VERSION "STEPFOC V109"

NS_ :

BS_:

BU_: Host Driver0 Driver1 Driver2 Driver3 Driver4 Driver5 Driver6 Driver7 Driver8 Driver9 Driver10 Driver11 Driver12 Driver13

BO_ 4 Send_data_pack_1_N0: 8 Host
 SG_ Position_setpoint : 7|24@0- (1,0) [-8388608|8388607] "" Driver0
 SG_ Speed_feedforward : 31|24@0- (1,0) [-8388608|8388607] "" Driver0
 SG_ Current_feedforward : 55|16@0- (1,0) [-32768|32767] "" Driver0

BO_ 8 Send_data_pack_PD_N0: 8 Host
 SG_ Position_setpoint : 7|24@0- (1,0) [-8388608|8388607] "" Driver0
 SG_ Speed_setpoint : 31|24@0- (1,0) [-8388608|8388607] "" Driver0
 SG_ Current_feedforward : 55|16@0- (1,0) [-32768|32767] "" Driver0

BO_ 62 Send_data_pack_HALL_N0: 4 Host
 SG_ Speed : 7|24@0- (1,0) [-8388608|8388607] "" Driver0
 SG_ Trigger : 31|8@0+ (1,0) [0|255] "" Driver0

BO_ 6 Respond_data_pack_1_N0: 8 Driver0
 SG_ position : 7|24@0- (1,0) [-8388608|8388607] "" Host
 SG_ speed : 31|24@0- (1,0) [-8388608|8388607] "" Host
 SG_ current : 55|16@0- (1,0) [-32768|32767] "" Host

BO_ 7 Respond_data_pack_1_N0_Fault: 8 Driver0
 SG_ position : 7|24@0- (1,0) [-8388608|8388607] "" Host
 SG_ speed : 31|24@0- (1,0) [-8388608|8388607] "" Host
 SG_ current : 55|16@0- (1,0) [-32768|32767] "" Host

BO_ 64 Respond_data_hall_N0: 4 Driver0
 SG_ position : 7|24@0- (1,0) [-8388608|8388607] "" Host
 SG_ HALL_trigger : 31|1@0+ (1,0) [0|1] "" Host
 SG_ additional_pin2 : 30|1@0+ (1,0) [0|1] "" Host
 SG_ hall_index : 29|1@0+ (1,0) [0|1] "" Host

BO_ 65 Respond_data_hall_N0_Fault: 4 Driver0
 SG_ position : 7|24@0- (1,0) [-8388608|8388607] "" Host
 SG_ HALL_trigger : 31|1@0+ (1,0) [0|1] "" Host
 SG_ additional_pin2 : 30|1@0+ (1,0) [0|1] "" Host
 SG_ hall_index : 29|1@0+ (1,0) [0|1] "" Host

BO_ 32 Send_PD_Gains_N0: 8 Host
 SG_ KP : 7|32@0+ (1,0) [-3.402823466e+38|3.402823466e+38] "" Driver0
 SG_ KD : 39|32@0+ (1,0) [-3.402823466e+38|3.402823466e+38] "" Driver0

BO_ 34 Send_Current_Gains_N0: 8 Host
 SG_ Kp_iq : 7|32@0+ (1,0) [-3.402823466e+38|3.402823466e+38] "" Driver0
 SG_ Ki_iq : 39|32@0+ (1,0) [-3.402823466e+38|3.402823466e+38] "" Driver0

BO_ 36 Send_Velocity_Gains_N0: 8 Host
 SG_ Kpv : 7|32@0+ (1,0) [-3.402823466e+38|3.402823466e+38] "" Driver0
 SG_ Kiv : 39|32@0+ (1,0) [-3.402823466e+38|3.402823466e+38] "" Driver0

BO_ 38 Send_Position_Gains_N0: 4 Host
 SG_ Kpp : 7|32@0+ (1,0) [-3.402823466e+38|3.402823466e+38] "" Driver0

BO_ 40 Send_Limits_N0: 8 Host
 SG_ Speed_limit : 7|32@0+ (1,0) [-3.402823466e+38|3.402823466e+38] "" Driver0
 SG_ Current_limit : 39|32@0+ (1,0) [-3.402823466e+38|3.402823466e+38] "" Driver0

BO_ 44 Send_Kt_N0: 4 Host
 SG_ Kt : 7|32@0+ (1,0) [-3.402823466e+38|3.402823466e+38] "" Driver0

BO_ 68 Send_Voltage_Limit_N0: 4 Host
 SG_ Voltage_limit : 7|32@0- (1,0) [-2147483648|2147483647] "" Driver0

BO_ 20 Send_Respond_Ping_N0: 0 Driver0

BO_ 21 Send_Respond_Ping_N0_Fault: 0 Driver0

BO_ 46 Send_Respond_Temperature_N0: 2 Driver0
 SG_ temperature : 7|16@0- (1,0) [-32768|32767] "" Host

BO_ 47 Send_Respond_Temperatur_N0_Fault: 2 Driver0
 SG_ temperature : 7|16@0- (1,0) [-32768|32767] "" Host

BO_ 48 Send_Respond_Voltage_N0: 2 Driver0
 SG_ voltage : 7|16@0+ (1,0) [0|65535] "" Host

BO_ 49 Send_Respond_Voltage_N0_Fault: 2 Driver0
 SG_ voltage : 7|16@0+ (1,0) [0|65535] "" Host

BO_ 50 Send_Respond_Device_Info_N0: 7 Driver0
 SG_ HARDWARE_VERSION : 7|8@0+ (1,0) [0|255] "" Host
 SG_ BATCH_DATE : 15|8@0+ (1,0) [0|255] "" Host
 SG_ SOFTWARE_VERSION : 23|8@0+ (1,0) [0|255] "" Host
 SG_ SERIAL_NUMBER : 31|32@0+ (1,0) [0|4294967295] "" Host

BO_ 51 Send_Respond_Device_Inf_N0_Fault: 7 Driver0
 SG_ HARDWARE_VERSION : 7|8@0+ (1,0) [0|255] "" Host
 SG_ BATCH_DATE : 15|8@0+ (1,0) [0|255] "" Host
 SG_ SOFTWARE_VERSION : 23|8@0+ (1,0) [0|255] "" Host
 SG_ SERIAL_NUMBER : 31|32@0+ (1,0) [0|4294967295] "" Host

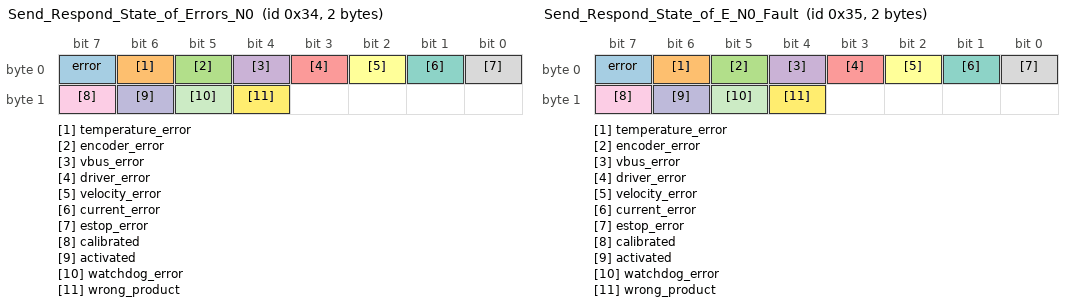
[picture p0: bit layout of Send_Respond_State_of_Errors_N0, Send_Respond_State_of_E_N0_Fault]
BO_ 52 Send_Respond_State_of_Errors_N0: 2 Driver0
 SG_ error : 7|1@0+ (1,0) [0|1] "" Host
 SG_ temperature_error : 6|1@0+ (1,0) [0|1] "" Host
 SG_ encoder_error : 5|1@0+ (1,0) [0|1] "" Host
 SG_ vbus_error : 4|1@0+ (1,0) [0|1] "" Host
 SG_ driver_error : 3|1@0+ (1,0) [0|1] "" Host
 SG_ velocity_error : 2|1@0+ (1,0) [0|1] "" Host
 SG_ current_error : 1|1@0+ (1,0) [0|1] "" Host
 SG_ estop_error : 0|1@0+ (1,0) [0|1] "" Host
 SG_ calibrated : 15|1@0+ (1,0) [0|1] "" Host
 SG_ activated : 14|1@0+ (1,0) [0|1] "" Host
 SG_ watchdog_error : 13|1@0+ (1,0) [0|1] "" Host
 SG_ wrong_product : 12|1@0+ (1,0) [0|1] "" Host

BO_ 53 Send_Respond_State_of_E_N0_Fault: 2 Driver0
 SG_ error : 7|1@0+ (1,0) [0|1] "" Host
 SG_ temperature_error : 6|1@0+ (1,0) [0|1] "" Host
 SG_ encoder_error : 5|1@0+ (1,0) [0|1] "" Host
 SG_ vbus_error : 4|1@0+ (1,0) [0|1] "" Host
 SG_ driver_error : 3|1@0+ (1,0) [0|1] "" Host
 SG_ velocity_error : 2|1@0+ (1,0) [0|1] "" Host
 SG_ current_error : 1|1@0+ (1,0) [0|1] "" Host
 SG_ estop_error : 0|1@0+ (1,0) [0|1] "" Host
 SG_ calibrated : 15|1@0+ (1,0) [0|1] "" Host
 SG_ activated : 14|1@0+ (1,0) [0|1] "" Host
 SG_ watchdog_error : 13|1@0+ (1,0) [0|1] "" Host
 SG_ wrong_product : 12|1@0+ (1,0) [0|1] "" Host

BO_ 54 Send_Respond_Iq_data_N0: 2 Driver0
 SG_ current : 7|16@0- (1,0) [-32768|32767] "" Host

BO_ 55 Send_Respond_Iq_data_N0_Fault: 2 Driver0
 SG_ current : 7|16@0- (1,0) [-32768|32767] "" Host

BO_ 56 Send_Respond_Encoder_data_N0: 8 Driver0
 SG_ position : 7|32@0- (1,0) [-2147483648|2147483647] "" Host
 SG_ speed : 39|32@0- (1,0) [-2147483648|2147483647] "" Host

BO_ 57 Send_Respond_Encoder_da_N0_Fault: 8 Driver0
 SG_ position : 7|32@0- (1,0) [-2147483648|2147483647] "" Host
 SG_ speed : 39|32@0- (1,0) [-2147483648|2147483647] "" Host

BO_ 66 Send_Respond_Kt_N0: 4 Driver0
 SG_ Kt : 7|32@0+ (1,0) [-3.402823466e+38|3.402823466e+38] "" Host

BO_ 67 Send_Respond_Kt_N0_Fault: 4 Driver0
 SG_ Kt : 7|32@0+ (1,0) [-3.402823466e+38|3.402823466e+38] "" Host

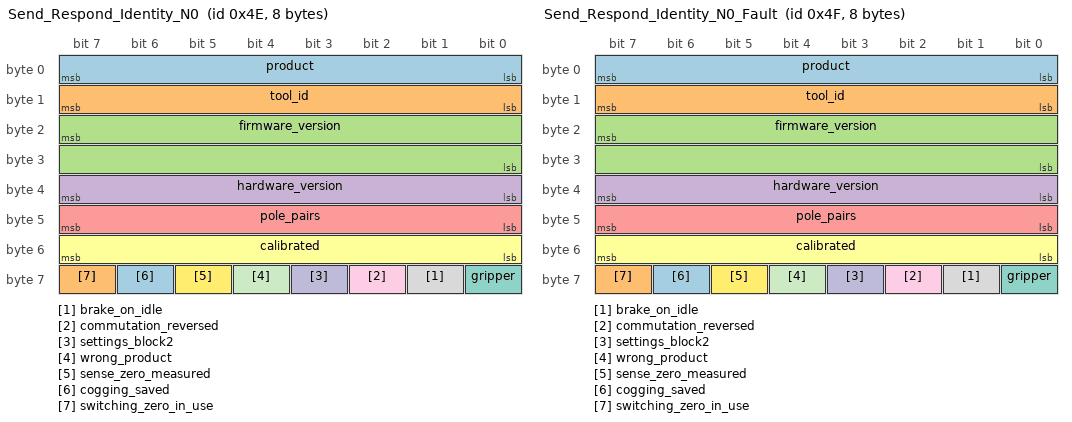
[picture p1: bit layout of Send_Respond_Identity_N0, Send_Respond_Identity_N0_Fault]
BO_ 78 Send_Respond_Identity_N0: 8 Driver0
 SG_ product : 7|8@0+ (1,0) [0|255] "" Host
 SG_ tool_id : 15|8@0+ (1,0) [0|255] "" Host
 SG_ firmware_version : 23|16@0+ (1,0) [0|65535] "" Host
 SG_ hardware_version : 39|8@0+ (1,0) [0|255] "" Host
 SG_ pole_pairs : 47|8@0+ (1,0) [0|255] "" Host
 SG_ calibrated : 55|8@0+ (1,0) [0|255] "" Host
 SG_ gripper : 56|1@0+ (1,0) [0|1] "" Host
 SG_ brake_on_idle : 57|1@0+ (1,0) [0|1] "" Host
 SG_ commutation_reversed : 58|1@0+ (1,0) [0|1] "" Host
 SG_ settings_block2 : 59|1@0+ (1,0) [0|1] "" Host
 SG_ wrong_product : 60|1@0+ (1,0) [0|1] "" Host
 SG_ sense_zero_measured : 61|1@0+ (1,0) [0|1] "" Host
 SG_ cogging_saved : 62|1@0+ (1,0) [0|1] "" Host
 SG_ switching_zero_in_use : 63|1@0+ (1,0) [0|1] "" Host

BO_ 79 Send_Respond_Identity_N0_Fault: 8 Driver0
 SG_ product : 7|8@0+ (1,0) [0|255] "" Host
 SG_ tool_id : 15|8@0+ (1,0) [0|255] "" Host
 SG_ firmware_version : 23|16@0+ (1,0) [0|65535] "" Host
 SG_ hardware_version : 39|8@0+ (1,0) [0|255] "" Host
 SG_ pole_pairs : 47|8@0+ (1,0) [0|255] "" Host
 SG_ calibrated : 55|8@0+ (1,0) [0|255] "" Host
 SG_ gripper : 56|1@0+ (1,0) [0|1] "" Host
 SG_ brake_on_idle : 57|1@0+ (1,0) [0|1] "" Host
 SG_ commutation_reversed : 58|1@0+ (1,0) [0|1] "" Host
 SG_ settings_block2 : 59|1@0+ (1,0) [0|1] "" Host
 SG_ wrong_product : 60|1@0+ (1,0) [0|1] "" Host
 SG_ sense_zero_measured : 61|1@0+ (1,0) [0|1] "" Host
 SG_ cogging_saved : 62|1@0+ (1,0) [0|1] "" Host
 SG_ switching_zero_in_use : 63|1@0+ (1,0) [0|1] "" Host

BO_ 80 Send_Respond_Telemetry_N0: 8 Driver0
 SG_ temperature : 7|16@0- (1,0) [-32768|32767] "" Host
 SG_ voltage : 23|16@0- (1,0) [-32768|32767] "" Host
 SG_ errors_1 : 39|8@0+ (1,0) [0|255] "" Host
 SG_ errors_2 : 47|8@0+ (1,0) [0|255] "" Host
 SG_ current : 55|16@0- (1,0) [-32768|32767] "" Host

BO_ 81 Send_Respond_Telemetry_N0_Fault: 8 Driver0
 SG_ temperature : 7|16@0- (1,0) [-32768|32767] "" Host
 SG_ voltage : 23|16@0- (1,0) [-32768|32767] "" Host
 SG_ errors_1 : 39|8@0+ (1,0) [0|255] "" Host
 SG_ errors_2 : 47|8@0+ (1,0) [0|255] "" Host
 SG_ current : 55|16@0- (1,0) [-32768|32767] "" Host

BO_ 18 Respond_Heartbeat_N0: 0 Driver0

BO_ 19 Respond_Heartbeat_N0_Fault: 0 Driver0

BO_ 22 Send_CAN_ID_N0: 1 Host
 SG_ ID : 7|8@0+ (1,0) [0|255] "" Driver0

BO_ 0 Send_ESTOP_N0: 0 Host

BO_ 24 Send_Idle_N0: 0 Host

BO_ 26 Send_Save_config_N0: 0 Host

BO_ 28 Send_Reset_N0: 0 Host

BO_ 2 Send_Clear_Error_N0: 0 Host

BO_ 30 Send_Watchdog_N0: 5 Host
 SG_ Time : 7|32@0+ (1,0) [0|4294967295] "" Driver0
 SG_ Action : 39|8@0+ (1,0) [0|255] "" Driver0

BO_ 60 Send_Heartbeat_Setup_N0: 4 Host
 SG_ Interval : 7|32@0+ (1,0) [0|4294967295] "" Driver0

BO_ 70 Send_Settings_N0: 2 Host
 SG_ Mask : 7|8@0+ (1,0) [0|255] "" Driver0
 SG_ Value : 15|8@0+ (1,0) [0|255] "" Driver0

BO_ 72 Send_Parameter_N0: 5 Host
 SG_ Parameter : 7|8@0+ (1,0) [0|255] "" Driver0
 SG_ Value : 15|32@0- (1,0) [-2147483648|2147483647] "" Driver0

BO_ 74 Send_Get_Parameter_N0: 1 Host
 SG_ Parameter : 7|8@0+ (1,0) [0|255] "" Driver0

BO_ 76 Respond_Parameter_N0: 5 Driver0
 SG_ parameter : 7|8@0+ (1,0) [0|255] "" Host
 SG_ value : 15|32@0- (1,0) [-2147483648|2147483647] "" Host

BO_ 77 Respond_Parameter_N0_Fault: 5 Driver0
 SG_ parameter : 7|8@0+ (1,0) [0|255] "" Host
 SG_ value : 15|32@0- (1,0) [-2147483648|2147483647] "" Host

BO_ 82 Send_Buffer_Read_N0: 5 Host
 SG_ Kind : 7|8@0+ (1,0) [0|255] "" Driver0
 SG_ First : 15|16@0+ (1,0) [0|65535] "" Driver0
 SG_ Count : 31|16@0+ (1,0) [0|65535] "" Driver0

BO_ 84 Respond_Buffer_Data_N0: 8 Driver0
 SG_ header : 7|16@0+ (1,0) [0|65535] "" Host
 SG_ word_a : 23|16@0- (1,0) [-32768|32767] "" Host
 SG_ word_b : 39|16@0- (1,0) [-32768|32767] "" Host
 SG_ word_c : 55|16@0- (1,0) [-32768|32767] "" Host

BO_ 85 Respond_Buffer_Data_N0_Fault: 8 Driver0
 SG_ header : 7|16@0+ (1,0) [0|65535] "" Host
 SG_ word_a : 23|16@0- (1,0) [-32768|32767] "" Host
 SG_ word_b : 39|16@0- (1,0) [-32768|32767] "" Host
 SG_ word_c : 55|16@0- (1,0) [-32768|32767] "" Host

BO_ 86 Send_Buffer_Write_N0: 8 Host
 SG_ Header : 7|16@0+ (1,0) [0|65535] "" Driver0
 SG_ Word_A : 23|16@0- (1,0) [-32768|32767] "" Driver0
 SG_ Word_B : 39|16@0- (1,0) [-32768|32767] "" Driver0
 SG_ Word_C : 55|16@0- (1,0) [-32768|32767] "" Driver0

BO_ 88 Send_Sound_N0: 8 Host
 SG_ Operation : 7|8@0+ (1,0) [0|255] "" Driver0
 SG_ Channel : 15|8@0+ (1,0) [0|255] "" Driver0
 SG_ A : 23|16@0+ (1,0) [0|65535] "" Driver0
 SG_ B : 39|16@0+ (1,0) [0|65535] "" Driver0
 SG_ C : 55|16@0+ (1,0) [0|65535] "" Driver0

BO_ 90 Send_Sound_Samples_N0: 8 Host
 SG_ Sample_1 : 7|8@0- (1,0) [-128|127] "" Driver0
 SG_ Sample_2 : 15|8@0- (1,0) [-128|127] "" Driver0
 SG_ Sample_3 : 23|8@0- (1,0) [-128|127] "" Driver0
 SG_ Sample_4 : 31|8@0- (1,0) [-128|127] "" Driver0
 SG_ Sample_5 : 39|8@0- (1,0) [-128|127] "" Driver0
 SG_ Sample_6 : 47|8@0- (1,0) [-128|127] "" Driver0
 SG_ Sample_7 : 55|8@0- (1,0) [-128|127] "" Driver0
 SG_ Sample_8 : 63|8@0- (1,0) [-128|127] "" Driver0

BO_ 122 Send_gripper_data_pack_N0: 5 Host
 SG_ Position : 7|8@0+ (1,0) [0|255] "" Driver0
 SG_ Speed : 15|8@0+ (1,0) [0|255] "" Driver0
 SG_ Current : 23|16@0- (1,0) [-32768|32767] "" Driver0
 SG_ Activate : 39|1@0+ (1,0) [0|1] "" Driver0
 SG_ Action : 38|1@0+ (1,0) [0|1] "" Driver0
 SG_ E_stop : 37|1@0+ (1,0) [0|1] "" Driver0
 SG_ Release_direction : 36|1@0+ (1,0) [0|1] "" Driver0

BO_ 124 Send_gripper_calibrate_N0: 0 Host

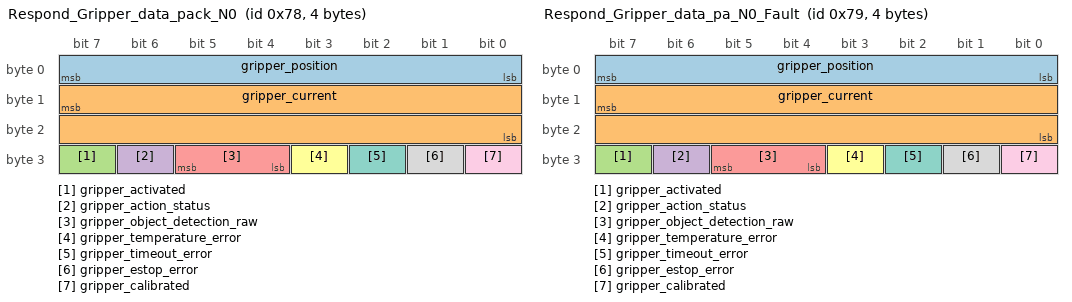
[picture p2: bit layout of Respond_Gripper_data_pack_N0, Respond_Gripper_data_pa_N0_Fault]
BO_ 120 Respond_Gripper_data_pack_N0: 4 Driver0
 SG_ gripper_position : 7|8@0+ (1,0) [0|255] "" Host
 SG_ gripper_current : 15|16@0- (1,0) [-32768|32767] "" Host
 SG_ gripper_activated : 31|1@0+ (1,0) [0|1] "" Host
 SG_ gripper_action_status : 30|1@0+ (1,0) [0|1] "" Host
 SG_ gripper_object_detection_raw : 29|2@0+ (1,0) [0|3] "" Host
 SG_ gripper_temperature_error : 27|1@0+ (1,0) [0|1] "" Host
 SG_ gripper_timeout_error : 26|1@0+ (1,0) [0|1] "" Host
 SG_ gripper_estop_error : 25|1@0+ (1,0) [0|1] "" Host
 SG_ gripper_calibrated : 24|1@0+ (1,0) [0|1] "" Host

BO_ 121 Respond_Gripper_data_pa_N0_Fault: 4 Driver0
 SG_ gripper_position : 7|8@0+ (1,0) [0|255] "" Host
 SG_ gripper_current : 15|16@0- (1,0) [-32768|32767] "" Host
 SG_ gripper_activated : 31|1@0+ (1,0) [0|1] "" Host
 SG_ gripper_action_status : 30|1@0+ (1,0) [0|1] "" Host
 SG_ gripper_object_detection_raw : 29|2@0+ (1,0) [0|3] "" Host
 SG_ gripper_temperature_error : 27|1@0+ (1,0) [0|1] "" Host
 SG_ gripper_timeout_error : 26|1@0+ (1,0) [0|1] "" Host
 SG_ gripper_estop_error : 25|1@0+ (1,0) [0|1] "" Host
 SG_ gripper_calibrated : 24|1@0+ (1,0) [0|1] "" Host

BO_ 132 Send_data_pack_1_N1: 8 Host
 SG_ Position_setpoint : 7|24@0- (1,0) [-8388608|8388607] "" Driver1
 SG_ Speed_feedforward : 31|24@0- (1,0) [-8388608|8388607] "" Driver1
 SG_ Current_feedforward : 55|16@0- (1,0) [-32768|32767] "" Driver1

BO_ 136 Send_data_pack_PD_N1: 8 Host
 SG_ Position_setpoint : 7|24@0- (1,0) [-8388608|8388607] "" Driver1
 SG_ Speed_setpoint : 31|24@0- (1,0) [-8388608|8388607] "" Driver1
 SG_ Current_feedforward : 55|16@0- (1,0) [-32768|32767] "" Driver1

BO_ 190 Send_data_pack_HALL_N1: 4 Host
 SG_ Speed : 7|24@0- (1,0) [-8388608|8388607] "" Driver1
 SG_ Trigger : 31|8@0+ (1,0) [0|255] "" Driver1

BO_ 134 Respond_data_pack_1_N1: 8 Driver1
 SG_ position : 7|24@0- (1,0) [-8388608|8388607] "" Host
 SG_ speed : 31|24@0- (1,0) [-8388608|8388607] "" Host
 SG_ current : 55|16@0- (1,0) [-32768|32767] "" Host

BO_ 135 Respond_data_pack_1_N1_Fault: 8 Driver1
 SG_ position : 7|24@0- (1,0) [-8388608|8388607] "" Host
 SG_ speed : 31|24@0- (1,0) [-8388608|8388607] "" Host
 SG_ current : 55|16@0- (1,0) [-32768|32767] "" Host

BO_ 192 Respond_data_hall_N1: 4 Driver1
 SG_ position : 7|24@0- (1,0) [-8388608|8388607] "" Host
 SG_ HALL_trigger : 31|1@0+ (1,0) [0|1] "" Host
 SG_ additional_pin2 : 30|1@0+ (1,0) [0|1] "" Host
 SG_ hall_index : 29|1@0+ (1,0) [0|1] "" Host

BO_ 193 Respond_data_hall_N1_Fault: 4 Driver1
 SG_ position : 7|24@0- (1,0) [-8388608|8388607] "" Host
 SG_ HALL_trigger : 31|1@0+ (1,0) [0|1] "" Host
 SG_ additional_pin2 : 30|1@0+ (1,0) [0|1] "" Host
 SG_ hall_index : 29|1@0+ (1,0) [0|1] "" Host

BO_ 160 Send_PD_Gains_N1: 8 Host
 SG_ KP : 7|32@0+ (1,0) [-3.402823466e+38|3.402823466e+38] "" Driver1
 SG_ KD : 39|32@0+ (1,0) [-3.402823466e+38|3.402823466e+38] "" Driver1

BO_ 162 Send_Current_Gains_N1: 8 Host
 SG_ Kp_iq : 7|32@0+ (1,0) [-3.402823466e+38|3.402823466e+38] "" Driver1
 SG_ Ki_iq : 39|32@0+ (1,0) [-3.402823466e+38|3.402823466e+38] "" Driver1

BO_ 164 Send_Velocity_Gains_N1: 8 Host
 SG_ Kpv : 7|32@0+ (1,0) [-3.402823466e+38|3.402823466e+38] "" Driver1
 SG_ Kiv : 39|32@0+ (1,0) [-3.402823466e+38|3.402823466e+38] "" Driver1

BO_ 166 Send_Position_Gains_N1: 4 Host
 SG_ Kpp : 7|32@0+ (1,0) [-3.402823466e+38|3.402823466e+38] "" Driver1

BO_ 168 Send_Limits_N1: 8 Host
 SG_ Speed_limit : 7|32@0+ (1,0) [-3.402823466e+38|3.402823466e+38] "" Driver1
 SG_ Current_limit : 39|32@0+ (1,0) [-3.402823466e+38|3.402823466e+38] "" Driver1

BO_ 172 Send_Kt_N1: 4 Host
 SG_ Kt : 7|32@0+ (1,0) [-3.402823466e+38|3.402823466e+38] "" Driver1

BO_ 196 Send_Voltage_Limit_N1: 4 Host
 SG_ Voltage_limit : 7|32@0- (1,0) [-2147483648|2147483647] "" Driver1

BO_ 148 Send_Respond_Ping_N1: 0 Driver1

BO_ 149 Send_Respond_Ping_N1_Fault: 0 Driver1

BO_ 174 Send_Respond_Temperature_N1: 2 Driver1
 SG_ temperature : 7|16@0- (1,0) [-32768|32767] "" Host

BO_ 175 Send_Respond_Temperatur_N1_Fault: 2 Driver1
 SG_ temperature : 7|16@0- (1,0) [-32768|32767] "" Host

BO_ 176 Send_Respond_Voltage_N1: 2 Driver1
 SG_ voltage : 7|16@0+ (1,0) [0|65535] "" Host

BO_ 177 Send_Respond_Voltage_N1_Fault: 2 Driver1
 SG_ voltage : 7|16@0+ (1,0) [0|65535] "" Host

BO_ 178 Send_Respond_Device_Info_N1: 7 Driver1
 SG_ HARDWARE_VERSION : 7|8@0+ (1,0) [0|255] "" Host
 SG_ BATCH_DATE : 15|8@0+ (1,0) [0|255] "" Host
 SG_ SOFTWARE_VERSION : 23|8@0+ (1,0) [0|255] "" Host
 SG_ SERIAL_NUMBER : 31|32@0+ (1,0) [0|4294967295] "" Host

BO_ 179 Send_Respond_Device_Inf_N1_Fault: 7 Driver1
 SG_ HARDWARE_VERSION : 7|8@0+ (1,0) [0|255] "" Host
 SG_ BATCH_DATE : 15|8@0+ (1,0) [0|255] "" Host
 SG_ SOFTWARE_VERSION : 23|8@0+ (1,0) [0|255] "" Host
 SG_ SERIAL_NUMBER : 31|32@0+ (1,0) [0|4294967295] "" Host

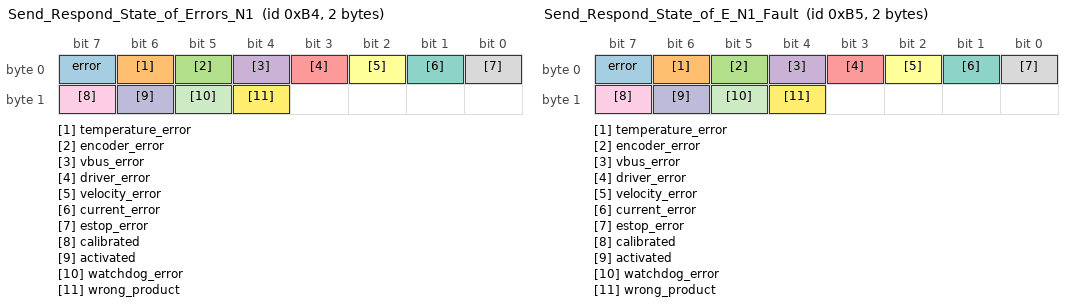
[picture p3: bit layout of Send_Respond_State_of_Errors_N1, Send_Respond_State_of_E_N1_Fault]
BO_ 180 Send_Respond_State_of_Errors_N1: 2 Driver1
 SG_ error : 7|1@0+ (1,0) [0|1] "" Host
 SG_ temperature_error : 6|1@0+ (1,0) [0|1] "" Host
 SG_ encoder_error : 5|1@0+ (1,0) [0|1] "" Host
 SG_ vbus_error : 4|1@0+ (1,0) [0|1] "" Host
 SG_ driver_error : 3|1@0+ (1,0) [0|1] "" Host
 SG_ velocity_error : 2|1@0+ (1,0) [0|1] "" Host
 SG_ current_error : 1|1@0+ (1,0) [0|1] "" Host
 SG_ estop_error : 0|1@0+ (1,0) [0|1] "" Host
 SG_ calibrated : 15|1@0+ (1,0) [0|1] "" Host
 SG_ activated : 14|1@0+ (1,0) [0|1] "" Host
 SG_ watchdog_error : 13|1@0+ (1,0) [0|1] "" Host
 SG_ wrong_product : 12|1@0+ (1,0) [0|1] "" Host

BO_ 181 Send_Respond_State_of_E_N1_Fault: 2 Driver1
 SG_ error : 7|1@0+ (1,0) [0|1] "" Host
 SG_ temperature_error : 6|1@0+ (1,0) [0|1] "" Host
 SG_ encoder_error : 5|1@0+ (1,0) [0|1] "" Host
 SG_ vbus_error : 4|1@0+ (1,0) [0|1] "" Host
 SG_ driver_error : 3|1@0+ (1,0) [0|1] "" Host
 SG_ velocity_error : 2|1@0+ (1,0) [0|1] "" Host
 SG_ current_error : 1|1@0+ (1,0) [0|1] "" Host
 SG_ estop_error : 0|1@0+ (1,0) [0|1] "" Host
 SG_ calibrated : 15|1@0+ (1,0) [0|1] "" Host
 SG_ activated : 14|1@0+ (1,0) [0|1] "" Host
 SG_ watchdog_error : 13|1@0+ (1,0) [0|1] "" Host
 SG_ wrong_product : 12|1@0+ (1,0) [0|1] "" Host

BO_ 182 Send_Respond_Iq_data_N1: 2 Driver1
 SG_ current : 7|16@0- (1,0) [-32768|32767] "" Host

BO_ 183 Send_Respond_Iq_data_N1_Fault: 2 Driver1
 SG_ current : 7|16@0- (1,0) [-32768|32767] "" Host

BO_ 184 Send_Respond_Encoder_data_N1: 8 Driver1
 SG_ position : 7|32@0- (1,0) [-2147483648|2147483647] "" Host
 SG_ speed : 39|32@0- (1,0) [-2147483648|2147483647] "" Host

BO_ 185 Send_Respond_Encoder_da_N1_Fault: 8 Driver1
 SG_ position : 7|32@0- (1,0) [-2147483648|2147483647] "" Host
 SG_ speed : 39|32@0- (1,0) [-2147483648|2147483647] "" Host

BO_ 194 Send_Respond_Kt_N1: 4 Driver1
 SG_ Kt : 7|32@0+ (1,0) [-3.402823466e+38|3.402823466e+38] "" Host

BO_ 195 Send_Respond_Kt_N1_Fault: 4 Driver1
 SG_ Kt : 7|32@0+ (1,0) [-3.402823466e+38|3.402823466e+38] "" Host

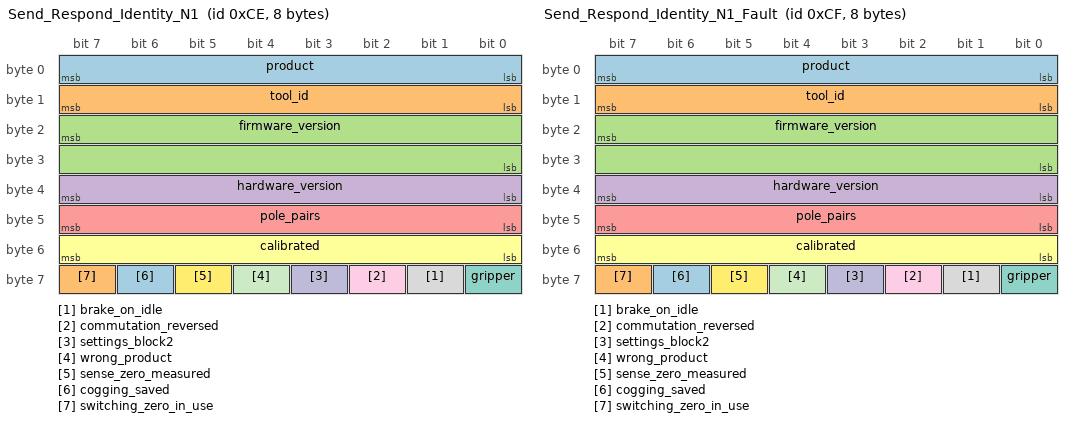
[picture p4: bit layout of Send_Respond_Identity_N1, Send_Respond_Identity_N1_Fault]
BO_ 206 Send_Respond_Identity_N1: 8 Driver1
 SG_ product : 7|8@0+ (1,0) [0|255] "" Host
 SG_ tool_id : 15|8@0+ (1,0) [0|255] "" Host
 SG_ firmware_version : 23|16@0+ (1,0) [0|65535] "" Host
 SG_ hardware_version : 39|8@0+ (1,0) [0|255] "" Host
 SG_ pole_pairs : 47|8@0+ (1,0) [0|255] "" Host
 SG_ calibrated : 55|8@0+ (1,0) [0|255] "" Host
 SG_ gripper : 56|1@0+ (1,0) [0|1] "" Host
 SG_ brake_on_idle : 57|1@0+ (1,0) [0|1] "" Host
 SG_ commutation_reversed : 58|1@0+ (1,0) [0|1] "" Host
 SG_ settings_block2 : 59|1@0+ (1,0) [0|1] "" Host
 SG_ wrong_product : 60|1@0+ (1,0) [0|1] "" Host
 SG_ sense_zero_measured : 61|1@0+ (1,0) [0|1] "" Host
 SG_ cogging_saved : 62|1@0+ (1,0) [0|1] "" Host
 SG_ switching_zero_in_use : 63|1@0+ (1,0) [0|1] "" Host

BO_ 207 Send_Respond_Identity_N1_Fault: 8 Driver1
 SG_ product : 7|8@0+ (1,0) [0|255] "" Host
 SG_ tool_id : 15|8@0+ (1,0) [0|255] "" Host
 SG_ firmware_version : 23|16@0+ (1,0) [0|65535] "" Host
 SG_ hardware_version : 39|8@0+ (1,0) [0|255] "" Host
 SG_ pole_pairs : 47|8@0+ (1,0) [0|255] "" Host
 SG_ calibrated : 55|8@0+ (1,0) [0|255] "" Host
 SG_ gripper : 56|1@0+ (1,0) [0|1] "" Host
 SG_ brake_on_idle : 57|1@0+ (1,0) [0|1] "" Host
 SG_ commutation_reversed : 58|1@0+ (1,0) [0|1] "" Host
 SG_ settings_block2 : 59|1@0+ (1,0) [0|1] "" Host
 SG_ wrong_product : 60|1@0+ (1,0) [0|1] "" Host
 SG_ sense_zero_measured : 61|1@0+ (1,0) [0|1] "" Host
 SG_ cogging_saved : 62|1@0+ (1,0) [0|1] "" Host
 SG_ switching_zero_in_use : 63|1@0+ (1,0) [0|1] "" Host

BO_ 208 Send_Respond_Telemetry_N1: 8 Driver1
 SG_ temperature : 7|16@0- (1,0) [-32768|32767] "" Host
 SG_ voltage : 23|16@0- (1,0) [-32768|32767] "" Host
 SG_ errors_1 : 39|8@0+ (1,0) [0|255] "" Host
 SG_ errors_2 : 47|8@0+ (1,0) [0|255] "" Host
 SG_ current : 55|16@0- (1,0) [-32768|32767] "" Host

BO_ 209 Send_Respond_Telemetry_N1_Fault: 8 Driver1
 SG_ temperature : 7|16@0- (1,0) [-32768|32767] "" Host
 SG_ voltage : 23|16@0- (1,0) [-32768|32767] "" Host
 SG_ errors_1 : 39|8@0+ (1,0) [0|255] "" Host
 SG_ errors_2 : 47|8@0+ (1,0) [0|255] "" Host
 SG_ current : 55|16@0- (1,0) [-32768|32767] "" Host

BO_ 146 Respond_Heartbeat_N1: 0 Driver1

BO_ 147 Respond_Heartbeat_N1_Fault: 0 Driver1

BO_ 150 Send_CAN_ID_N1: 1 Host
 SG_ ID : 7|8@0+ (1,0) [0|255] "" Driver1

BO_ 128 Send_ESTOP_N1: 0 Host

BO_ 152 Send_Idle_N1: 0 Host

BO_ 154 Send_Save_config_N1: 0 Host

BO_ 156 Send_Reset_N1: 0 Host

BO_ 130 Send_Clear_Error_N1: 0 Host

BO_ 158 Send_Watchdog_N1: 5 Host
 SG_ Time : 7|32@0+ (1,0) [0|4294967295] "" Driver1
 SG_ Action : 39|8@0+ (1,0) [0|255] "" Driver1

BO_ 188 Send_Heartbeat_Setup_N1: 4 Host
 SG_ Interval : 7|32@0+ (1,0) [0|4294967295] "" Driver1

BO_ 198 Send_Settings_N1: 2 Host
 SG_ Mask : 7|8@0+ (1,0) [0|255] "" Driver1
 SG_ Value : 15|8@0+ (1,0) [0|255] "" Driver1

BO_ 200 Send_Parameter_N1: 5 Host
 SG_ Parameter : 7|8@0+ (1,0) [0|255] "" Driver1
 SG_ Value : 15|32@0- (1,0) [-2147483648|2147483647] "" Driver1

BO_ 202 Send_Get_Parameter_N1: 1 Host
 SG_ Parameter : 7|8@0+ (1,0) [0|255] "" Driver1

BO_ 204 Respond_Parameter_N1: 5 Driver1
 SG_ parameter : 7|8@0+ (1,0) [0|255] "" Host
 SG_ value : 15|32@0- (1,0) [-2147483648|2147483647] "" Host

BO_ 205 Respond_Parameter_N1_Fault: 5 Driver1
 SG_ parameter : 7|8@0+ (1,0) [0|255] "" Host
 SG_ value : 15|32@0- (1,0) [-2147483648|2147483647] "" Host

BO_ 210 Send_Buffer_Read_N1: 5 Host
 SG_ Kind : 7|8@0+ (1,0) [0|255] "" Driver1
 SG_ First : 15|16@0+ (1,0) [0|65535] "" Driver1
 SG_ Count : 31|16@0+ (1,0) [0|65535] "" Driver1

BO_ 212 Respond_Buffer_Data_N1: 8 Driver1
 SG_ header : 7|16@0+ (1,0) [0|65535] "" Host
 SG_ word_a : 23|16@0- (1,0) [-32768|32767] "" Host
 SG_ word_b : 39|16@0- (1,0) [-32768|32767] "" Host
 SG_ word_c : 55|16@0- (1,0) [-32768|32767] "" Host

BO_ 213 Respond_Buffer_Data_N1_Fault: 8 Driver1
 SG_ header : 7|16@0+ (1,0) [0|65535] "" Host
 SG_ word_a : 23|16@0- (1,0) [-32768|32767] "" Host
 SG_ word_b : 39|16@0- (1,0) [-32768|32767] "" Host
 SG_ word_c : 55|16@0- (1,0) [-32768|32767] "" Host

BO_ 214 Send_Buffer_Write_N1: 8 Host
 SG_ Header : 7|16@0+ (1,0) [0|65535] "" Driver1
 SG_ Word_A : 23|16@0- (1,0) [-32768|32767] "" Driver1
 SG_ Word_B : 39|16@0- (1,0) [-32768|32767] "" Driver1
 SG_ Word_C : 55|16@0- (1,0) [-32768|32767] "" Driver1

BO_ 216 Send_Sound_N1: 8 Host
 SG_ Operation : 7|8@0+ (1,0) [0|255] "" Driver1
 SG_ Channel : 15|8@0+ (1,0) [0|255] "" Driver1
 SG_ A : 23|16@0+ (1,0) [0|65535] "" Driver1
 SG_ B : 39|16@0+ (1,0) [0|65535] "" Driver1
 SG_ C : 55|16@0+ (1,0) [0|65535] "" Driver1

BO_ 218 Send_Sound_Samples_N1: 8 Host
 SG_ Sample_1 : 7|8@0- (1,0) [-128|127] "" Driver1
 SG_ Sample_2 : 15|8@0- (1,0) [-128|127] "" Driver1
 SG_ Sample_3 : 23|8@0- (1,0) [-128|127] "" Driver1
 SG_ Sample_4 : 31|8@0- (1,0) [-128|127] "" Driver1
 SG_ Sample_5 : 39|8@0- (1,0) [-128|127] "" Driver1
 SG_ Sample_6 : 47|8@0- (1,0) [-128|127] "" Driver1
 SG_ Sample_7 : 55|8@0- (1,0) [-128|127] "" Driver1
 SG_ Sample_8 : 63|8@0- (1,0) [-128|127] "" Driver1

BO_ 250 Send_gripper_data_pack_N1: 5 Host
 SG_ Position : 7|8@0+ (1,0) [0|255] "" Driver1
 SG_ Speed : 15|8@0+ (1,0) [0|255] "" Driver1
 SG_ Current : 23|16@0- (1,0) [-32768|32767] "" Driver1
 SG_ Activate : 39|1@0+ (1,0) [0|1] "" Driver1
 SG_ Action : 38|1@0+ (1,0) [0|1] "" Driver1
 SG_ E_stop : 37|1@0+ (1,0) [0|1] "" Driver1
 SG_ Release_direction : 36|1@0+ (1,0) [0|1] "" Driver1

BO_ 252 Send_gripper_calibrate_N1: 0 Host

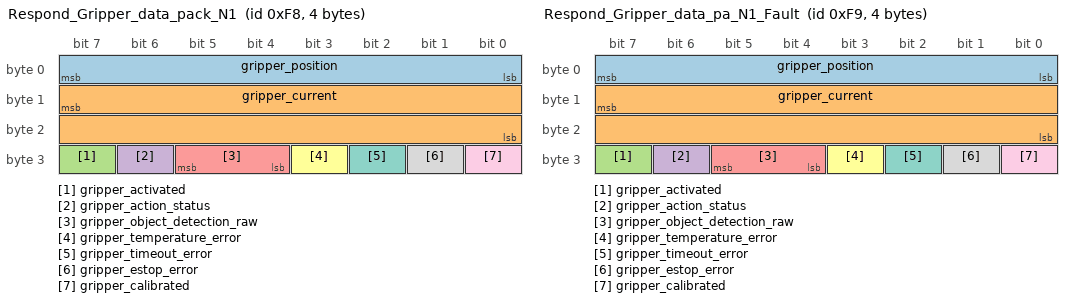
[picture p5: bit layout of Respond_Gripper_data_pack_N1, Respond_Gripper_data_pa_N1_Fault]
BO_ 248 Respond_Gripper_data_pack_N1: 4 Driver1
 SG_ gripper_position : 7|8@0+ (1,0) [0|255] "" Host
 SG_ gripper_current : 15|16@0- (1,0) [-32768|32767] "" Host
 SG_ gripper_activated : 31|1@0+ (1,0) [0|1] "" Host
 SG_ gripper_action_status : 30|1@0+ (1,0) [0|1] "" Host
 SG_ gripper_object_detection_raw : 29|2@0+ (1,0) [0|3] "" Host
 SG_ gripper_temperature_error : 27|1@0+ (1,0) [0|1] "" Host
 SG_ gripper_timeout_error : 26|1@0+ (1,0) [0|1] "" Host
 SG_ gripper_estop_error : 25|1@0+ (1,0) [0|1] "" Host
 SG_ gripper_calibrated : 24|1@0+ (1,0) [0|1] "" Host

BO_ 249 Respond_Gripper_data_pa_N1_Fault: 4 Driver1
 SG_ gripper_position : 7|8@0+ (1,0) [0|255] "" Host
 SG_ gripper_current : 15|16@0- (1,0) [-32768|32767] "" Host
 SG_ gripper_activated : 31|1@0+ (1,0) [0|1] "" Host
 SG_ gripper_action_status : 30|1@0+ (1,0) [0|1] "" Host
 SG_ gripper_object_detection_raw : 29|2@0+ (1,0) [0|3] "" Host
 SG_ gripper_temperature_error : 27|1@0+ (1,0) [0|1] "" Host
 SG_ gripper_timeout_error : 26|1@0+ (1,0) [0|1] "" Host
 SG_ gripper_estop_error : 25|1@0+ (1,0) [0|1] "" Host
 SG_ gripper_calibrated : 24|1@0+ (1,0) [0|1] "" Host

BO_ 260 Send_data_pack_1_N2: 8 Host
 SG_ Position_setpoint : 7|24@0- (1,0) [-8388608|8388607] "" Driver2
 SG_ Speed_feedforward : 31|24@0- (1,0) [-8388608|8388607] "" Driver2
 SG_ Current_feedforward : 55|16@0- (1,0) [-32768|32767] "" Driver2

BO_ 264 Send_data_pack_PD_N2: 8 Host
 SG_ Position_setpoint : 7|24@0- (1,0) [-8388608|8388607] "" Driver2
 SG_ Speed_setpoint : 31|24@0- (1,0) [-8388608|8388607] "" Driver2
 SG_ Current_feedforward : 55|16@0- (1,0) [-32768|32767] "" Driver2

BO_ 318 Send_data_pack_HALL_N2: 4 Host
 SG_ Speed : 7|24@0- (1,0) [-8388608|8388607] "" Driver2
 SG_ Trigger : 31|8@0+ (1,0) [0|255] "" Driver2

BO_ 262 Respond_data_pack_1_N2: 8 Driver2
 SG_ position : 7|24@0- (1,0) [-8388608|8388607] "" Host
 SG_ speed : 31|24@0- (1,0) [-8388608|8388607] "" Host
 SG_ current : 55|16@0- (1,0) [-32768|32767] "" Host

BO_ 263 Respond_data_pack_1_N2_Fault: 8 Driver2
 SG_ position : 7|24@0- (1,0) [-8388608|8388607] "" Host
 SG_ speed : 31|24@0- (1,0) [-8388608|8388607] "" Host
 SG_ current : 55|16@0- (1,0) [-32768|32767] "" Host

BO_ 320 Respond_data_hall_N2: 4 Driver2
 SG_ position : 7|24@0- (1,0) [-8388608|8388607] "" Host
 SG_ HALL_trigger : 31|1@0+ (1,0) [0|1] "" Host
 SG_ additional_pin2 : 30|1@0+ (1,0) [0|1] "" Host
 SG_ hall_index : 29|1@0+ (1,0) [0|1] "" Host

BO_ 321 Respond_data_hall_N2_Fault: 4 Driver2
 SG_ position : 7|24@0- (1,0) [-8388608|8388607] "" Host
 SG_ HALL_trigger : 31|1@0+ (1,0) [0|1] "" Host
 SG_ additional_pin2 : 30|1@0+ (1,0) [0|1] "" Host
 SG_ hall_index : 29|1@0+ (1,0) [0|1] "" Host

BO_ 288 Send_PD_Gains_N2: 8 Host
 SG_ KP : 7|32@0+ (1,0) [-3.402823466e+38|3.402823466e+38] "" Driver2
 SG_ KD : 39|32@0+ (1,0) [-3.402823466e+38|3.402823466e+38] "" Driver2

BO_ 290 Send_Current_Gains_N2: 8 Host
 SG_ Kp_iq : 7|32@0+ (1,0) [-3.402823466e+38|3.402823466e+38] "" Driver2
 SG_ Ki_iq : 39|32@0+ (1,0) [-3.402823466e+38|3.402823466e+38] "" Driver2

BO_ 292 Send_Velocity_Gains_N2: 8 Host
 SG_ Kpv : 7|32@0+ (1,0) [-3.402823466e+38|3.402823466e+38] "" Driver2
 SG_ Kiv : 39|32@0+ (1,0) [-3.402823466e+38|3.402823466e+38] "" Driver2

BO_ 294 Send_Position_Gains_N2: 4 Host
 SG_ Kpp : 7|32@0+ (1,0) [-3.402823466e+38|3.402823466e+38] "" Driver2

BO_ 296 Send_Limits_N2: 8 Host
 SG_ Speed_limit : 7|32@0+ (1,0) [-3.402823466e+38|3.402823466e+38] "" Driver2
 SG_ Current_limit : 39|32@0+ (1,0) [-3.402823466e+38|3.402823466e+38] "" Driver2

BO_ 300 Send_Kt_N2: 4 Host
 SG_ Kt : 7|32@0+ (1,0) [-3.402823466e+38|3.402823466e+38] "" Driver2

BO_ 324 Send_Voltage_Limit_N2: 4 Host
 SG_ Voltage_limit : 7|32@0- (1,0) [-2147483648|2147483647] "" Driver2

BO_ 276 Send_Respond_Ping_N2: 0 Driver2

BO_ 277 Send_Respond_Ping_N2_Fault: 0 Driver2

BO_ 302 Send_Respond_Temperature_N2: 2 Driver2
 SG_ temperature : 7|16@0- (1,0) [-32768|32767] "" Host

BO_ 303 Send_Respond_Temperatur_N2_Fault: 2 Driver2
 SG_ temperature : 7|16@0- (1,0) [-32768|32767] "" Host

BO_ 304 Send_Respond_Voltage_N2: 2 Driver2
 SG_ voltage : 7|16@0+ (1,0) [0|65535] "" Host

BO_ 305 Send_Respond_Voltage_N2_Fault: 2 Driver2
 SG_ voltage : 7|16@0+ (1,0) [0|65535] "" Host

BO_ 306 Send_Respond_Device_Info_N2: 7 Driver2
 SG_ HARDWARE_VERSION : 7|8@0+ (1,0) [0|255] "" Host
 SG_ BATCH_DATE : 15|8@0+ (1,0) [0|255] "" Host
 SG_ SOFTWARE_VERSION : 23|8@0+ (1,0) [0|255] "" Host
 SG_ SERIAL_NUMBER : 31|32@0+ (1,0) [0|4294967295] "" Host

BO_ 307 Send_Respond_Device_Inf_N2_Fault: 7 Driver2
 SG_ HARDWARE_VERSION : 7|8@0+ (1,0) [0|255] "" Host
 SG_ BATCH_DATE : 15|8@0+ (1,0) [0|255] "" Host
 SG_ SOFTWARE_VERSION : 23|8@0+ (1,0) [0|255] "" Host
 SG_ SERIAL_NUMBER : 31|32@0+ (1,0) [0|4294967295] "" Host

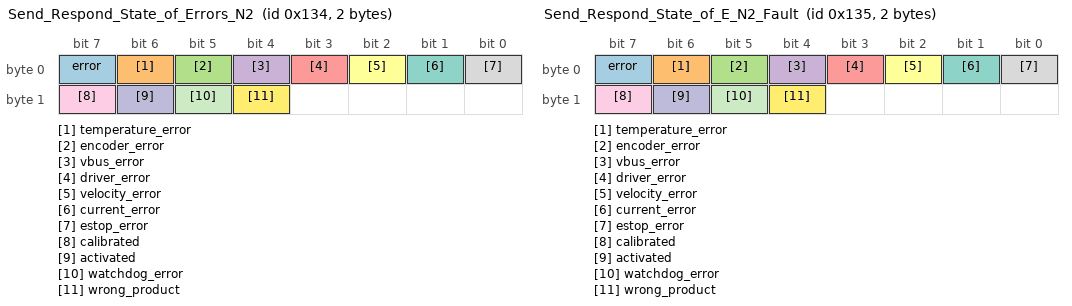
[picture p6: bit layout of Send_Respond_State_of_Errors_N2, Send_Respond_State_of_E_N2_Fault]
BO_ 308 Send_Respond_State_of_Errors_N2: 2 Driver2
 SG_ error : 7|1@0+ (1,0) [0|1] "" Host
 SG_ temperature_error : 6|1@0+ (1,0) [0|1] "" Host
 SG_ encoder_error : 5|1@0+ (1,0) [0|1] "" Host
 SG_ vbus_error : 4|1@0+ (1,0) [0|1] "" Host
 SG_ driver_error : 3|1@0+ (1,0) [0|1] "" Host
 SG_ velocity_error : 2|1@0+ (1,0) [0|1] "" Host
 SG_ current_error : 1|1@0+ (1,0) [0|1] "" Host
 SG_ estop_error : 0|1@0+ (1,0) [0|1] "" Host
 SG_ calibrated : 15|1@0+ (1,0) [0|1] "" Host
 SG_ activated : 14|1@0+ (1,0) [0|1] "" Host
 SG_ watchdog_error : 13|1@0+ (1,0) [0|1] "" Host
 SG_ wrong_product : 12|1@0+ (1,0) [0|1] "" Host

BO_ 309 Send_Respond_State_of_E_N2_Fault: 2 Driver2
 SG_ error : 7|1@0+ (1,0) [0|1] "" Host
 SG_ temperature_error : 6|1@0+ (1,0) [0|1] "" Host
 SG_ encoder_error : 5|1@0+ (1,0) [0|1] "" Host
 SG_ vbus_error : 4|1@0+ (1,0) [0|1] "" Host
 SG_ driver_error : 3|1@0+ (1,0) [0|1] "" Host
 SG_ velocity_error : 2|1@0+ (1,0) [0|1] "" Host
 SG_ current_error : 1|1@0+ (1,0) [0|1] "" Host
 SG_ estop_error : 0|1@0+ (1,0) [0|1] "" Host
 SG_ calibrated : 15|1@0+ (1,0) [0|1] "" Host
 SG_ activated : 14|1@0+ (1,0) [0|1] "" Host
 SG_ watchdog_error : 13|1@0+ (1,0) [0|1] "" Host
 SG_ wrong_product : 12|1@0+ (1,0) [0|1] "" Host

BO_ 310 Send_Respond_Iq_data_N2: 2 Driver2
 SG_ current : 7|16@0- (1,0) [-32768|32767] "" Host

BO_ 311 Send_Respond_Iq_data_N2_Fault: 2 Driver2
 SG_ current : 7|16@0- (1,0) [-32768|32767] "" Host

BO_ 312 Send_Respond_Encoder_data_N2: 8 Driver2
 SG_ position : 7|32@0- (1,0) [-2147483648|2147483647] "" Host
 SG_ speed : 39|32@0- (1,0) [-2147483648|2147483647] "" Host

BO_ 313 Send_Respond_Encoder_da_N2_Fault: 8 Driver2
 SG_ position : 7|32@0- (1,0) [-2147483648|2147483647] "" Host
 SG_ speed : 39|32@0- (1,0) [-2147483648|2147483647] "" Host

BO_ 322 Send_Respond_Kt_N2: 4 Driver2
 SG_ Kt : 7|32@0+ (1,0) [-3.402823466e+38|3.402823466e+38] "" Host

BO_ 323 Send_Respond_Kt_N2_Fault: 4 Driver2
 SG_ Kt : 7|32@0+ (1,0) [-3.402823466e+38|3.402823466e+38] "" Host

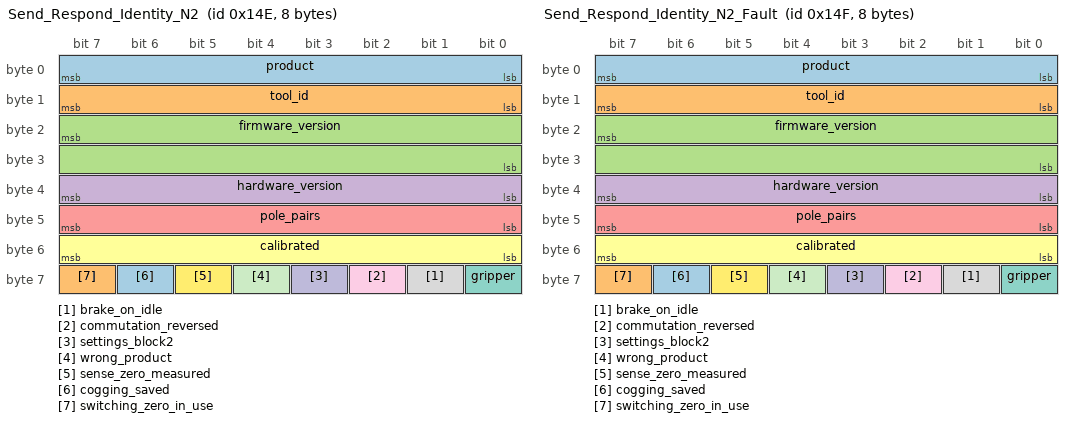
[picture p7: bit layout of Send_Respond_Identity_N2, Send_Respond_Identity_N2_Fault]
BO_ 334 Send_Respond_Identity_N2: 8 Driver2
 SG_ product : 7|8@0+ (1,0) [0|255] "" Host
 SG_ tool_id : 15|8@0+ (1,0) [0|255] "" Host
 SG_ firmware_version : 23|16@0+ (1,0) [0|65535] "" Host
 SG_ hardware_version : 39|8@0+ (1,0) [0|255] "" Host
 SG_ pole_pairs : 47|8@0+ (1,0) [0|255] "" Host
 SG_ calibrated : 55|8@0+ (1,0) [0|255] "" Host
 SG_ gripper : 56|1@0+ (1,0) [0|1] "" Host
 SG_ brake_on_idle : 57|1@0+ (1,0) [0|1] "" Host
 SG_ commutation_reversed : 58|1@0+ (1,0) [0|1] "" Host
 SG_ settings_block2 : 59|1@0+ (1,0) [0|1] "" Host
 SG_ wrong_product : 60|1@0+ (1,0) [0|1] "" Host
 SG_ sense_zero_measured : 61|1@0+ (1,0) [0|1] "" Host
 SG_ cogging_saved : 62|1@0+ (1,0) [0|1] "" Host
 SG_ switching_zero_in_use : 63|1@0+ (1,0) [0|1] "" Host

BO_ 335 Send_Respond_Identity_N2_Fault: 8 Driver2
 SG_ product : 7|8@0+ (1,0) [0|255] "" Host
 SG_ tool_id : 15|8@0+ (1,0) [0|255] "" Host
 SG_ firmware_version : 23|16@0+ (1,0) [0|65535] "" Host
 SG_ hardware_version : 39|8@0+ (1,0) [0|255] "" Host
 SG_ pole_pairs : 47|8@0+ (1,0) [0|255] "" Host
 SG_ calibrated : 55|8@0+ (1,0) [0|255] "" Host
 SG_ gripper : 56|1@0+ (1,0) [0|1] "" Host
 SG_ brake_on_idle : 57|1@0+ (1,0) [0|1] "" Host
 SG_ commutation_reversed : 58|1@0+ (1,0) [0|1] "" Host
 SG_ settings_block2 : 59|1@0+ (1,0) [0|1] "" Host
 SG_ wrong_product : 60|1@0+ (1,0) [0|1] "" Host
 SG_ sense_zero_measured : 61|1@0+ (1,0) [0|1] "" Host
 SG_ cogging_saved : 62|1@0+ (1,0) [0|1] "" Host
 SG_ switching_zero_in_use : 63|1@0+ (1,0) [0|1] "" Host

BO_ 336 Send_Respond_Telemetry_N2: 8 Driver2
 SG_ temperature : 7|16@0- (1,0) [-32768|32767] "" Host
 SG_ voltage : 23|16@0- (1,0) [-32768|32767] "" Host
 SG_ errors_1 : 39|8@0+ (1,0) [0|255] "" Host
 SG_ errors_2 : 47|8@0+ (1,0) [0|255] "" Host
 SG_ current : 55|16@0- (1,0) [-32768|32767] "" Host

BO_ 337 Send_Respond_Telemetry_N2_Fault: 8 Driver2
 SG_ temperature : 7|16@0- (1,0) [-32768|32767] "" Host
 SG_ voltage : 23|16@0- (1,0) [-32768|32767] "" Host
 SG_ errors_1 : 39|8@0+ (1,0) [0|255] "" Host
 SG_ errors_2 : 47|8@0+ (1,0) [0|255] "" Host
 SG_ current : 55|16@0- (1,0) [-32768|32767] "" Host

BO_ 274 Respond_Heartbeat_N2: 0 Driver2

BO_ 275 Respond_Heartbeat_N2_Fault: 0 Driver2

BO_ 278 Send_CAN_ID_N2: 1 Host
 SG_ ID : 7|8@0+ (1,0) [0|255] "" Driver2

BO_ 256 Send_ESTOP_N2: 0 Host

BO_ 280 Send_Idle_N2: 0 Host

BO_ 282 Send_Save_config_N2: 0 Host

BO_ 284 Send_Reset_N2: 0 Host

BO_ 258 Send_Clear_Error_N2: 0 Host

BO_ 286 Send_Watchdog_N2: 5 Host
 SG_ Time : 7|32@0+ (1,0) [0|4294967295] "" Driver2
 SG_ Action : 39|8@0+ (1,0) [0|255] "" Driver2

BO_ 316 Send_Heartbeat_Setup_N2: 4 Host
 SG_ Interval : 7|32@0+ (1,0) [0|4294967295] "" Driver2

BO_ 326 Send_Settings_N2: 2 Host
 SG_ Mask : 7|8@0+ (1,0) [0|255] "" Driver2
 SG_ Value : 15|8@0+ (1,0) [0|255] "" Driver2

BO_ 328 Send_Parameter_N2: 5 Host
 SG_ Parameter : 7|8@0+ (1,0) [0|255] "" Driver2
 SG_ Value : 15|32@0- (1,0) [-2147483648|2147483647] "" Driver2

BO_ 330 Send_Get_Parameter_N2: 1 Host
 SG_ Parameter : 7|8@0+ (1,0) [0|255] "" Driver2

BO_ 332 Respond_Parameter_N2: 5 Driver2
 SG_ parameter : 7|8@0+ (1,0) [0|255] "" Host
 SG_ value : 15|32@0- (1,0) [-2147483648|2147483647] "" Host

BO_ 333 Respond_Parameter_N2_Fault: 5 Driver2
 SG_ parameter : 7|8@0+ (1,0) [0|255] "" Host
 SG_ value : 15|32@0- (1,0) [-2147483648|2147483647] "" Host

BO_ 338 Send_Buffer_Read_N2: 5 Host
 SG_ Kind : 7|8@0+ (1,0) [0|255] "" Driver2
 SG_ First : 15|16@0+ (1,0) [0|65535] "" Driver2
 SG_ Count : 31|16@0+ (1,0) [0|65535] "" Driver2

BO_ 340 Respond_Buffer_Data_N2: 8 Driver2
 SG_ header : 7|16@0+ (1,0) [0|65535] "" Host
 SG_ word_a : 23|16@0- (1,0) [-32768|32767] "" Host
 SG_ word_b : 39|16@0- (1,0) [-32768|32767] "" Host
 SG_ word_c : 55|16@0- (1,0) [-32768|32767] "" Host

BO_ 341 Respond_Buffer_Data_N2_Fault: 8 Driver2
 SG_ header : 7|16@0+ (1,0) [0|65535] "" Host
 SG_ word_a : 23|16@0- (1,0) [-32768|32767] "" Host
 SG_ word_b : 39|16@0- (1,0) [-32768|32767] "" Host
 SG_ word_c : 55|16@0- (1,0) [-32768|32767] "" Host

BO_ 342 Send_Buffer_Write_N2: 8 Host
 SG_ Header : 7|16@0+ (1,0) [0|65535] "" Driver2
 SG_ Word_A : 23|16@0- (1,0) [-32768|32767] "" Driver2
 SG_ Word_B : 39|16@0- (1,0) [-32768|32767] "" Driver2
 SG_ Word_C : 55|16@0- (1,0) [-32768|32767] "" Driver2

BO_ 344 Send_Sound_N2: 8 Host
 SG_ Operation : 7|8@0+ (1,0) [0|255] "" Driver2
 SG_ Channel : 15|8@0+ (1,0) [0|255] "" Driver2
 SG_ A : 23|16@0+ (1,0) [0|65535] "" Driver2
 SG_ B : 39|16@0+ (1,0) [0|65535] "" Driver2
 SG_ C : 55|16@0+ (1,0) [0|65535] "" Driver2

BO_ 346 Send_Sound_Samples_N2: 8 Host
 SG_ Sample_1 : 7|8@0- (1,0) [-128|127] "" Driver2
 SG_ Sample_2 : 15|8@0- (1,0) [-128|127] "" Driver2
 SG_ Sample_3 : 23|8@0- (1,0) [-128|127] "" Driver2
 SG_ Sample_4 : 31|8@0- (1,0) [-128|127] "" Driver2
 SG_ Sample_5 : 39|8@0- (1,0) [-128|127] "" Driver2
 SG_ Sample_6 : 47|8@0- (1,0) [-128|127] "" Driver2
 SG_ Sample_7 : 55|8@0- (1,0) [-128|127] "" Driver2
 SG_ Sample_8 : 63|8@0- (1,0) [-128|127] "" Driver2

BO_ 378 Send_gripper_data_pack_N2: 5 Host
 SG_ Position : 7|8@0+ (1,0) [0|255] "" Driver2
 SG_ Speed : 15|8@0+ (1,0) [0|255] "" Driver2
 SG_ Current : 23|16@0- (1,0) [-32768|32767] "" Driver2
 SG_ Activate : 39|1@0+ (1,0) [0|1] "" Driver2
 SG_ Action : 38|1@0+ (1,0) [0|1] "" Driver2
 SG_ E_stop : 37|1@0+ (1,0) [0|1] "" Driver2
 SG_ Release_direction : 36|1@0+ (1,0) [0|1] "" Driver2

BO_ 380 Send_gripper_calibrate_N2: 0 Host

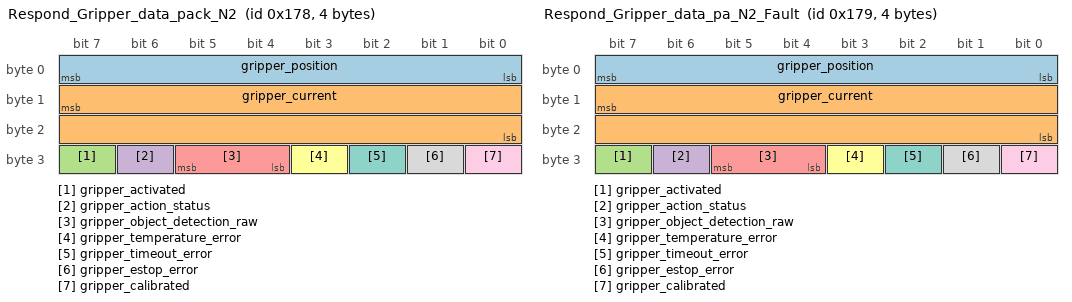
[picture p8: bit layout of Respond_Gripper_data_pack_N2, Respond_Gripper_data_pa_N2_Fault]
BO_ 376 Respond_Gripper_data_pack_N2: 4 Driver2
 SG_ gripper_position : 7|8@0+ (1,0) [0|255] "" Host
 SG_ gripper_current : 15|16@0- (1,0) [-32768|32767] "" Host
 SG_ gripper_activated : 31|1@0+ (1,0) [0|1] "" Host
 SG_ gripper_action_status : 30|1@0+ (1,0) [0|1] "" Host
 SG_ gripper_object_detection_raw : 29|2@0+ (1,0) [0|3] "" Host
 SG_ gripper_temperature_error : 27|1@0+ (1,0) [0|1] "" Host
 SG_ gripper_timeout_error : 26|1@0+ (1,0) [0|1] "" Host
 SG_ gripper_estop_error : 25|1@0+ (1,0) [0|1] "" Host
 SG_ gripper_calibrated : 24|1@0+ (1,0) [0|1] "" Host

BO_ 377 Respond_Gripper_data_pa_N2_Fault: 4 Driver2
 SG_ gripper_position : 7|8@0+ (1,0) [0|255] "" Host
 SG_ gripper_current : 15|16@0- (1,0) [-32768|32767] "" Host
 SG_ gripper_activated : 31|1@0+ (1,0) [0|1] "" Host
 SG_ gripper_action_status : 30|1@0+ (1,0) [0|1] "" Host
 SG_ gripper_object_detection_raw : 29|2@0+ (1,0) [0|3] "" Host
 SG_ gripper_temperature_error : 27|1@0+ (1,0) [0|1] "" Host
 SG_ gripper_timeout_error : 26|1@0+ (1,0) [0|1] "" Host
 SG_ gripper_estop_error : 25|1@0+ (1,0) [0|1] "" Host
 SG_ gripper_calibrated : 24|1@0+ (1,0) [0|1] "" Host

BO_ 388 Send_data_pack_1_N3: 8 Host
 SG_ Position_setpoint : 7|24@0- (1,0) [-8388608|8388607] "" Driver3
 SG_ Speed_feedforward : 31|24@0- (1,0) [-8388608|8388607] "" Driver3
 SG_ Current_feedforward : 55|16@0- (1,0) [-32768|32767] "" Driver3

BO_ 392 Send_data_pack_PD_N3: 8 Host
 SG_ Position_setpoint : 7|24@0- (1,0) [-8388608|8388607] "" Driver3
 SG_ Speed_setpoint : 31|24@0- (1,0) [-8388608|8388607] "" Driver3
 SG_ Current_feedforward : 55|16@0- (1,0) [-32768|32767] "" Driver3

BO_ 446 Send_data_pack_HALL_N3: 4 Host
 SG_ Speed : 7|24@0- (1,0) [-8388608|8388607] "" Driver3
 SG_ Trigger : 31|8@0+ (1,0) [0|255] "" Driver3

BO_ 390 Respond_data_pack_1_N3: 8 Driver3
 SG_ position : 7|24@0- (1,0) [-8388608|8388607] "" Host
 SG_ speed : 31|24@0- (1,0) [-8388608|8388607] "" Host
 SG_ current : 55|16@0- (1,0) [-32768|32767] "" Host

BO_ 391 Respond_data_pack_1_N3_Fault: 8 Driver3
 SG_ position : 7|24@0- (1,0) [-8388608|8388607] "" Host
 SG_ speed : 31|24@0- (1,0) [-8388608|8388607] "" Host
 SG_ current : 55|16@0- (1,0) [-32768|32767] "" Host

BO_ 448 Respond_data_hall_N3: 4 Driver3
 SG_ position : 7|24@0- (1,0) [-8388608|8388607] "" Host
 SG_ HALL_trigger : 31|1@0+ (1,0) [0|1] "" Host
 SG_ additional_pin2 : 30|1@0+ (1,0) [0|1] "" Host
 SG_ hall_index : 29|1@0+ (1,0) [0|1] "" Host

BO_ 449 Respond_data_hall_N3_Fault: 4 Driver3
 SG_ position : 7|24@0- (1,0) [-8388608|8388607] "" Host
 SG_ HALL_trigger : 31|1@0+ (1,0) [0|1] "" Host
 SG_ additional_pin2 : 30|1@0+ (1,0) [0|1] "" Host
 SG_ hall_index : 29|1@0+ (1,0) [0|1] "" Host

BO_ 416 Send_PD_Gains_N3: 8 Host
 SG_ KP : 7|32@0+ (1,0) [-3.402823466e+38|3.402823466e+38] "" Driver3
 SG_ KD : 39|32@0+ (1,0) [-3.402823466e+38|3.402823466e+38] "" Driver3

BO_ 418 Send_Current_Gains_N3: 8 Host
 SG_ Kp_iq : 7|32@0+ (1,0) [-3.402823466e+38|3.402823466e+38] "" Driver3
 SG_ Ki_iq : 39|32@0+ (1,0) [-3.402823466e+38|3.402823466e+38] "" Driver3

BO_ 420 Send_Velocity_Gains_N3: 8 Host
 SG_ Kpv : 7|32@0+ (1,0) [-3.402823466e+38|3.402823466e+38] "" Driver3
 SG_ Kiv : 39|32@0+ (1,0) [-3.402823466e+38|3.402823466e+38] "" Driver3

BO_ 422 Send_Position_Gains_N3: 4 Host
 SG_ Kpp : 7|32@0+ (1,0) [-3.402823466e+38|3.402823466e+38] "" Driver3

BO_ 424 Send_Limits_N3: 8 Host
 SG_ Speed_limit : 7|32@0+ (1,0) [-3.402823466e+38|3.402823466e+38] "" Driver3
 SG_ Current_limit : 39|32@0+ (1,0) [-3.402823466e+38|3.402823466e+38] "" Driver3

BO_ 428 Send_Kt_N3: 4 Host
 SG_ Kt : 7|32@0+ (1,0) [-3.402823466e+38|3.402823466e+38] "" Driver3

BO_ 452 Send_Voltage_Limit_N3: 4 Host
 SG_ Voltage_limit : 7|32@0- (1,0) [-2147483648|2147483647] "" Driver3

BO_ 404 Send_Respond_Ping_N3: 0 Driver3

BO_ 405 Send_Respond_Ping_N3_Fault: 0 Driver3

BO_ 430 Send_Respond_Temperature_N3: 2 Driver3
 SG_ temperature : 7|16@0- (1,0) [-32768|32767] "" Host

BO_ 431 Send_Respond_Temperatur_N3_Fault: 2 Driver3
 SG_ temperature : 7|16@0- (1,0) [-32768|32767] "" Host

BO_ 432 Send_Respond_Voltage_N3: 2 Driver3
 SG_ voltage : 7|16@0+ (1,0) [0|65535] "" Host

BO_ 433 Send_Respond_Voltage_N3_Fault: 2 Driver3
 SG_ voltage : 7|16@0+ (1,0) [0|65535] "" Host

BO_ 434 Send_Respond_Device_Info_N3: 7 Driver3
 SG_ HARDWARE_VERSION : 7|8@0+ (1,0) [0|255] "" Host
 SG_ BATCH_DATE : 15|8@0+ (1,0) [0|255] "" Host
 SG_ SOFTWARE_VERSION : 23|8@0+ (1,0) [0|255] "" Host
 SG_ SERIAL_NUMBER : 31|32@0+ (1,0) [0|4294967295] "" Host

BO_ 435 Send_Respond_Device_Inf_N3_Fault: 7 Driver3
 SG_ HARDWARE_VERSION : 7|8@0+ (1,0) [0|255] "" Host
 SG_ BATCH_DATE : 15|8@0+ (1,0) [0|255] "" Host
 SG_ SOFTWARE_VERSION : 23|8@0+ (1,0) [0|255] "" Host
 SG_ SERIAL_NUMBER : 31|32@0+ (1,0) [0|4294967295] "" Host

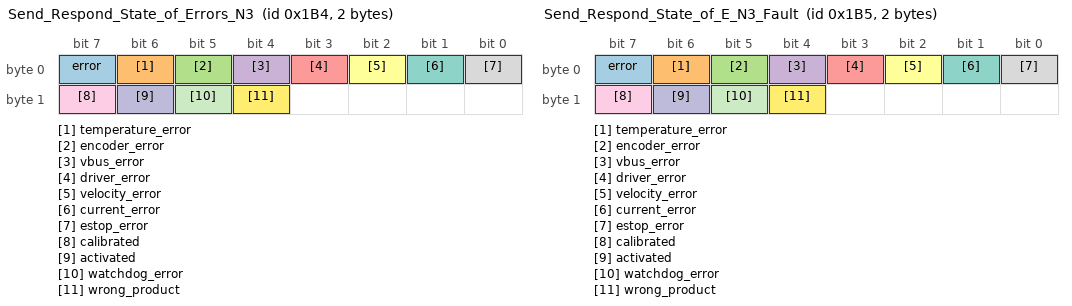
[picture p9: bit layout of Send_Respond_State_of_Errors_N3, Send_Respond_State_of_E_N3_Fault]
BO_ 436 Send_Respond_State_of_Errors_N3: 2 Driver3
 SG_ error : 7|1@0+ (1,0) [0|1] "" Host
 SG_ temperature_error : 6|1@0+ (1,0) [0|1] "" Host
 SG_ encoder_error : 5|1@0+ (1,0) [0|1] "" Host
 SG_ vbus_error : 4|1@0+ (1,0) [0|1] "" Host
 SG_ driver_error : 3|1@0+ (1,0) [0|1] "" Host
 SG_ velocity_error : 2|1@0+ (1,0) [0|1] "" Host
 SG_ current_error : 1|1@0+ (1,0) [0|1] "" Host
 SG_ estop_error : 0|1@0+ (1,0) [0|1] "" Host
 SG_ calibrated : 15|1@0+ (1,0) [0|1] "" Host
 SG_ activated : 14|1@0+ (1,0) [0|1] "" Host
 SG_ watchdog_error : 13|1@0+ (1,0) [0|1] "" Host
 SG_ wrong_product : 12|1@0+ (1,0) [0|1] "" Host

BO_ 437 Send_Respond_State_of_E_N3_Fault: 2 Driver3
 SG_ error : 7|1@0+ (1,0) [0|1] "" Host
 SG_ temperature_error : 6|1@0+ (1,0) [0|1] "" Host
 SG_ encoder_error : 5|1@0+ (1,0) [0|1] "" Host
 SG_ vbus_error : 4|1@0+ (1,0) [0|1] "" Host
 SG_ driver_error : 3|1@0+ (1,0) [0|1] "" Host
 SG_ velocity_error : 2|1@0+ (1,0) [0|1] "" Host
 SG_ current_error : 1|1@0+ (1,0) [0|1] "" Host
 SG_ estop_error : 0|1@0+ (1,0) [0|1] "" Host
 SG_ calibrated : 15|1@0+ (1,0) [0|1] "" Host
 SG_ activated : 14|1@0+ (1,0) [0|1] "" Host
 SG_ watchdog_error : 13|1@0+ (1,0) [0|1] "" Host
 SG_ wrong_product : 12|1@0+ (1,0) [0|1] "" Host

BO_ 438 Send_Respond_Iq_data_N3: 2 Driver3
 SG_ current : 7|16@0- (1,0) [-32768|32767] "" Host

BO_ 439 Send_Respond_Iq_data_N3_Fault: 2 Driver3
 SG_ current : 7|16@0- (1,0) [-32768|32767] "" Host

BO_ 440 Send_Respond_Encoder_data_N3: 8 Driver3
 SG_ position : 7|32@0- (1,0) [-2147483648|2147483647] "" Host
 SG_ speed : 39|32@0- (1,0) [-2147483648|2147483647] "" Host

BO_ 441 Send_Respond_Encoder_da_N3_Fault: 8 Driver3
 SG_ position : 7|32@0- (1,0) [-2147483648|2147483647] "" Host
 SG_ speed : 39|32@0- (1,0) [-2147483648|2147483647] "" Host

BO_ 450 Send_Respond_Kt_N3: 4 Driver3
 SG_ Kt : 7|32@0+ (1,0) [-3.402823466e+38|3.402823466e+38] "" Host

BO_ 451 Send_Respond_Kt_N3_Fault: 4 Driver3
 SG_ Kt : 7|32@0+ (1,0) [-3.402823466e+38|3.402823466e+38] "" Host

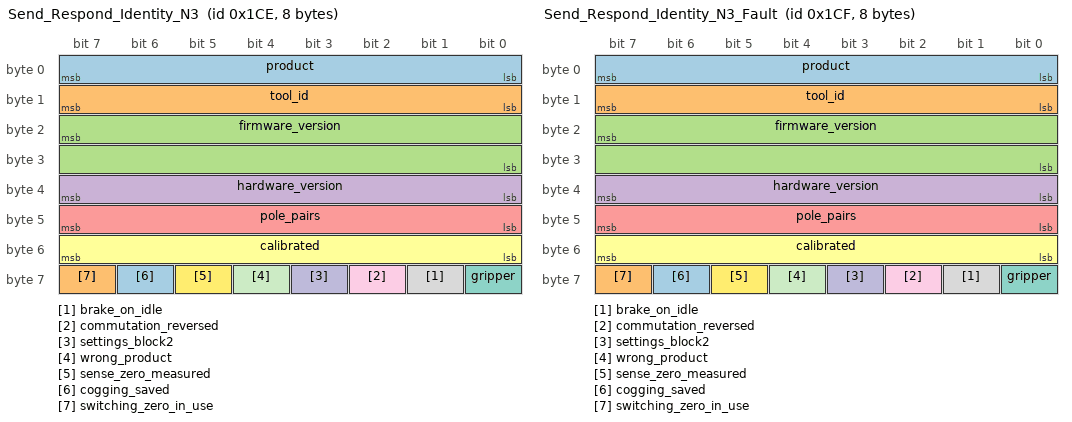
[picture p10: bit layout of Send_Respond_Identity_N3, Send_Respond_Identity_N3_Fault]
BO_ 462 Send_Respond_Identity_N3: 8 Driver3
 SG_ product : 7|8@0+ (1,0) [0|255] "" Host
 SG_ tool_id : 15|8@0+ (1,0) [0|255] "" Host
 SG_ firmware_version : 23|16@0+ (1,0) [0|65535] "" Host
 SG_ hardware_version : 39|8@0+ (1,0) [0|255] "" Host
 SG_ pole_pairs : 47|8@0+ (1,0) [0|255] "" Host
 SG_ calibrated : 55|8@0+ (1,0) [0|255] "" Host
 SG_ gripper : 56|1@0+ (1,0) [0|1] "" Host
 SG_ brake_on_idle : 57|1@0+ (1,0) [0|1] "" Host
 SG_ commutation_reversed : 58|1@0+ (1,0) [0|1] "" Host
 SG_ settings_block2 : 59|1@0+ (1,0) [0|1] "" Host
 SG_ wrong_product : 60|1@0+ (1,0) [0|1] "" Host
 SG_ sense_zero_measured : 61|1@0+ (1,0) [0|1] "" Host
 SG_ cogging_saved : 62|1@0+ (1,0) [0|1] "" Host
 SG_ switching_zero_in_use : 63|1@0+ (1,0) [0|1] "" Host

BO_ 463 Send_Respond_Identity_N3_Fault: 8 Driver3
 SG_ product : 7|8@0+ (1,0) [0|255] "" Host
 SG_ tool_id : 15|8@0+ (1,0) [0|255] "" Host
 SG_ firmware_version : 23|16@0+ (1,0) [0|65535] "" Host
 SG_ hardware_version : 39|8@0+ (1,0) [0|255] "" Host
 SG_ pole_pairs : 47|8@0+ (1,0) [0|255] "" Host
 SG_ calibrated : 55|8@0+ (1,0) [0|255] "" Host
 SG_ gripper : 56|1@0+ (1,0) [0|1] "" Host
 SG_ brake_on_idle : 57|1@0+ (1,0) [0|1] "" Host
 SG_ commutation_reversed : 58|1@0+ (1,0) [0|1] "" Host
 SG_ settings_block2 : 59|1@0+ (1,0) [0|1] "" Host
 SG_ wrong_product : 60|1@0+ (1,0) [0|1] "" Host
 SG_ sense_zero_measured : 61|1@0+ (1,0) [0|1] "" Host
 SG_ cogging_saved : 62|1@0+ (1,0) [0|1] "" Host
 SG_ switching_zero_in_use : 63|1@0+ (1,0) [0|1] "" Host

BO_ 464 Send_Respond_Telemetry_N3: 8 Driver3
 SG_ temperature : 7|16@0- (1,0) [-32768|32767] "" Host
 SG_ voltage : 23|16@0- (1,0) [-32768|32767] "" Host
 SG_ errors_1 : 39|8@0+ (1,0) [0|255] "" Host
 SG_ errors_2 : 47|8@0+ (1,0) [0|255] "" Host
 SG_ current : 55|16@0- (1,0) [-32768|32767] "" Host

BO_ 465 Send_Respond_Telemetry_N3_Fault: 8 Driver3
 SG_ temperature : 7|16@0- (1,0) [-32768|32767] "" Host
 SG_ voltage : 23|16@0- (1,0) [-32768|32767] "" Host
 SG_ errors_1 : 39|8@0+ (1,0) [0|255] "" Host
 SG_ errors_2 : 47|8@0+ (1,0) [0|255] "" Host
 SG_ current : 55|16@0- (1,0) [-32768|32767] "" Host

BO_ 402 Respond_Heartbeat_N3: 0 Driver3

BO_ 403 Respond_Heartbeat_N3_Fault: 0 Driver3

BO_ 406 Send_CAN_ID_N3: 1 Host
 SG_ ID : 7|8@0+ (1,0) [0|255] "" Driver3

BO_ 384 Send_ESTOP_N3: 0 Host

BO_ 408 Send_Idle_N3: 0 Host

BO_ 410 Send_Save_config_N3: 0 Host

BO_ 412 Send_Reset_N3: 0 Host

BO_ 386 Send_Clear_Error_N3: 0 Host

BO_ 414 Send_Watchdog_N3: 5 Host
 SG_ Time : 7|32@0+ (1,0) [0|4294967295] "" Driver3
 SG_ Action : 39|8@0+ (1,0) [0|255] "" Driver3

BO_ 444 Send_Heartbeat_Setup_N3: 4 Host
 SG_ Interval : 7|32@0+ (1,0) [0|4294967295] "" Driver3

BO_ 454 Send_Settings_N3: 2 Host
 SG_ Mask : 7|8@0+ (1,0) [0|255] "" Driver3
 SG_ Value : 15|8@0+ (1,0) [0|255] "" Driver3

BO_ 456 Send_Parameter_N3: 5 Host
 SG_ Parameter : 7|8@0+ (1,0) [0|255] "" Driver3
 SG_ Value : 15|32@0- (1,0) [-2147483648|2147483647] "" Driver3

BO_ 458 Send_Get_Parameter_N3: 1 Host
 SG_ Parameter : 7|8@0+ (1,0) [0|255] "" Driver3

BO_ 460 Respond_Parameter_N3: 5 Driver3
 SG_ parameter : 7|8@0+ (1,0) [0|255] "" Host
 SG_ value : 15|32@0- (1,0) [-2147483648|2147483647] "" Host

BO_ 461 Respond_Parameter_N3_Fault: 5 Driver3
 SG_ parameter : 7|8@0+ (1,0) [0|255] "" Host
 SG_ value : 15|32@0- (1,0) [-2147483648|2147483647] "" Host

BO_ 466 Send_Buffer_Read_N3: 5 Host
 SG_ Kind : 7|8@0+ (1,0) [0|255] "" Driver3
 SG_ First : 15|16@0+ (1,0) [0|65535] "" Driver3
 SG_ Count : 31|16@0+ (1,0) [0|65535] "" Driver3

BO_ 468 Respond_Buffer_Data_N3: 8 Driver3
 SG_ header : 7|16@0+ (1,0) [0|65535] "" Host
 SG_ word_a : 23|16@0- (1,0) [-32768|32767] "" Host
 SG_ word_b : 39|16@0- (1,0) [-32768|32767] "" Host
 SG_ word_c : 55|16@0- (1,0) [-32768|32767] "" Host

BO_ 469 Respond_Buffer_Data_N3_Fault: 8 Driver3
 SG_ header : 7|16@0+ (1,0) [0|65535] "" Host
 SG_ word_a : 23|16@0- (1,0) [-32768|32767] "" Host
 SG_ word_b : 39|16@0- (1,0) [-32768|32767] "" Host
 SG_ word_c : 55|16@0- (1,0) [-32768|32767] "" Host

BO_ 470 Send_Buffer_Write_N3: 8 Host
 SG_ Header : 7|16@0+ (1,0) [0|65535] "" Driver3
 SG_ Word_A : 23|16@0- (1,0) [-32768|32767] "" Driver3
 SG_ Word_B : 39|16@0- (1,0) [-32768|32767] "" Driver3
 SG_ Word_C : 55|16@0- (1,0) [-32768|32767] "" Driver3

BO_ 472 Send_Sound_N3: 8 Host
 SG_ Operation : 7|8@0+ (1,0) [0|255] "" Driver3
 SG_ Channel : 15|8@0+ (1,0) [0|255] "" Driver3
 SG_ A : 23|16@0+ (1,0) [0|65535] "" Driver3
 SG_ B : 39|16@0+ (1,0) [0|65535] "" Driver3
 SG_ C : 55|16@0+ (1,0) [0|65535] "" Driver3

BO_ 474 Send_Sound_Samples_N3: 8 Host
 SG_ Sample_1 : 7|8@0- (1,0) [-128|127] "" Driver3
 SG_ Sample_2 : 15|8@0- (1,0) [-128|127] "" Driver3
 SG_ Sample_3 : 23|8@0- (1,0) [-128|127] "" Driver3
 SG_ Sample_4 : 31|8@0- (1,0) [-128|127] "" Driver3
 SG_ Sample_5 : 39|8@0- (1,0) [-128|127] "" Driver3
 SG_ Sample_6 : 47|8@0- (1,0) [-128|127] "" Driver3
 SG_ Sample_7 : 55|8@0- (1,0) [-128|127] "" Driver3
 SG_ Sample_8 : 63|8@0- (1,0) [-128|127] "" Driver3

BO_ 506 Send_gripper_data_pack_N3: 5 Host
 SG_ Position : 7|8@0+ (1,0) [0|255] "" Driver3
 SG_ Speed : 15|8@0+ (1,0) [0|255] "" Driver3
 SG_ Current : 23|16@0- (1,0) [-32768|32767] "" Driver3
 SG_ Activate : 39|1@0+ (1,0) [0|1] "" Driver3
 SG_ Action : 38|1@0+ (1,0) [0|1] "" Driver3
 SG_ E_stop : 37|1@0+ (1,0) [0|1] "" Driver3
 SG_ Release_direction : 36|1@0+ (1,0) [0|1] "" Driver3

BO_ 508 Send_gripper_calibrate_N3: 0 Host

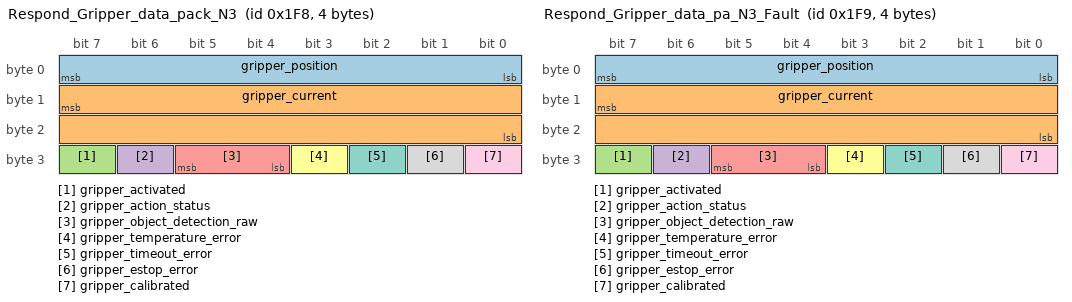
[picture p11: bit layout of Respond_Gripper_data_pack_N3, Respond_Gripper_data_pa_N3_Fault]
BO_ 504 Respond_Gripper_data_pack_N3: 4 Driver3
 SG_ gripper_position : 7|8@0+ (1,0) [0|255] "" Host
 SG_ gripper_current : 15|16@0- (1,0) [-32768|32767] "" Host
 SG_ gripper_activated : 31|1@0+ (1,0) [0|1] "" Host
 SG_ gripper_action_status : 30|1@0+ (1,0) [0|1] "" Host
 SG_ gripper_object_detection_raw : 29|2@0+ (1,0) [0|3] "" Host
 SG_ gripper_temperature_error : 27|1@0+ (1,0) [0|1] "" Host
 SG_ gripper_timeout_error : 26|1@0+ (1,0) [0|1] "" Host
 SG_ gripper_estop_error : 25|1@0+ (1,0) [0|1] "" Host
 SG_ gripper_calibrated : 24|1@0+ (1,0) [0|1] "" Host

BO_ 505 Respond_Gripper_data_pa_N3_Fault: 4 Driver3
 SG_ gripper_position : 7|8@0+ (1,0) [0|255] "" Host
 SG_ gripper_current : 15|16@0- (1,0) [-32768|32767] "" Host
 SG_ gripper_activated : 31|1@0+ (1,0) [0|1] "" Host
 SG_ gripper_action_status : 30|1@0+ (1,0) [0|1] "" Host
 SG_ gripper_object_detection_raw : 29|2@0+ (1,0) [0|3] "" Host
 SG_ gripper_temperature_error : 27|1@0+ (1,0) [0|1] "" Host
 SG_ gripper_timeout_error : 26|1@0+ (1,0) [0|1] "" Host
 SG_ gripper_estop_error : 25|1@0+ (1,0) [0|1] "" Host
 SG_ gripper_calibrated : 24|1@0+ (1,0) [0|1] "" Host

BO_ 516 Send_data_pack_1_N4: 8 Host
 SG_ Position_setpoint : 7|24@0- (1,0) [-8388608|8388607] "" Driver4
 SG_ Speed_feedforward : 31|24@0- (1,0) [-8388608|8388607] "" Driver4
 SG_ Current_feedforward : 55|16@0- (1,0) [-32768|32767] "" Driver4

BO_ 520 Send_data_pack_PD_N4: 8 Host
 SG_ Position_setpoint : 7|24@0- (1,0) [-8388608|8388607] "" Driver4
 SG_ Speed_setpoint : 31|24@0- (1,0) [-8388608|8388607] "" Driver4
 SG_ Current_feedforward : 55|16@0- (1,0) [-32768|32767] "" Driver4

BO_ 574 Send_data_pack_HALL_N4: 4 Host
 SG_ Speed : 7|24@0- (1,0) [-8388608|8388607] "" Driver4
 SG_ Trigger : 31|8@0+ (1,0) [0|255] "" Driver4

BO_ 518 Respond_data_pack_1_N4: 8 Driver4
 SG_ position : 7|24@0- (1,0) [-8388608|8388607] "" Host
 SG_ speed : 31|24@0- (1,0) [-8388608|8388607] "" Host
 SG_ current : 55|16@0- (1,0) [-32768|32767] "" Host

BO_ 519 Respond_data_pack_1_N4_Fault: 8 Driver4
 SG_ position : 7|24@0- (1,0) [-8388608|8388607] "" Host
 SG_ speed : 31|24@0- (1,0) [-8388608|8388607] "" Host
 SG_ current : 55|16@0- (1,0) [-32768|32767] "" Host

BO_ 576 Respond_data_hall_N4: 4 Driver4
 SG_ position : 7|24@0- (1,0) [-8388608|8388607] "" Host
 SG_ HALL_trigger : 31|1@0+ (1,0) [0|1] "" Host
 SG_ additional_pin2 : 30|1@0+ (1,0) [0|1] "" Host
 SG_ hall_index : 29|1@0+ (1,0) [0|1] "" Host

BO_ 577 Respond_data_hall_N4_Fault: 4 Driver4
 SG_ position : 7|24@0- (1,0) [-8388608|8388607] "" Host
 SG_ HALL_trigger : 31|1@0+ (1,0) [0|1] "" Host
 SG_ additional_pin2 : 30|1@0+ (1,0) [0|1] "" Host
 SG_ hall_index : 29|1@0+ (1,0) [0|1] "" Host

BO_ 544 Send_PD_Gains_N4: 8 Host
 SG_ KP : 7|32@0+ (1,0) [-3.402823466e+38|3.402823466e+38] "" Driver4
 SG_ KD : 39|32@0+ (1,0) [-3.402823466e+38|3.402823466e+38] "" Driver4

BO_ 546 Send_Current_Gains_N4: 8 Host
 SG_ Kp_iq : 7|32@0+ (1,0) [-3.402823466e+38|3.402823466e+38] "" Driver4
 SG_ Ki_iq : 39|32@0+ (1,0) [-3.402823466e+38|3.402823466e+38] "" Driver4

BO_ 548 Send_Velocity_Gains_N4: 8 Host
 SG_ Kpv : 7|32@0+ (1,0) [-3.402823466e+38|3.402823466e+38] "" Driver4
 SG_ Kiv : 39|32@0+ (1,0) [-3.402823466e+38|3.402823466e+38] "" Driver4

BO_ 550 Send_Position_Gains_N4: 4 Host
 SG_ Kpp : 7|32@0+ (1,0) [-3.402823466e+38|3.402823466e+38] "" Driver4

BO_ 552 Send_Limits_N4: 8 Host
 SG_ Speed_limit : 7|32@0+ (1,0) [-3.402823466e+38|3.402823466e+38] "" Driver4
 SG_ Current_limit : 39|32@0+ (1,0) [-3.402823466e+38|3.402823466e+38] "" Driver4

BO_ 556 Send_Kt_N4: 4 Host
 SG_ Kt : 7|32@0+ (1,0) [-3.402823466e+38|3.402823466e+38] "" Driver4

BO_ 580 Send_Voltage_Limit_N4: 4 Host
 SG_ Voltage_limit : 7|32@0- (1,0) [-2147483648|2147483647] "" Driver4

BO_ 532 Send_Respond_Ping_N4: 0 Driver4

BO_ 533 Send_Respond_Ping_N4_Fault: 0 Driver4

BO_ 558 Send_Respond_Temperature_N4: 2 Driver4
 SG_ temperature : 7|16@0- (1,0) [-32768|32767] "" Host

BO_ 559 Send_Respond_Temperatur_N4_Fault: 2 Driver4
 SG_ temperature : 7|16@0- (1,0) [-32768|32767] "" Host

BO_ 560 Send_Respond_Voltage_N4: 2 Driver4
 SG_ voltage : 7|16@0+ (1,0) [0|65535] "" Host

BO_ 561 Send_Respond_Voltage_N4_Fault: 2 Driver4
 SG_ voltage : 7|16@0+ (1,0) [0|65535] "" Host

BO_ 562 Send_Respond_Device_Info_N4: 7 Driver4
 SG_ HARDWARE_VERSION : 7|8@0+ (1,0) [0|255] "" Host
 SG_ BATCH_DATE : 15|8@0+ (1,0) [0|255] "" Host
 SG_ SOFTWARE_VERSION : 23|8@0+ (1,0) [0|255] "" Host
 SG_ SERIAL_NUMBER : 31|32@0+ (1,0) [0|4294967295] "" Host

BO_ 563 Send_Respond_Device_Inf_N4_Fault: 7 Driver4
 SG_ HARDWARE_VERSION : 7|8@0+ (1,0) [0|255] "" Host
 SG_ BATCH_DATE : 15|8@0+ (1,0) [0|255] "" Host
 SG_ SOFTWARE_VERSION : 23|8@0+ (1,0) [0|255] "" Host
 SG_ SERIAL_NUMBER : 31|32@0+ (1,0) [0|4294967295] "" Host

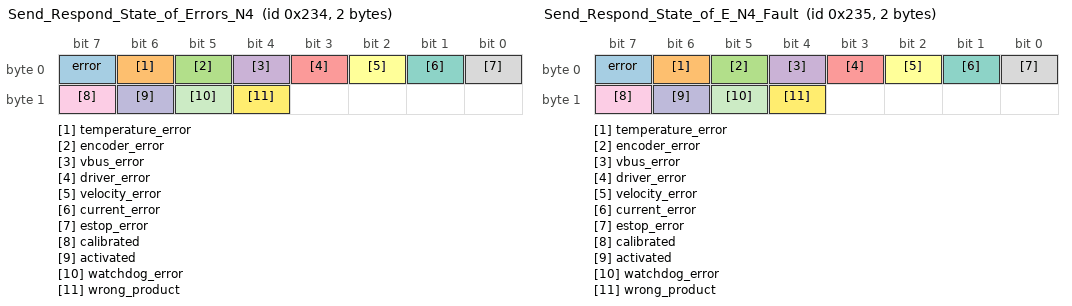
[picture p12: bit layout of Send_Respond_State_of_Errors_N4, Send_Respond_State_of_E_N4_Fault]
BO_ 564 Send_Respond_State_of_Errors_N4: 2 Driver4
 SG_ error : 7|1@0+ (1,0) [0|1] "" Host
 SG_ temperature_error : 6|1@0+ (1,0) [0|1] "" Host
 SG_ encoder_error : 5|1@0+ (1,0) [0|1] "" Host
 SG_ vbus_error : 4|1@0+ (1,0) [0|1] "" Host
 SG_ driver_error : 3|1@0+ (1,0) [0|1] "" Host
 SG_ velocity_error : 2|1@0+ (1,0) [0|1] "" Host
 SG_ current_error : 1|1@0+ (1,0) [0|1] "" Host
 SG_ estop_error : 0|1@0+ (1,0) [0|1] "" Host
 SG_ calibrated : 15|1@0+ (1,0) [0|1] "" Host
 SG_ activated : 14|1@0+ (1,0) [0|1] "" Host
 SG_ watchdog_error : 13|1@0+ (1,0) [0|1] "" Host
 SG_ wrong_product : 12|1@0+ (1,0) [0|1] "" Host

BO_ 565 Send_Respond_State_of_E_N4_Fault: 2 Driver4
 SG_ error : 7|1@0+ (1,0) [0|1] "" Host
 SG_ temperature_error : 6|1@0+ (1,0) [0|1] "" Host
 SG_ encoder_error : 5|1@0+ (1,0) [0|1] "" Host
 SG_ vbus_error : 4|1@0+ (1,0) [0|1] "" Host
 SG_ driver_error : 3|1@0+ (1,0) [0|1] "" Host
 SG_ velocity_error : 2|1@0+ (1,0) [0|1] "" Host
 SG_ current_error : 1|1@0+ (1,0) [0|1] "" Host
 SG_ estop_error : 0|1@0+ (1,0) [0|1] "" Host
 SG_ calibrated : 15|1@0+ (1,0) [0|1] "" Host
 SG_ activated : 14|1@0+ (1,0) [0|1] "" Host
 SG_ watchdog_error : 13|1@0+ (1,0) [0|1] "" Host
 SG_ wrong_product : 12|1@0+ (1,0) [0|1] "" Host

BO_ 566 Send_Respond_Iq_data_N4: 2 Driver4
 SG_ current : 7|16@0- (1,0) [-32768|32767] "" Host

BO_ 567 Send_Respond_Iq_data_N4_Fault: 2 Driver4
 SG_ current : 7|16@0- (1,0) [-32768|32767] "" Host

BO_ 568 Send_Respond_Encoder_data_N4: 8 Driver4
 SG_ position : 7|32@0- (1,0) [-2147483648|2147483647] "" Host
 SG_ speed : 39|32@0- (1,0) [-2147483648|2147483647] "" Host

BO_ 569 Send_Respond_Encoder_da_N4_Fault: 8 Driver4
 SG_ position : 7|32@0- (1,0) [-2147483648|2147483647] "" Host
 SG_ speed : 39|32@0- (1,0) [-2147483648|2147483647] "" Host

BO_ 578 Send_Respond_Kt_N4: 4 Driver4
 SG_ Kt : 7|32@0+ (1,0) [-3.402823466e+38|3.402823466e+38] "" Host

BO_ 579 Send_Respond_Kt_N4_Fault: 4 Driver4
 SG_ Kt : 7|32@0+ (1,0) [-3.402823466e+38|3.402823466e+38] "" Host

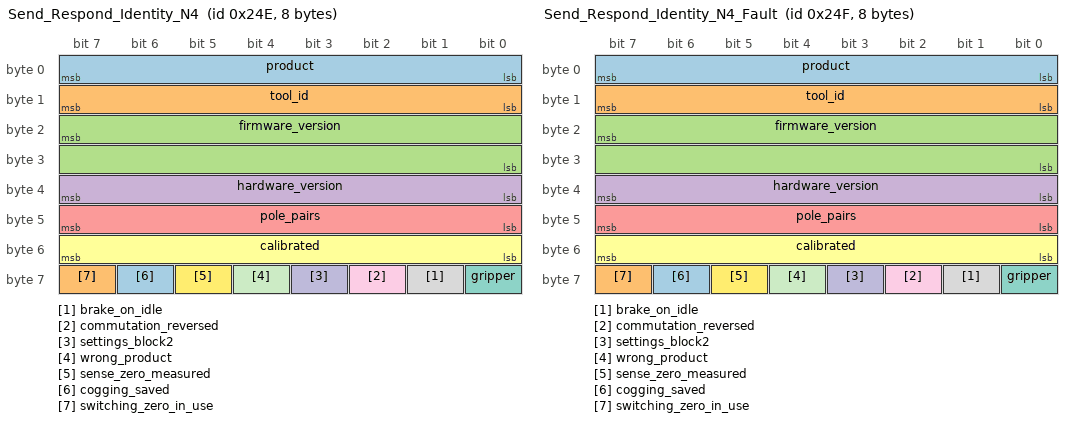
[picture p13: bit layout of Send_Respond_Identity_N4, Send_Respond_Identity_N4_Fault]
BO_ 590 Send_Respond_Identity_N4: 8 Driver4
 SG_ product : 7|8@0+ (1,0) [0|255] "" Host
 SG_ tool_id : 15|8@0+ (1,0) [0|255] "" Host
 SG_ firmware_version : 23|16@0+ (1,0) [0|65535] "" Host
 SG_ hardware_version : 39|8@0+ (1,0) [0|255] "" Host
 SG_ pole_pairs : 47|8@0+ (1,0) [0|255] "" Host
 SG_ calibrated : 55|8@0+ (1,0) [0|255] "" Host
 SG_ gripper : 56|1@0+ (1,0) [0|1] "" Host
 SG_ brake_on_idle : 57|1@0+ (1,0) [0|1] "" Host
 SG_ commutation_reversed : 58|1@0+ (1,0) [0|1] "" Host
 SG_ settings_block2 : 59|1@0+ (1,0) [0|1] "" Host
 SG_ wrong_product : 60|1@0+ (1,0) [0|1] "" Host
 SG_ sense_zero_measured : 61|1@0+ (1,0) [0|1] "" Host
 SG_ cogging_saved : 62|1@0+ (1,0) [0|1] "" Host
 SG_ switching_zero_in_use : 63|1@0+ (1,0) [0|1] "" Host

BO_ 591 Send_Respond_Identity_N4_Fault: 8 Driver4
 SG_ product : 7|8@0+ (1,0) [0|255] "" Host
 SG_ tool_id : 15|8@0+ (1,0) [0|255] "" Host
 SG_ firmware_version : 23|16@0+ (1,0) [0|65535] "" Host
 SG_ hardware_version : 39|8@0+ (1,0) [0|255] "" Host
 SG_ pole_pairs : 47|8@0+ (1,0) [0|255] "" Host
 SG_ calibrated : 55|8@0+ (1,0) [0|255] "" Host
 SG_ gripper : 56|1@0+ (1,0) [0|1] "" Host
 SG_ brake_on_idle : 57|1@0+ (1,0) [0|1] "" Host
 SG_ commutation_reversed : 58|1@0+ (1,0) [0|1] "" Host
 SG_ settings_block2 : 59|1@0+ (1,0) [0|1] "" Host
 SG_ wrong_product : 60|1@0+ (1,0) [0|1] "" Host
 SG_ sense_zero_measured : 61|1@0+ (1,0) [0|1] "" Host
 SG_ cogging_saved : 62|1@0+ (1,0) [0|1] "" Host
 SG_ switching_zero_in_use : 63|1@0+ (1,0) [0|1] "" Host

BO_ 592 Send_Respond_Telemetry_N4: 8 Driver4
 SG_ temperature : 7|16@0- (1,0) [-32768|32767] "" Host
 SG_ voltage : 23|16@0- (1,0) [-32768|32767] "" Host
 SG_ errors_1 : 39|8@0+ (1,0) [0|255] "" Host
 SG_ errors_2 : 47|8@0+ (1,0) [0|255] "" Host
 SG_ current : 55|16@0- (1,0) [-32768|32767] "" Host

BO_ 593 Send_Respond_Telemetry_N4_Fault: 8 Driver4
 SG_ temperature : 7|16@0- (1,0) [-32768|32767] "" Host
 SG_ voltage : 23|16@0- (1,0) [-32768|32767] "" Host
 SG_ errors_1 : 39|8@0+ (1,0) [0|255] "" Host
 SG_ errors_2 : 47|8@0+ (1,0) [0|255] "" Host
 SG_ current : 55|16@0- (1,0) [-32768|32767] "" Host

BO_ 530 Respond_Heartbeat_N4: 0 Driver4

BO_ 531 Respond_Heartbeat_N4_Fault: 0 Driver4

BO_ 534 Send_CAN_ID_N4: 1 Host
 SG_ ID : 7|8@0+ (1,0) [0|255] "" Driver4

BO_ 512 Send_ESTOP_N4: 0 Host

BO_ 536 Send_Idle_N4: 0 Host

BO_ 538 Send_Save_config_N4: 0 Host

BO_ 540 Send_Reset_N4: 0 Host

BO_ 514 Send_Clear_Error_N4: 0 Host

BO_ 542 Send_Watchdog_N4: 5 Host
 SG_ Time : 7|32@0+ (1,0) [0|4294967295] "" Driver4
 SG_ Action : 39|8@0+ (1,0) [0|255] "" Driver4

BO_ 572 Send_Heartbeat_Setup_N4: 4 Host
 SG_ Interval : 7|32@0+ (1,0) [0|4294967295] "" Driver4

BO_ 582 Send_Settings_N4: 2 Host
 SG_ Mask : 7|8@0+ (1,0) [0|255] "" Driver4
 SG_ Value : 15|8@0+ (1,0) [0|255] "" Driver4

BO_ 584 Send_Parameter_N4: 5 Host
 SG_ Parameter : 7|8@0+ (1,0) [0|255] "" Driver4
 SG_ Value : 15|32@0- (1,0) [-2147483648|2147483647] "" Driver4

BO_ 586 Send_Get_Parameter_N4: 1 Host
 SG_ Parameter : 7|8@0+ (1,0) [0|255] "" Driver4

BO_ 588 Respond_Parameter_N4: 5 Driver4
 SG_ parameter : 7|8@0+ (1,0) [0|255] "" Host
 SG_ value : 15|32@0- (1,0) [-2147483648|2147483647] "" Host

BO_ 589 Respond_Parameter_N4_Fault: 5 Driver4
 SG_ parameter : 7|8@0+ (1,0) [0|255] "" Host
 SG_ value : 15|32@0- (1,0) [-2147483648|2147483647] "" Host

BO_ 594 Send_Buffer_Read_N4: 5 Host
 SG_ Kind : 7|8@0+ (1,0) [0|255] "" Driver4
 SG_ First : 15|16@0+ (1,0) [0|65535] "" Driver4
 SG_ Count : 31|16@0+ (1,0) [0|65535] "" Driver4

BO_ 596 Respond_Buffer_Data_N4: 8 Driver4
 SG_ header : 7|16@0+ (1,0) [0|65535] "" Host
 SG_ word_a : 23|16@0- (1,0) [-32768|32767] "" Host
 SG_ word_b : 39|16@0- (1,0) [-32768|32767] "" Host
 SG_ word_c : 55|16@0- (1,0) [-32768|32767] "" Host

BO_ 597 Respond_Buffer_Data_N4_Fault: 8 Driver4
 SG_ header : 7|16@0+ (1,0) [0|65535] "" Host
 SG_ word_a : 23|16@0- (1,0) [-32768|32767] "" Host
 SG_ word_b : 39|16@0- (1,0) [-32768|32767] "" Host
 SG_ word_c : 55|16@0- (1,0) [-32768|32767] "" Host

BO_ 598 Send_Buffer_Write_N4: 8 Host
 SG_ Header : 7|16@0+ (1,0) [0|65535] "" Driver4
 SG_ Word_A : 23|16@0- (1,0) [-32768|32767] "" Driver4
 SG_ Word_B : 39|16@0- (1,0) [-32768|32767] "" Driver4
 SG_ Word_C : 55|16@0- (1,0) [-32768|32767] "" Driver4

BO_ 600 Send_Sound_N4: 8 Host
 SG_ Operation : 7|8@0+ (1,0) [0|255] "" Driver4
 SG_ Channel : 15|8@0+ (1,0) [0|255] "" Driver4
 SG_ A : 23|16@0+ (1,0) [0|65535] "" Driver4
 SG_ B : 39|16@0+ (1,0) [0|65535] "" Driver4
 SG_ C : 55|16@0+ (1,0) [0|65535] "" Driver4

BO_ 602 Send_Sound_Samples_N4: 8 Host
 SG_ Sample_1 : 7|8@0- (1,0) [-128|127] "" Driver4
 SG_ Sample_2 : 15|8@0- (1,0) [-128|127] "" Driver4
 SG_ Sample_3 : 23|8@0- (1,0) [-128|127] "" Driver4
 SG_ Sample_4 : 31|8@0- (1,0) [-128|127] "" Driver4
 SG_ Sample_5 : 39|8@0- (1,0) [-128|127] "" Driver4
 SG_ Sample_6 : 47|8@0- (1,0) [-128|127] "" Driver4
 SG_ Sample_7 : 55|8@0- (1,0) [-128|127] "" Driver4
 SG_ Sample_8 : 63|8@0- (1,0) [-128|127] "" Driver4

BO_ 634 Send_gripper_data_pack_N4: 5 Host
 SG_ Position : 7|8@0+ (1,0) [0|255] "" Driver4
 SG_ Speed : 15|8@0+ (1,0) [0|255] "" Driver4
 SG_ Current : 23|16@0- (1,0) [-32768|32767] "" Driver4
 SG_ Activate : 39|1@0+ (1,0) [0|1] "" Driver4
 SG_ Action : 38|1@0+ (1,0) [0|1] "" Driver4
 SG_ E_stop : 37|1@0+ (1,0) [0|1] "" Driver4
 SG_ Release_direction : 36|1@0+ (1,0) [0|1] "" Driver4

BO_ 636 Send_gripper_calibrate_N4: 0 Host

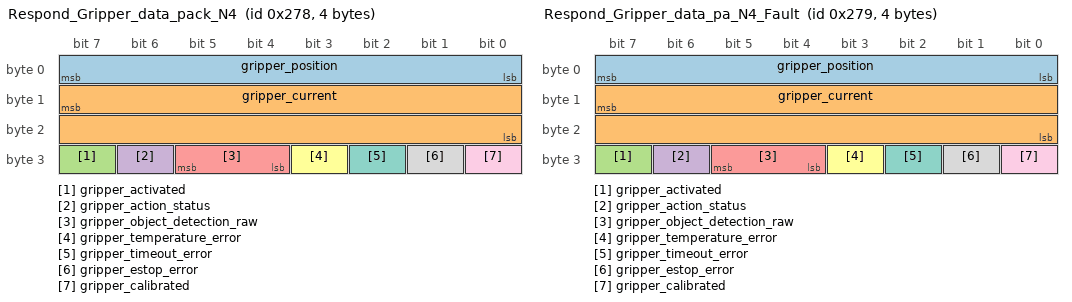
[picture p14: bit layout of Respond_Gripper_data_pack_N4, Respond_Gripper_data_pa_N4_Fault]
BO_ 632 Respond_Gripper_data_pack_N4: 4 Driver4
 SG_ gripper_position : 7|8@0+ (1,0) [0|255] "" Host
 SG_ gripper_current : 15|16@0- (1,0) [-32768|32767] "" Host
 SG_ gripper_activated : 31|1@0+ (1,0) [0|1] "" Host
 SG_ gripper_action_status : 30|1@0+ (1,0) [0|1] "" Host
 SG_ gripper_object_detection_raw : 29|2@0+ (1,0) [0|3] "" Host
 SG_ gripper_temperature_error : 27|1@0+ (1,0) [0|1] "" Host
 SG_ gripper_timeout_error : 26|1@0+ (1,0) [0|1] "" Host
 SG_ gripper_estop_error : 25|1@0+ (1,0) [0|1] "" Host
 SG_ gripper_calibrated : 24|1@0+ (1,0) [0|1] "" Host

BO_ 633 Respond_Gripper_data_pa_N4_Fault: 4 Driver4
 SG_ gripper_position : 7|8@0+ (1,0) [0|255] "" Host
 SG_ gripper_current : 15|16@0- (1,0) [-32768|32767] "" Host
 SG_ gripper_activated : 31|1@0+ (1,0) [0|1] "" Host
 SG_ gripper_action_status : 30|1@0+ (1,0) [0|1] "" Host
 SG_ gripper_object_detection_raw : 29|2@0+ (1,0) [0|3] "" Host
 SG_ gripper_temperature_error : 27|1@0+ (1,0) [0|1] "" Host
 SG_ gripper_timeout_error : 26|1@0+ (1,0) [0|1] "" Host
 SG_ gripper_estop_error : 25|1@0+ (1,0) [0|1] "" Host
 SG_ gripper_calibrated : 24|1@0+ (1,0) [0|1] "" Host

BO_ 644 Send_data_pack_1_N5: 8 Host
 SG_ Position_setpoint : 7|24@0- (1,0) [-8388608|8388607] "" Driver5
 SG_ Speed_feedforward : 31|24@0- (1,0) [-8388608|8388607] "" Driver5
 SG_ Current_feedforward : 55|16@0- (1,0) [-32768|32767] "" Driver5

BO_ 648 Send_data_pack_PD_N5: 8 Host
 SG_ Position_setpoint : 7|24@0- (1,0) [-8388608|8388607] "" Driver5
 SG_ Speed_setpoint : 31|24@0- (1,0) [-8388608|8388607] "" Driver5
 SG_ Current_feedforward : 55|16@0- (1,0) [-32768|32767] "" Driver5

BO_ 702 Send_data_pack_HALL_N5: 4 Host
 SG_ Speed : 7|24@0- (1,0) [-8388608|8388607] "" Driver5
 SG_ Trigger : 31|8@0+ (1,0) [0|255] "" Driver5

BO_ 646 Respond_data_pack_1_N5: 8 Driver5
 SG_ position : 7|24@0- (1,0) [-8388608|8388607] "" Host
 SG_ speed : 31|24@0- (1,0) [-8388608|8388607] "" Host
 SG_ current : 55|16@0- (1,0) [-32768|32767] "" Host

BO_ 647 Respond_data_pack_1_N5_Fault: 8 Driver5
 SG_ position : 7|24@0- (1,0) [-8388608|8388607] "" Host
 SG_ speed : 31|24@0- (1,0) [-8388608|8388607] "" Host
 SG_ current : 55|16@0- (1,0) [-32768|32767] "" Host

BO_ 704 Respond_data_hall_N5: 4 Driver5
 SG_ position : 7|24@0- (1,0) [-8388608|8388607] "" Host
 SG_ HALL_trigger : 31|1@0+ (1,0) [0|1] "" Host
 SG_ additional_pin2 : 30|1@0+ (1,0) [0|1] "" Host
 SG_ hall_index : 29|1@0+ (1,0) [0|1] "" Host

BO_ 705 Respond_data_hall_N5_Fault: 4 Driver5
 SG_ position : 7|24@0- (1,0) [-8388608|8388607] "" Host
 SG_ HALL_trigger : 31|1@0+ (1,0) [0|1] "" Host
 SG_ additional_pin2 : 30|1@0+ (1,0) [0|1] "" Host
 SG_ hall_index : 29|1@0+ (1,0) [0|1] "" Host

BO_ 672 Send_PD_Gains_N5: 8 Host
 SG_ KP : 7|32@0+ (1,0) [-3.402823466e+38|3.402823466e+38] "" Driver5
 SG_ KD : 39|32@0+ (1,0) [-3.402823466e+38|3.402823466e+38] "" Driver5

BO_ 674 Send_Current_Gains_N5: 8 Host
 SG_ Kp_iq : 7|32@0+ (1,0) [-3.402823466e+38|3.402823466e+38] "" Driver5
 SG_ Ki_iq : 39|32@0+ (1,0) [-3.402823466e+38|3.402823466e+38] "" Driver5

BO_ 676 Send_Velocity_Gains_N5: 8 Host
 SG_ Kpv : 7|32@0+ (1,0) [-3.402823466e+38|3.402823466e+38] "" Driver5
 SG_ Kiv : 39|32@0+ (1,0) [-3.402823466e+38|3.402823466e+38] "" Driver5

BO_ 678 Send_Position_Gains_N5: 4 Host
 SG_ Kpp : 7|32@0+ (1,0) [-3.402823466e+38|3.402823466e+38] "" Driver5

BO_ 680 Send_Limits_N5: 8 Host
 SG_ Speed_limit : 7|32@0+ (1,0) [-3.402823466e+38|3.402823466e+38] "" Driver5
 SG_ Current_limit : 39|32@0+ (1,0) [-3.402823466e+38|3.402823466e+38] "" Driver5

BO_ 684 Send_Kt_N5: 4 Host
 SG_ Kt : 7|32@0+ (1,0) [-3.402823466e+38|3.402823466e+38] "" Driver5

BO_ 708 Send_Voltage_Limit_N5: 4 Host
 SG_ Voltage_limit : 7|32@0- (1,0) [-2147483648|2147483647] "" Driver5

BO_ 660 Send_Respond_Ping_N5: 0 Driver5

BO_ 661 Send_Respond_Ping_N5_Fault: 0 Driver5

BO_ 686 Send_Respond_Temperature_N5: 2 Driver5
 SG_ temperature : 7|16@0- (1,0) [-32768|32767] "" Host

BO_ 687 Send_Respond_Temperatur_N5_Fault: 2 Driver5
 SG_ temperature : 7|16@0- (1,0) [-32768|32767] "" Host

BO_ 688 Send_Respond_Voltage_N5: 2 Driver5
 SG_ voltage : 7|16@0+ (1,0) [0|65535] "" Host

BO_ 689 Send_Respond_Voltage_N5_Fault: 2 Driver5
 SG_ voltage : 7|16@0+ (1,0) [0|65535] "" Host

BO_ 690 Send_Respond_Device_Info_N5: 7 Driver5
 SG_ HARDWARE_VERSION : 7|8@0+ (1,0) [0|255] "" Host
 SG_ BATCH_DATE : 15|8@0+ (1,0) [0|255] "" Host
 SG_ SOFTWARE_VERSION : 23|8@0+ (1,0) [0|255] "" Host
 SG_ SERIAL_NUMBER : 31|32@0+ (1,0) [0|4294967295] "" Host

BO_ 691 Send_Respond_Device_Inf_N5_Fault: 7 Driver5
 SG_ HARDWARE_VERSION : 7|8@0+ (1,0) [0|255] "" Host
 SG_ BATCH_DATE : 15|8@0+ (1,0) [0|255] "" Host
 SG_ SOFTWARE_VERSION : 23|8@0+ (1,0) [0|255] "" Host
 SG_ SERIAL_NUMBER : 31|32@0+ (1,0) [0|4294967295] "" Host

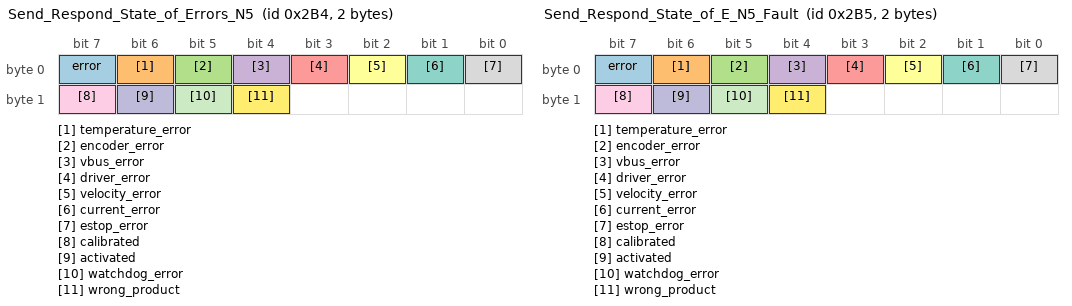
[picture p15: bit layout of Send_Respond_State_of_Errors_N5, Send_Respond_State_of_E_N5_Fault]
BO_ 692 Send_Respond_State_of_Errors_N5: 2 Driver5
 SG_ error : 7|1@0+ (1,0) [0|1] "" Host
 SG_ temperature_error : 6|1@0+ (1,0) [0|1] "" Host
 SG_ encoder_error : 5|1@0+ (1,0) [0|1] "" Host
 SG_ vbus_error : 4|1@0+ (1,0) [0|1] "" Host
 SG_ driver_error : 3|1@0+ (1,0) [0|1] "" Host
 SG_ velocity_error : 2|1@0+ (1,0) [0|1] "" Host
 SG_ current_error : 1|1@0+ (1,0) [0|1] "" Host
 SG_ estop_error : 0|1@0+ (1,0) [0|1] "" Host
 SG_ calibrated : 15|1@0+ (1,0) [0|1] "" Host
 SG_ activated : 14|1@0+ (1,0) [0|1] "" Host
 SG_ watchdog_error : 13|1@0+ (1,0) [0|1] "" Host
 SG_ wrong_product : 12|1@0+ (1,0) [0|1] "" Host

BO_ 693 Send_Respond_State_of_E_N5_Fault: 2 Driver5
 SG_ error : 7|1@0+ (1,0) [0|1] "" Host
 SG_ temperature_error : 6|1@0+ (1,0) [0|1] "" Host
 SG_ encoder_error : 5|1@0+ (1,0) [0|1] "" Host
 SG_ vbus_error : 4|1@0+ (1,0) [0|1] "" Host
 SG_ driver_error : 3|1@0+ (1,0) [0|1] "" Host
 SG_ velocity_error : 2|1@0+ (1,0) [0|1] "" Host
 SG_ current_error : 1|1@0+ (1,0) [0|1] "" Host
 SG_ estop_error : 0|1@0+ (1,0) [0|1] "" Host
 SG_ calibrated : 15|1@0+ (1,0) [0|1] "" Host
 SG_ activated : 14|1@0+ (1,0) [0|1] "" Host
 SG_ watchdog_error : 13|1@0+ (1,0) [0|1] "" Host
 SG_ wrong_product : 12|1@0+ (1,0) [0|1] "" Host

BO_ 694 Send_Respond_Iq_data_N5: 2 Driver5
 SG_ current : 7|16@0- (1,0) [-32768|32767] "" Host

BO_ 695 Send_Respond_Iq_data_N5_Fault: 2 Driver5
 SG_ current : 7|16@0- (1,0) [-32768|32767] "" Host

BO_ 696 Send_Respond_Encoder_data_N5: 8 Driver5
 SG_ position : 7|32@0- (1,0) [-2147483648|2147483647] "" Host
 SG_ speed : 39|32@0- (1,0) [-2147483648|2147483647] "" Host

BO_ 697 Send_Respond_Encoder_da_N5_Fault: 8 Driver5
 SG_ position : 7|32@0- (1,0) [-2147483648|2147483647] "" Host
 SG_ speed : 39|32@0- (1,0) [-2147483648|2147483647] "" Host

BO_ 706 Send_Respond_Kt_N5: 4 Driver5
 SG_ Kt : 7|32@0+ (1,0) [-3.402823466e+38|3.402823466e+38] "" Host

BO_ 707 Send_Respond_Kt_N5_Fault: 4 Driver5
 SG_ Kt : 7|32@0+ (1,0) [-3.402823466e+38|3.402823466e+38] "" Host

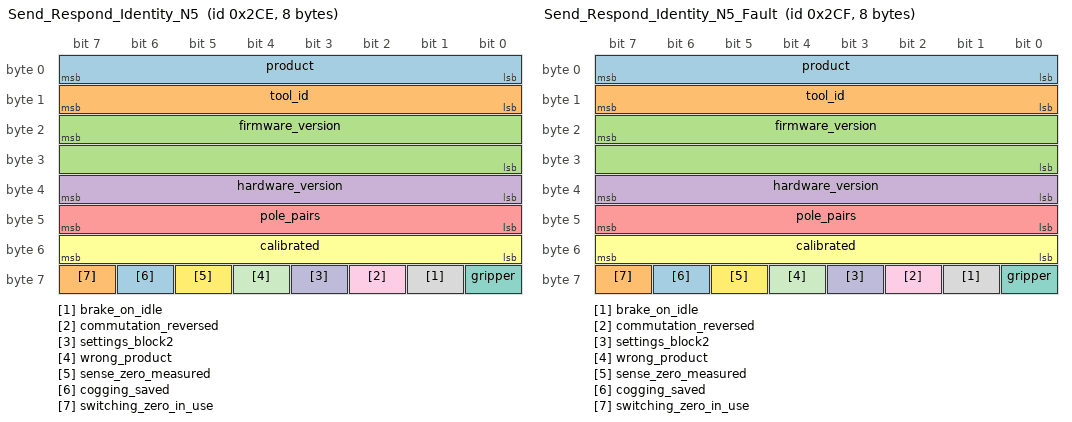
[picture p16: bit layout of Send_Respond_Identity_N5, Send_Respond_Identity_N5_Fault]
BO_ 718 Send_Respond_Identity_N5: 8 Driver5
 SG_ product : 7|8@0+ (1,0) [0|255] "" Host
 SG_ tool_id : 15|8@0+ (1,0) [0|255] "" Host
 SG_ firmware_version : 23|16@0+ (1,0) [0|65535] "" Host
 SG_ hardware_version : 39|8@0+ (1,0) [0|255] "" Host
 SG_ pole_pairs : 47|8@0+ (1,0) [0|255] "" Host
 SG_ calibrated : 55|8@0+ (1,0) [0|255] "" Host
 SG_ gripper : 56|1@0+ (1,0) [0|1] "" Host
 SG_ brake_on_idle : 57|1@0+ (1,0) [0|1] "" Host
 SG_ commutation_reversed : 58|1@0+ (1,0) [0|1] "" Host
 SG_ settings_block2 : 59|1@0+ (1,0) [0|1] "" Host
 SG_ wrong_product : 60|1@0+ (1,0) [0|1] "" Host
 SG_ sense_zero_measured : 61|1@0+ (1,0) [0|1] "" Host
 SG_ cogging_saved : 62|1@0+ (1,0) [0|1] "" Host
 SG_ switching_zero_in_use : 63|1@0+ (1,0) [0|1] "" Host

BO_ 719 Send_Respond_Identity_N5_Fault: 8 Driver5
 SG_ product : 7|8@0+ (1,0) [0|255] "" Host
 SG_ tool_id : 15|8@0+ (1,0) [0|255] "" Host
 SG_ firmware_version : 23|16@0+ (1,0) [0|65535] "" Host
 SG_ hardware_version : 39|8@0+ (1,0) [0|255] "" Host
 SG_ pole_pairs : 47|8@0+ (1,0) [0|255] "" Host
 SG_ calibrated : 55|8@0+ (1,0) [0|255] "" Host
 SG_ gripper : 56|1@0+ (1,0) [0|1] "" Host
 SG_ brake_on_idle : 57|1@0+ (1,0) [0|1] "" Host
 SG_ commutation_reversed : 58|1@0+ (1,0) [0|1] "" Host
 SG_ settings_block2 : 59|1@0+ (1,0) [0|1] "" Host
 SG_ wrong_product : 60|1@0+ (1,0) [0|1] "" Host
 SG_ sense_zero_measured : 61|1@0+ (1,0) [0|1] "" Host
 SG_ cogging_saved : 62|1@0+ (1,0) [0|1] "" Host
 SG_ switching_zero_in_use : 63|1@0+ (1,0) [0|1] "" Host

BO_ 720 Send_Respond_Telemetry_N5: 8 Driver5
 SG_ temperature : 7|16@0- (1,0) [-32768|32767] "" Host
 SG_ voltage : 23|16@0- (1,0) [-32768|32767] "" Host
 SG_ errors_1 : 39|8@0+ (1,0) [0|255] "" Host
 SG_ errors_2 : 47|8@0+ (1,0) [0|255] "" Host
 SG_ current : 55|16@0- (1,0) [-32768|32767] "" Host

BO_ 721 Send_Respond_Telemetry_N5_Fault: 8 Driver5
 SG_ temperature : 7|16@0- (1,0) [-32768|32767] "" Host
 SG_ voltage : 23|16@0- (1,0) [-32768|32767] "" Host
 SG_ errors_1 : 39|8@0+ (1,0) [0|255] "" Host
 SG_ errors_2 : 47|8@0+ (1,0) [0|255] "" Host
 SG_ current : 55|16@0- (1,0) [-32768|32767] "" Host

BO_ 658 Respond_Heartbeat_N5: 0 Driver5

BO_ 659 Respond_Heartbeat_N5_Fault: 0 Driver5

BO_ 662 Send_CAN_ID_N5: 1 Host
 SG_ ID : 7|8@0+ (1,0) [0|255] "" Driver5

BO_ 640 Send_ESTOP_N5: 0 Host

BO_ 664 Send_Idle_N5: 0 Host

BO_ 666 Send_Save_config_N5: 0 Host

BO_ 668 Send_Reset_N5: 0 Host

BO_ 642 Send_Clear_Error_N5: 0 Host

BO_ 670 Send_Watchdog_N5: 5 Host
 SG_ Time : 7|32@0+ (1,0) [0|4294967295] "" Driver5
 SG_ Action : 39|8@0+ (1,0) [0|255] "" Driver5

BO_ 700 Send_Heartbeat_Setup_N5: 4 Host
 SG_ Interval : 7|32@0+ (1,0) [0|4294967295] "" Driver5

BO_ 710 Send_Settings_N5: 2 Host
 SG_ Mask : 7|8@0+ (1,0) [0|255] "" Driver5
 SG_ Value : 15|8@0+ (1,0) [0|255] "" Driver5

BO_ 712 Send_Parameter_N5: 5 Host
 SG_ Parameter : 7|8@0+ (1,0) [0|255] "" Driver5
 SG_ Value : 15|32@0- (1,0) [-2147483648|2147483647] "" Driver5

BO_ 714 Send_Get_Parameter_N5: 1 Host
 SG_ Parameter : 7|8@0+ (1,0) [0|255] "" Driver5

BO_ 716 Respond_Parameter_N5: 5 Driver5
 SG_ parameter : 7|8@0+ (1,0) [0|255] "" Host
 SG_ value : 15|32@0- (1,0) [-2147483648|2147483647] "" Host

BO_ 717 Respond_Parameter_N5_Fault: 5 Driver5
 SG_ parameter : 7|8@0+ (1,0) [0|255] "" Host
 SG_ value : 15|32@0- (1,0) [-2147483648|2147483647] "" Host

BO_ 722 Send_Buffer_Read_N5: 5 Host
 SG_ Kind : 7|8@0+ (1,0) [0|255] "" Driver5
 SG_ First : 15|16@0+ (1,0) [0|65535] "" Driver5
 SG_ Count : 31|16@0+ (1,0) [0|65535] "" Driver5

BO_ 724 Respond_Buffer_Data_N5: 8 Driver5
 SG_ header : 7|16@0+ (1,0) [0|65535] "" Host
 SG_ word_a : 23|16@0- (1,0) [-32768|32767] "" Host
 SG_ word_b : 39|16@0- (1,0) [-32768|32767] "" Host
 SG_ word_c : 55|16@0- (1,0) [-32768|32767] "" Host

BO_ 725 Respond_Buffer_Data_N5_Fault: 8 Driver5
 SG_ header : 7|16@0+ (1,0) [0|65535] "" Host
 SG_ word_a : 23|16@0- (1,0) [-32768|32767] "" Host
 SG_ word_b : 39|16@0- (1,0) [-32768|32767] "" Host
 SG_ word_c : 55|16@0- (1,0) [-32768|32767] "" Host

BO_ 726 Send_Buffer_Write_N5: 8 Host
 SG_ Header : 7|16@0+ (1,0) [0|65535] "" Driver5
 SG_ Word_A : 23|16@0- (1,0) [-32768|32767] "" Driver5
 SG_ Word_B : 39|16@0- (1,0) [-32768|32767] "" Driver5
 SG_ Word_C : 55|16@0- (1,0) [-32768|32767] "" Driver5

BO_ 728 Send_Sound_N5: 8 Host
 SG_ Operation : 7|8@0+ (1,0) [0|255] "" Driver5
 SG_ Channel : 15|8@0+ (1,0) [0|255] "" Driver5
 SG_ A : 23|16@0+ (1,0) [0|65535] "" Driver5
 SG_ B : 39|16@0+ (1,0) [0|65535] "" Driver5
 SG_ C : 55|16@0+ (1,0) [0|65535] "" Driver5

BO_ 730 Send_Sound_Samples_N5: 8 Host
 SG_ Sample_1 : 7|8@0- (1,0) [-128|127] "" Driver5
 SG_ Sample_2 : 15|8@0- (1,0) [-128|127] "" Driver5
 SG_ Sample_3 : 23|8@0- (1,0) [-128|127] "" Driver5
 SG_ Sample_4 : 31|8@0- (1,0) [-128|127] "" Driver5
 SG_ Sample_5 : 39|8@0- (1,0) [-128|127] "" Driver5
 SG_ Sample_6 : 47|8@0- (1,0) [-128|127] "" Driver5
 SG_ Sample_7 : 55|8@0- (1,0) [-128|127] "" Driver5
 SG_ Sample_8 : 63|8@0- (1,0) [-128|127] "" Driver5

BO_ 762 Send_gripper_data_pack_N5: 5 Host
 SG_ Position : 7|8@0+ (1,0) [0|255] "" Driver5
 SG_ Speed : 15|8@0+ (1,0) [0|255] "" Driver5
 SG_ Current : 23|16@0- (1,0) [-32768|32767] "" Driver5
 SG_ Activate : 39|1@0+ (1,0) [0|1] "" Driver5
 SG_ Action : 38|1@0+ (1,0) [0|1] "" Driver5
 SG_ E_stop : 37|1@0+ (1,0) [0|1] "" Driver5
 SG_ Release_direction : 36|1@0+ (1,0) [0|1] "" Driver5

BO_ 764 Send_gripper_calibrate_N5: 0 Host

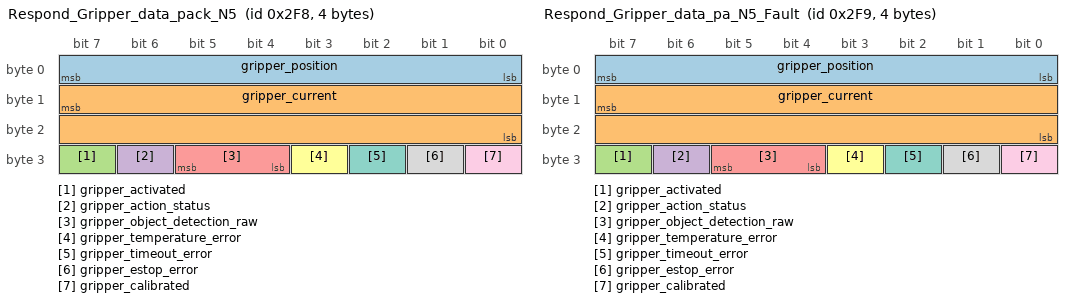
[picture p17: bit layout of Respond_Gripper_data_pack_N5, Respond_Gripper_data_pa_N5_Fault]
BO_ 760 Respond_Gripper_data_pack_N5: 4 Driver5
 SG_ gripper_position : 7|8@0+ (1,0) [0|255] "" Host
 SG_ gripper_current : 15|16@0- (1,0) [-32768|32767] "" Host
 SG_ gripper_activated : 31|1@0+ (1,0) [0|1] "" Host
 SG_ gripper_action_status : 30|1@0+ (1,0) [0|1] "" Host
 SG_ gripper_object_detection_raw : 29|2@0+ (1,0) [0|3] "" Host
 SG_ gripper_temperature_error : 27|1@0+ (1,0) [0|1] "" Host
 SG_ gripper_timeout_error : 26|1@0+ (1,0) [0|1] "" Host
 SG_ gripper_estop_error : 25|1@0+ (1,0) [0|1] "" Host
 SG_ gripper_calibrated : 24|1@0+ (1,0) [0|1] "" Host

BO_ 761 Respond_Gripper_data_pa_N5_Fault: 4 Driver5
 SG_ gripper_position : 7|8@0+ (1,0) [0|255] "" Host
 SG_ gripper_current : 15|16@0- (1,0) [-32768|32767] "" Host
 SG_ gripper_activated : 31|1@0+ (1,0) [0|1] "" Host
 SG_ gripper_action_status : 30|1@0+ (1,0) [0|1] "" Host
 SG_ gripper_object_detection_raw : 29|2@0+ (1,0) [0|3] "" Host
 SG_ gripper_temperature_error : 27|1@0+ (1,0) [0|1] "" Host
 SG_ gripper_timeout_error : 26|1@0+ (1,0) [0|1] "" Host
 SG_ gripper_estop_error : 25|1@0+ (1,0) [0|1] "" Host
 SG_ gripper_calibrated : 24|1@0+ (1,0) [0|1] "" Host

BO_ 772 Send_data_pack_1_N6: 8 Host
 SG_ Position_setpoint : 7|24@0- (1,0) [-8388608|8388607] "" Driver6
 SG_ Speed_feedforward : 31|24@0- (1,0) [-8388608|8388607] "" Driver6
 SG_ Current_feedforward : 55|16@0- (1,0) [-32768|32767] "" Driver6

BO_ 776 Send_data_pack_PD_N6: 8 Host
 SG_ Position_setpoint : 7|24@0- (1,0) [-8388608|8388607] "" Driver6
 SG_ Speed_setpoint : 31|24@0- (1,0) [-8388608|8388607] "" Driver6
 SG_ Current_feedforward : 55|16@0- (1,0) [-32768|32767] "" Driver6

BO_ 830 Send_data_pack_HALL_N6: 4 Host
 SG_ Speed : 7|24@0- (1,0) [-8388608|8388607] "" Driver6
 SG_ Trigger : 31|8@0+ (1,0) [0|255] "" Driver6

BO_ 774 Respond_data_pack_1_N6: 8 Driver6
 SG_ position : 7|24@0- (1,0) [-8388608|8388607] "" Host
 SG_ speed : 31|24@0- (1,0) [-8388608|8388607] "" Host
 SG_ current : 55|16@0- (1,0) [-32768|32767] "" Host

BO_ 775 Respond_data_pack_1_N6_Fault: 8 Driver6
 SG_ position : 7|24@0- (1,0) [-8388608|8388607] "" Host
 SG_ speed : 31|24@0- (1,0) [-8388608|8388607] "" Host
 SG_ current : 55|16@0- (1,0) [-32768|32767] "" Host

BO_ 832 Respond_data_hall_N6: 4 Driver6
 SG_ position : 7|24@0- (1,0) [-8388608|8388607] "" Host
 SG_ HALL_trigger : 31|1@0+ (1,0) [0|1] "" Host
 SG_ additional_pin2 : 30|1@0+ (1,0) [0|1] "" Host
 SG_ hall_index : 29|1@0+ (1,0) [0|1] "" Host

BO_ 833 Respond_data_hall_N6_Fault: 4 Driver6
 SG_ position : 7|24@0- (1,0) [-8388608|8388607] "" Host
 SG_ HALL_trigger : 31|1@0+ (1,0) [0|1] "" Host
 SG_ additional_pin2 : 30|1@0+ (1,0) [0|1] "" Host
 SG_ hall_index : 29|1@0+ (1,0) [0|1] "" Host

BO_ 800 Send_PD_Gains_N6: 8 Host
 SG_ KP : 7|32@0+ (1,0) [-3.402823466e+38|3.402823466e+38] "" Driver6
 SG_ KD : 39|32@0+ (1,0) [-3.402823466e+38|3.402823466e+38] "" Driver6

BO_ 802 Send_Current_Gains_N6: 8 Host
 SG_ Kp_iq : 7|32@0+ (1,0) [-3.402823466e+38|3.402823466e+38] "" Driver6
 SG_ Ki_iq : 39|32@0+ (1,0) [-3.402823466e+38|3.402823466e+38] "" Driver6

BO_ 804 Send_Velocity_Gains_N6: 8 Host
 SG_ Kpv : 7|32@0+ (1,0) [-3.402823466e+38|3.402823466e+38] "" Driver6
 SG_ Kiv : 39|32@0+ (1,0) [-3.402823466e+38|3.402823466e+38] "" Driver6

BO_ 806 Send_Position_Gains_N6: 4 Host
 SG_ Kpp : 7|32@0+ (1,0) [-3.402823466e+38|3.402823466e+38] "" Driver6

BO_ 808 Send_Limits_N6: 8 Host
 SG_ Speed_limit : 7|32@0+ (1,0) [-3.402823466e+38|3.402823466e+38] "" Driver6
 SG_ Current_limit : 39|32@0+ (1,0) [-3.402823466e+38|3.402823466e+38] "" Driver6

BO_ 812 Send_Kt_N6: 4 Host
 SG_ Kt : 7|32@0+ (1,0) [-3.402823466e+38|3.402823466e+38] "" Driver6

BO_ 836 Send_Voltage_Limit_N6: 4 Host
 SG_ Voltage_limit : 7|32@0- (1,0) [-2147483648|2147483647] "" Driver6

BO_ 788 Send_Respond_Ping_N6: 0 Driver6

BO_ 789 Send_Respond_Ping_N6_Fault: 0 Driver6

BO_ 814 Send_Respond_Temperature_N6: 2 Driver6
 SG_ temperature : 7|16@0- (1,0) [-32768|32767] "" Host

BO_ 815 Send_Respond_Temperatur_N6_Fault: 2 Driver6
 SG_ temperature : 7|16@0- (1,0) [-32768|32767] "" Host

BO_ 816 Send_Respond_Voltage_N6: 2 Driver6
 SG_ voltage : 7|16@0+ (1,0) [0|65535] "" Host

BO_ 817 Send_Respond_Voltage_N6_Fault: 2 Driver6
 SG_ voltage : 7|16@0+ (1,0) [0|65535] "" Host

BO_ 818 Send_Respond_Device_Info_N6: 7 Driver6
 SG_ HARDWARE_VERSION : 7|8@0+ (1,0) [0|255] "" Host
 SG_ BATCH_DATE : 15|8@0+ (1,0) [0|255] "" Host
 SG_ SOFTWARE_VERSION : 23|8@0+ (1,0) [0|255] "" Host
 SG_ SERIAL_NUMBER : 31|32@0+ (1,0) [0|4294967295] "" Host

BO_ 819 Send_Respond_Device_Inf_N6_Fault: 7 Driver6
 SG_ HARDWARE_VERSION : 7|8@0+ (1,0) [0|255] "" Host
 SG_ BATCH_DATE : 15|8@0+ (1,0) [0|255] "" Host
 SG_ SOFTWARE_VERSION : 23|8@0+ (1,0) [0|255] "" Host
 SG_ SERIAL_NUMBER : 31|32@0+ (1,0) [0|4294967295] "" Host

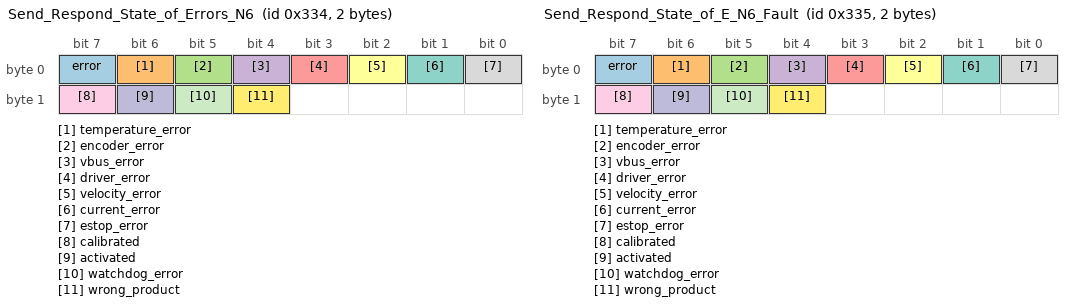
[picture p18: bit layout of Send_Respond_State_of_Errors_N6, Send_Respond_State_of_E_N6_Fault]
BO_ 820 Send_Respond_State_of_Errors_N6: 2 Driver6
 SG_ error : 7|1@0+ (1,0) [0|1] "" Host
 SG_ temperature_error : 6|1@0+ (1,0) [0|1] "" Host
 SG_ encoder_error : 5|1@0+ (1,0) [0|1] "" Host
 SG_ vbus_error : 4|1@0+ (1,0) [0|1] "" Host
 SG_ driver_error : 3|1@0+ (1,0) [0|1] "" Host
 SG_ velocity_error : 2|1@0+ (1,0) [0|1] "" Host
 SG_ current_error : 1|1@0+ (1,0) [0|1] "" Host
 SG_ estop_error : 0|1@0+ (1,0) [0|1] "" Host
 SG_ calibrated : 15|1@0+ (1,0) [0|1] "" Host
 SG_ activated : 14|1@0+ (1,0) [0|1] "" Host
 SG_ watchdog_error : 13|1@0+ (1,0) [0|1] "" Host
 SG_ wrong_product : 12|1@0+ (1,0) [0|1] "" Host

BO_ 821 Send_Respond_State_of_E_N6_Fault: 2 Driver6
 SG_ error : 7|1@0+ (1,0) [0|1] "" Host
 SG_ temperature_error : 6|1@0+ (1,0) [0|1] "" Host
 SG_ encoder_error : 5|1@0+ (1,0) [0|1] "" Host
 SG_ vbus_error : 4|1@0+ (1,0) [0|1] "" Host
 SG_ driver_error : 3|1@0+ (1,0) [0|1] "" Host
 SG_ velocity_error : 2|1@0+ (1,0) [0|1] "" Host
 SG_ current_error : 1|1@0+ (1,0) [0|1] "" Host
 SG_ estop_error : 0|1@0+ (1,0) [0|1] "" Host
 SG_ calibrated : 15|1@0+ (1,0) [0|1] "" Host
 SG_ activated : 14|1@0+ (1,0) [0|1] "" Host
 SG_ watchdog_error : 13|1@0+ (1,0) [0|1] "" Host
 SG_ wrong_product : 12|1@0+ (1,0) [0|1] "" Host

BO_ 822 Send_Respond_Iq_data_N6: 2 Driver6
 SG_ current : 7|16@0- (1,0) [-32768|32767] "" Host

BO_ 823 Send_Respond_Iq_data_N6_Fault: 2 Driver6
 SG_ current : 7|16@0- (1,0) [-32768|32767] "" Host

BO_ 824 Send_Respond_Encoder_data_N6: 8 Driver6
 SG_ position : 7|32@0- (1,0) [-2147483648|2147483647] "" Host
 SG_ speed : 39|32@0- (1,0) [-2147483648|2147483647] "" Host

BO_ 825 Send_Respond_Encoder_da_N6_Fault: 8 Driver6
 SG_ position : 7|32@0- (1,0) [-2147483648|2147483647] "" Host
 SG_ speed : 39|32@0- (1,0) [-2147483648|2147483647] "" Host

BO_ 834 Send_Respond_Kt_N6: 4 Driver6
 SG_ Kt : 7|32@0+ (1,0) [-3.402823466e+38|3.402823466e+38] "" Host

BO_ 835 Send_Respond_Kt_N6_Fault: 4 Driver6
 SG_ Kt : 7|32@0+ (1,0) [-3.402823466e+38|3.402823466e+38] "" Host

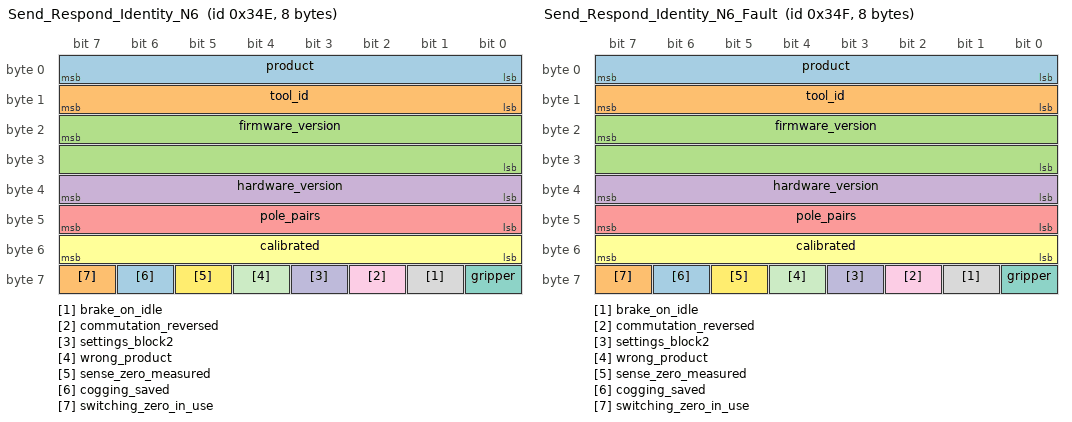
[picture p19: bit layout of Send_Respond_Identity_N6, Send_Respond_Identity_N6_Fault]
BO_ 846 Send_Respond_Identity_N6: 8 Driver6
 SG_ product : 7|8@0+ (1,0) [0|255] "" Host
 SG_ tool_id : 15|8@0+ (1,0) [0|255] "" Host
 SG_ firmware_version : 23|16@0+ (1,0) [0|65535] "" Host
 SG_ hardware_version : 39|8@0+ (1,0) [0|255] "" Host
 SG_ pole_pairs : 47|8@0+ (1,0) [0|255] "" Host
 SG_ calibrated : 55|8@0+ (1,0) [0|255] "" Host
 SG_ gripper : 56|1@0+ (1,0) [0|1] "" Host
 SG_ brake_on_idle : 57|1@0+ (1,0) [0|1] "" Host
 SG_ commutation_reversed : 58|1@0+ (1,0) [0|1] "" Host
 SG_ settings_block2 : 59|1@0+ (1,0) [0|1] "" Host
 SG_ wrong_product : 60|1@0+ (1,0) [0|1] "" Host
 SG_ sense_zero_measured : 61|1@0+ (1,0) [0|1] "" Host
 SG_ cogging_saved : 62|1@0+ (1,0) [0|1] "" Host
 SG_ switching_zero_in_use : 63|1@0+ (1,0) [0|1] "" Host

BO_ 847 Send_Respond_Identity_N6_Fault: 8 Driver6
 SG_ product : 7|8@0+ (1,0) [0|255] "" Host
 SG_ tool_id : 15|8@0+ (1,0) [0|255] "" Host
 SG_ firmware_version : 23|16@0+ (1,0) [0|65535] "" Host
 SG_ hardware_version : 39|8@0+ (1,0) [0|255] "" Host
 SG_ pole_pairs : 47|8@0+ (1,0) [0|255] "" Host
 SG_ calibrated : 55|8@0+ (1,0) [0|255] "" Host
 SG_ gripper : 56|1@0+ (1,0) [0|1] "" Host
 SG_ brake_on_idle : 57|1@0+ (1,0) [0|1] "" Host
 SG_ commutation_reversed : 58|1@0+ (1,0) [0|1] "" Host
 SG_ settings_block2 : 59|1@0+ (1,0) [0|1] "" Host
 SG_ wrong_product : 60|1@0+ (1,0) [0|1] "" Host
 SG_ sense_zero_measured : 61|1@0+ (1,0) [0|1] "" Host
 SG_ cogging_saved : 62|1@0+ (1,0) [0|1] "" Host
 SG_ switching_zero_in_use : 63|1@0+ (1,0) [0|1] "" Host

BO_ 848 Send_Respond_Telemetry_N6: 8 Driver6
 SG_ temperature : 7|16@0- (1,0) [-32768|32767] "" Host
 SG_ voltage : 23|16@0- (1,0) [-32768|32767] "" Host
 SG_ errors_1 : 39|8@0+ (1,0) [0|255] "" Host
 SG_ errors_2 : 47|8@0+ (1,0) [0|255] "" Host
 SG_ current : 55|16@0- (1,0) [-32768|32767] "" Host

BO_ 849 Send_Respond_Telemetry_N6_Fault: 8 Driver6
 SG_ temperature : 7|16@0- (1,0) [-32768|32767] "" Host
 SG_ voltage : 23|16@0- (1,0) [-32768|32767] "" Host
 SG_ errors_1 : 39|8@0+ (1,0) [0|255] "" Host
 SG_ errors_2 : 47|8@0+ (1,0) [0|255] "" Host
 SG_ current : 55|16@0- (1,0) [-32768|32767] "" Host

BO_ 786 Respond_Heartbeat_N6: 0 Driver6

BO_ 787 Respond_Heartbeat_N6_Fault: 0 Driver6

BO_ 790 Send_CAN_ID_N6: 1 Host
 SG_ ID : 7|8@0+ (1,0) [0|255] "" Driver6

BO_ 768 Send_ESTOP_N6: 0 Host

BO_ 792 Send_Idle_N6: 0 Host

BO_ 794 Send_Save_config_N6: 0 Host

BO_ 796 Send_Reset_N6: 0 Host

BO_ 770 Send_Clear_Error_N6: 0 Host

BO_ 798 Send_Watchdog_N6: 5 Host
 SG_ Time : 7|32@0+ (1,0) [0|4294967295] "" Driver6
 SG_ Action : 39|8@0+ (1,0) [0|255] "" Driver6

BO_ 828 Send_Heartbeat_Setup_N6: 4 Host
 SG_ Interval : 7|32@0+ (1,0) [0|4294967295] "" Driver6

BO_ 838 Send_Settings_N6: 2 Host
 SG_ Mask : 7|8@0+ (1,0) [0|255] "" Driver6
 SG_ Value : 15|8@0+ (1,0) [0|255] "" Driver6

BO_ 840 Send_Parameter_N6: 5 Host
 SG_ Parameter : 7|8@0+ (1,0) [0|255] "" Driver6
 SG_ Value : 15|32@0- (1,0) [-2147483648|2147483647] "" Driver6

BO_ 842 Send_Get_Parameter_N6: 1 Host
 SG_ Parameter : 7|8@0+ (1,0) [0|255] "" Driver6

BO_ 844 Respond_Parameter_N6: 5 Driver6
 SG_ parameter : 7|8@0+ (1,0) [0|255] "" Host
 SG_ value : 15|32@0- (1,0) [-2147483648|2147483647] "" Host

BO_ 845 Respond_Parameter_N6_Fault: 5 Driver6
 SG_ parameter : 7|8@0+ (1,0) [0|255] "" Host
 SG_ value : 15|32@0- (1,0) [-2147483648|2147483647] "" Host

BO_ 850 Send_Buffer_Read_N6: 5 Host
 SG_ Kind : 7|8@0+ (1,0) [0|255] "" Driver6
 SG_ First : 15|16@0+ (1,0) [0|65535] "" Driver6
 SG_ Count : 31|16@0+ (1,0) [0|65535] "" Driver6

BO_ 852 Respond_Buffer_Data_N6: 8 Driver6
 SG_ header : 7|16@0+ (1,0) [0|65535] "" Host
 SG_ word_a : 23|16@0- (1,0) [-32768|32767] "" Host
 SG_ word_b : 39|16@0- (1,0) [-32768|32767] "" Host
 SG_ word_c : 55|16@0- (1,0) [-32768|32767] "" Host

BO_ 853 Respond_Buffer_Data_N6_Fault: 8 Driver6
 SG_ header : 7|16@0+ (1,0) [0|65535] "" Host
 SG_ word_a : 23|16@0- (1,0) [-32768|32767] "" Host
 SG_ word_b : 39|16@0- (1,0) [-32768|32767] "" Host
 SG_ word_c : 55|16@0- (1,0) [-32768|32767] "" Host

BO_ 854 Send_Buffer_Write_N6: 8 Host
 SG_ Header : 7|16@0+ (1,0) [0|65535] "" Driver6
 SG_ Word_A : 23|16@0- (1,0) [-32768|32767] "" Driver6
 SG_ Word_B : 39|16@0- (1,0) [-32768|32767] "" Driver6
 SG_ Word_C : 55|16@0- (1,0) [-32768|32767] "" Driver6

BO_ 856 Send_Sound_N6: 8 Host
 SG_ Operation : 7|8@0+ (1,0) [0|255] "" Driver6
 SG_ Channel : 15|8@0+ (1,0) [0|255] "" Driver6
 SG_ A : 23|16@0+ (1,0) [0|65535] "" Driver6
 SG_ B : 39|16@0+ (1,0) [0|65535] "" Driver6
 SG_ C : 55|16@0+ (1,0) [0|65535] "" Driver6

BO_ 858 Send_Sound_Samples_N6: 8 Host
 SG_ Sample_1 : 7|8@0- (1,0) [-128|127] "" Driver6
 SG_ Sample_2 : 15|8@0- (1,0) [-128|127] "" Driver6
 SG_ Sample_3 : 23|8@0- (1,0) [-128|127] "" Driver6
 SG_ Sample_4 : 31|8@0- (1,0) [-128|127] "" Driver6
 SG_ Sample_5 : 39|8@0- (1,0) [-128|127] "" Driver6
 SG_ Sample_6 : 47|8@0- (1,0) [-128|127] "" Driver6
 SG_ Sample_7 : 55|8@0- (1,0) [-128|127] "" Driver6
 SG_ Sample_8 : 63|8@0- (1,0) [-128|127] "" Driver6

BO_ 890 Send_gripper_data_pack_N6: 5 Host
 SG_ Position : 7|8@0+ (1,0) [0|255] "" Driver6
 SG_ Speed : 15|8@0+ (1,0) [0|255] "" Driver6
 SG_ Current : 23|16@0- (1,0) [-32768|32767] "" Driver6
 SG_ Activate : 39|1@0+ (1,0) [0|1] "" Driver6
 SG_ Action : 38|1@0+ (1,0) [0|1] "" Driver6
 SG_ E_stop : 37|1@0+ (1,0) [0|1] "" Driver6
 SG_ Release_direction : 36|1@0+ (1,0) [0|1] "" Driver6

BO_ 892 Send_gripper_calibrate_N6: 0 Host

BO_ 888 Respond_Gripper_data_pack_N6: 4 Driver6
 SG_ gripper_position : 7|8@0+ (1,0) [0|255] "" Host
 SG_ gripper_current : 15|16@0- (1,0) [-32768|32767] "" Host
 SG_ gripper_activated : 31|1@0+ (1,0) [0|1] "" Host
 SG_ gripper_action_status : 30|1@0+ (1,0) [0|1] "" Host
 SG_ gripper_object_detection_raw : 29|2@0+ (1,0) [0|3] "" Host
 SG_ gripper_temperature_error : 27|1@0+ (1,0) [0|1] "" Host
 SG_ gripper_timeout_error : 26|1@0+ (1,0) [0|1] "" Host
 SG_ gripper_estop_error : 25|1@0+ (1,0) [0|1] "" Host
 SG_ gripper_calibrated : 24|1@0+ (1,0) [0|1] "" Host

BO_ 889 Respond_Gripper_data_pa_N6_Fault: 4 Driver6
 SG_ gripper_position : 7|8@0+ (1,0) [0|255] "" Host
 SG_ gripper_current : 15|16@0- (1,0) [-32768|32767] "" Host
 SG_ gripper_activated : 31|1@0+ (1,0) [0|1] "" Host
 SG_ gripper_action_status : 30|1@0+ (1,0) [0|1] "" Host
 SG_ gripper_object_detection_raw : 29|2@0+ (1,0) [0|3] "" Host
 SG_ gripper_temperature_error : 27|1@0+ (1,0) [0|1] "" Host
 SG_ gripper_timeout_error : 26|1@0+ (1,0) [0|1] "" Host
 SG_ gripper_estop_error : 25|1@0+ (1,0) [0|1] "" Host
 SG_ gripper_calibrated : 24|1@0+ (1,0) [0|1] "" Host

BO_ 900 Send_data_pack_1_N7: 8 Host
 SG_ Position_setpoint : 7|24@0- (1,0) [-8388608|8388607] "" Driver7
 SG_ Speed_feedforward : 31|24@0- (1,0) [-8388608|8388607] "" Driver7
 SG_ Current_feedforward : 55|16@0- (1,0) [-32768|32767] "" Driver7

BO_ 904 Send_data_pack_PD_N7: 8 Host
 SG_ Position_setpoint : 7|24@0- (1,0) [-8388608|8388607] "" Driver7
 SG_ Speed_setpoint : 31|24@0- (1,0) [-8388608|8388607] "" Driver7
 SG_ Current_feedforward : 55|16@0- (1,0) [-32768|32767] "" Driver7

BO_ 958 Send_data_pack_HALL_N7: 4 Host
 SG_ Speed : 7|24@0- (1,0) [-8388608|8388607] "" Driver7
 SG_ Trigger : 31|8@0+ (1,0) [0|255] "" Driver7

BO_ 902 Respond_data_pack_1_N7: 8 Driver7
 SG_ position : 7|24@0- (1,0) [-8388608|8388607] "" Host
 SG_ speed : 31|24@0- (1,0) [-8388608|8388607] "" Host
 SG_ current : 55|16@0- (1,0) [-32768|32767] "" Host

BO_ 903 Respond_data_pack_1_N7_Fault: 8 Driver7
 SG_ position : 7|24@0- (1,0) [-8388608|8388607] "" Host
 SG_ speed : 31|24@0- (1,0) [-8388608|8388607] "" Host
 SG_ current : 55|16@0- (1,0) [-32768|32767] "" Host

BO_ 960 Respond_data_hall_N7: 4 Driver7
 SG_ position : 7|24@0- (1,0) [-8388608|8388607] "" Host
 SG_ HALL_trigger : 31|1@0+ (1,0) [0|1] "" Host
 SG_ additional_pin2 : 30|1@0+ (1,0) [0|1] "" Host
 SG_ hall_index : 29|1@0+ (1,0) [0|1] "" Host

BO_ 961 Respond_data_hall_N7_Fault: 4 Driver7
 SG_ position : 7|24@0- (1,0) [-8388608|8388607] "" Host
 SG_ HALL_trigger : 31|1@0+ (1,0) [0|1] "" Host
 SG_ additional_pin2 : 30|1@0+ (1,0) [0|1] "" Host
 SG_ hall_index : 29|1@0+ (1,0) [0|1] "" Host

CM_ "Source commit 56741ac67678. Combined clean/fault reply IDs; nodes 0-13. Send_data_pack_1 uses DLC 8. RTR requests and the empty gripper poll have no signal layout.";
CM_ SG_ 4 Position_setpoint "encoder ticks";
CM_ SG_ 4 Speed_feedforward "encoder ticks/s";
CM_ SG_ 4 Current_feedforward "mA";
CM_ SG_ 8 Position_setpoint "encoder ticks";
CM_ SG_ 8 Speed_setpoint "encoder ticks/s";
CM_ SG_ 8 Current_feedforward "mA";
CM_ SG_ 62 Speed "encoder ticks/s; the sign gives the direction";
CM_ SG_ 62 Trigger "0 = trigger when the pin is low, 1 = when it is high, 2 = on any edge";
CM_ SG_ 6 position "encoder ticks";
CM_ SG_ 6 speed "encoder ticks/s";
CM_ SG_ 6 current "Iq in mA";
CM_ SG_ 7 position "encoder ticks";
CM_ SG_ 7 speed "encoder ticks/s";
CM_ SG_ 7 current "Iq in mA";
CM_ SG_ 64 position "encoder ticks";
CM_ SG_ 64 HALL_trigger "1 while the driver waits for the trigger (with a level trigger, also again after the pin left the level), 0 while it holds";
CM_ SG_ 64 additional_pin2 "the raw level of the ADDITIONAL2 pin";
CM_ SG_ 64 hall_index "1 once the trigger has been seen (latched)";
CM_ SG_ 65 position "encoder ticks";
CM_ SG_ 65 HALL_trigger "1 while the driver waits for the trigger (with a level trigger, also again after the pin left the level), 0 while it holds";
CM_ SG_ 65 additional_pin2 "the raw level of the ADDITIONAL2 pin";
CM_ SG_ 65 hall_index "1 once the trigger has been seen (latched)";
CM_ SG_ 40 Speed_limit "encoder ticks/s";
CM_ SG_ 40 Current_limit "mA";
CM_ SG_ 44 Kt "Nm/A";
CM_ SG_ 68 Voltage_limit "mV; 0 = Vbus";
CM_ SG_ 46 temperature "\u00b0C";
CM_ SG_ 47 temperature "\u00b0C";
CM_ SG_ 48 voltage "mV";
CM_ SG_ 49 voltage "mV";
CM_ SG_ 50 HARDWARE_VERSION "PCB revision";
CM_ SG_ 50 BATCH_DATE "production batch";
CM_ SG_ 50 SOFTWARE_VERSION "firmware release, e.g. 108";
CM_ SG_ 50 SERIAL_NUMBER "serial number as held in RAM: 1 after a power-up";
CM_ SG_ 51 HARDWARE_VERSION "PCB revision";
CM_ SG_ 51 BATCH_DATE "production batch";
CM_ SG_ 51 SOFTWARE_VERSION "firmware release, e.g. 108";
CM_ SG_ 51 SERIAL_NUMBER "serial number as held in RAM: 1 after a power-up";
CM_ SG_ 52 error "any error is active";
CM_ SG_ 52 temperature_error "motor over the temperature limit";
CM_ SG_ 52 encoder_error "the encoder reports no magnet (too weak a field)";
CM_ SG_ 52 vbus_error "supply voltage outside the limits";
CM_ SG_ 52 driver_error "reserved; never set by this firmware (STEPFOC does not read a fault output of its driver stage)";
CM_ SG_ 52 velocity_error "speed above 30,000,000 ticks/s, a fixed threshold (not #Vlimit)";
CM_ SG_ 52 current_error "reserved; never set by this firmware";
CM_ SG_ 52 estop_error "Send_ESTOP was received";
CM_ SG_ 52 calibrated "the motor is calibrated";
CM_ SG_ 52 activated "the controller is activated";
CM_ SG_ 52 watchdog_error "the watchdog ran out";
CM_ SG_ 52 wrong_product "from firmware 109: this firmware is on the other product's board (the product lock) and drives nothing";
CM_ SG_ 53 error "any error is active";
CM_ SG_ 53 temperature_error "motor over the temperature limit";
CM_ SG_ 53 encoder_error "the encoder reports no magnet (too weak a field)";
CM_ SG_ 53 vbus_error "supply voltage outside the limits";
CM_ SG_ 53 driver_error "reserved; never set by this firmware (STEPFOC does not read a fault output of its driver stage)";
CM_ SG_ 53 velocity_error "speed above 30,000,000 ticks/s, a fixed threshold (not #Vlimit)";
CM_ SG_ 53 current_error "reserved; never set by this firmware";
CM_ SG_ 53 estop_error "Send_ESTOP was received";
CM_ SG_ 53 calibrated "the motor is calibrated";
CM_ SG_ 53 activated "the controller is activated";
CM_ SG_ 53 watchdog_error "the watchdog ran out";
CM_ SG_ 53 wrong_product "from firmware 109: this firmware is on the other product's board (the product lock) and drives nothing";
CM_ SG_ 54 current "mA";
CM_ SG_ 55 current "mA";
CM_ SG_ 56 position "encoder ticks";
CM_ SG_ 56 speed "encoder ticks/s";
CM_ SG_ 57 position "encoder ticks";
CM_ SG_ 57 speed "encoder ticks/s";
CM_ SG_ 66 Kt "Nm/A";
CM_ SG_ 67 Kt "Nm/A";
CM_ SG_ 78 product "1 STEPFOC, 2 Spectral Micro: the firmware that answers";
CM_ SG_ 78 tool_id "parameter 1: 0 none, 1 SSG-48, 11-33 MSG, 200-254 your own";
CM_ SG_ 78 firmware_version "the release, e.g. 109";
CM_ SG_ 78 hardware_version "PCB revision from the EEPROM";
CM_ SG_ 78 pole_pairs "the motor's pole pairs; 0 if outside 0-255";
CM_ SG_ 78 calibrated "1 calibrated, 0 not";
CM_ SG_ 78 gripper "the driver is set up as a gripper (#Gripper 1)";
CM_ SG_ 78 brake_on_idle "idle brakes (1) or coasts (0)";
CM_ SG_ 78 commutation_reversed "calibration found the coils wired the other way round";
CM_ SG_ 78 settings_block2 "the EEPROM has the bank settings block 2 lives in, so parameters 1-5 can be saved";
CM_ SG_ 78 wrong_product "this firmware is on the other product's board (the product lock) and drives nothing";
CM_ SG_ 78 sense_zero_measured "the current-sense zero was measured at start-up and is plausible";
CM_ SG_ 78 cogging_saved "the anti-cogging in use is the one saved in the EEPROM";
CM_ SG_ 78 switching_zero_in_use "the current-sense zero measured with the bridge switching is in use (parameter 46)";
CM_ SG_ 79 product "1 STEPFOC, 2 Spectral Micro: the firmware that answers";
CM_ SG_ 79 tool_id "parameter 1: 0 none, 1 SSG-48, 11-33 MSG, 200-254 your own";
CM_ SG_ 79 firmware_version "the release, e.g. 109";
CM_ SG_ 79 hardware_version "PCB revision from the EEPROM";
CM_ SG_ 79 pole_pairs "the motor's pole pairs; 0 if outside 0-255";
CM_ SG_ 79 calibrated "1 calibrated, 0 not";
CM_ SG_ 79 gripper "the driver is set up as a gripper (#Gripper 1)";
CM_ SG_ 79 brake_on_idle "idle brakes (1) or coasts (0)";
CM_ SG_ 79 commutation_reversed "calibration found the coils wired the other way round";
CM_ SG_ 79 settings_block2 "the EEPROM has the bank settings block 2 lives in, so parameters 1-5 can be saved";
CM_ SG_ 79 wrong_product "this firmware is on the other product's board (the product lock) and drives nothing";
CM_ SG_ 79 sense_zero_measured "the current-sense zero was measured at start-up and is plausible";
CM_ SG_ 79 cogging_saved "the anti-cogging in use is the one saved in the EEPROM";
CM_ SG_ 79 switching_zero_in_use "the current-sense zero measured with the bridge switching is in use (parameter 46)";
CM_ SG_ 80 temperature "\u00b0C (meaningful with the thermistor enabled)";
CM_ SG_ 80 voltage "supply voltage in mV";
CM_ SG_ 80 errors_1 "the error flags, as byte 0 of Send_Respond_State_of_Errors";
CM_ SG_ 80 errors_2 "calibrated, activated, watchdog, wrong product, as byte 1 of Send_Respond_State_of_Errors";
CM_ SG_ 80 current "Iq in mA";
CM_ SG_ 81 temperature "\u00b0C (meaningful with the thermistor enabled)";
CM_ SG_ 81 voltage "supply voltage in mV";
CM_ SG_ 81 errors_1 "the error flags, as byte 0 of Send_Respond_State_of_Errors";
CM_ SG_ 81 errors_2 "calibrated, activated, watchdog, wrong product, as byte 1 of Send_Respond_State_of_Errors";
CM_ SG_ 81 current "Iq in mA";
CM_ SG_ 22 ID "0 to 13; 14 and 15 are accepted but reserved by the bootloader";
CM_ SG_ 30 Time "ms; 0 = off";
CM_ SG_ 30 Action "0 legacy (brake or coast as idle does), 1 hold the position, 2 brake, 3 coast, 4 descend at the fallback current and speed; other values act as 0";
CM_ SG_ 60 Interval "ms; 0 = off";
CM_ SG_ 70 Mask "bit 0 = write the idle behaviour";
CM_ SG_ 70 Value "bit 0: 1 brake, 0 coast";
CM_ SG_ 72 Parameter "the parameter number, 1-87";
CM_ SG_ 72 Value "the new value, in the parameter's unit; for the gains, limits and Kt (8-16, 20) a float's bit pattern";
CM_ SG_ 74 Parameter "the parameter number";
CM_ SG_ 76 parameter "the parameter number";
CM_ SG_ 76 value "the value in force; a float's bits for 8-16 and 20";
CM_ SG_ 77 parameter "the parameter number";
CM_ SG_ 77 value "the value in force; a float's bits for 8-16 and 20";
CM_ SG_ 82 Kind "0 capture (up to 1024 samples: parameter 32 says how many), 1 histogram (256 bins), 2 anti-cogging harmonics (8 slots), 3 anti-cogging table (256 values), 4 encoder table (128 values)";
CM_ SG_ 82 First "the first index";
CM_ SG_ 82 Count "how many entries; 0 cancels a read-out";
CM_ SG_ 84 header "kind \u00d7 8192 + index";
CM_ SG_ 84 word_a "capture: channel A; histogram: the count (unsigned); harmonics: the harmonic number (0 = slot unused); tables: entry index";
CM_ SG_ 84 word_b "capture: channel B; histogram: the sum's upper 16 bits; harmonics: a, the cosine term in mA; tables: entry index + 1";
CM_ SG_ 84 word_c "capture: channel C; histogram: the sum's lower 16 bits; harmonics: b, the sine term in mA; tables: entry index + 2 (0 past the end)";
CM_ SG_ 85 header "kind \u00d7 8192 + index";
CM_ SG_ 85 word_a "capture: channel A; histogram: the count (unsigned); harmonics: the harmonic number (0 = slot unused); tables: entry index";
CM_ SG_ 85 word_b "capture: channel B; histogram: the sum's upper 16 bits; harmonics: a, the cosine term in mA; tables: entry index + 1";
CM_ SG_ 85 word_c "capture: channel C; histogram: the sum's lower 16 bits; harmonics: b, the sine term in mA; tables: entry index + 2 (0 past the end)";
CM_ SG_ 86 Header "kind \u00d7 8192 + index; kind 2 or 3";
CM_ SG_ 86 Word_A "kind 2: the harmonic (1-32, 0 = unused); kind 3: value at index";
CM_ SG_ 86 Word_B "kind 2: a in mA; kind 3: value at index + 1";
CM_ SG_ 86 Word_C "kind 2: b in mA; kind 3: value at index + 2";
CM_ SG_ 88 Operation "0 stop everything (tones, queue, samples); 1 a tone now; 2 add an event to the queue; 3 play the queue; 4 play the samples; 5 samples off, buffer cleared; 6 clear the queue (tones that sound keep sounding)";
CM_ SG_ 88 Channel "the tone channel, 0-3 (operations 1 and 2)";
CM_ SG_ 88 A "1, 2: the pitch in Hz (2: 0 silences the channel); 4: the sample rate in Hz, at most the loop rate";
CM_ SG_ 88 B "1, 2: the loudness in mA; 4: the voltage of a full-scale sample in mV";
CM_ SG_ 88 C "1: the duration in ms, 0 = until stopped; 2: the wait in ms before the next event, 0 = the next one starts with it";
CM_ SG_ 90 Sample_1 "the next sample";
CM_ SG_ 122 Position "0 fully open, 255 fully closed";
CM_ SG_ 122 Speed "0 slowest, 255 fastest";
CM_ SG_ 122 Current "current limit of the move in mA; from firmware 109 the move uses its magnitude, at most the driver's 2800 mA; see the gripper manual for the safe range";
CM_ SG_ 122 Activate "1 activate the gripper, 0 deactivate";
CM_ SG_ 122 Action "1 go to the position, 0 idle";
CM_ SG_ 122 E_stop "1 raises the gripper E-stop error, again on every control cycle until a frame with this bit 0 arrives; then Send_Clear_Error";
CM_ SG_ 122 Release_direction "read by the firmware but not used";
CM_ SG_ 120 gripper_position "0 fully open, 255 fully closed";
CM_ SG_ 120 gripper_current "measured current in mA";
CM_ SG_ 120 gripper_activated "1 activated";
CM_ SG_ 120 gripper_action_status "the action bit of the last Send_gripper_data_pack (1 after #Grippos); the driver never clears it, so it stays 1 after the move ends: the object detection tells when the move has ended";
CM_ SG_ 120 gripper_object_detection_raw "bit 5 is the low bit, bit 4 the high bit: 0 moving, 1 object detected while closing, 2 object detected while opening, 3 at the position; raw bit pair, see value labels (wire order differs from numeric status)";
CM_ SG_ 120 gripper_temperature_error "a copy of the thermistor temperature error";
CM_ SG_ 120 gripper_timeout_error "a copy of the CAN watchdog error (Send_Watchdog), not a move timeout";
CM_ SG_ 120 gripper_estop_error "the E-stop bit of Send_gripper_data_pack (or #Gripstop 1) was set";
CM_ SG_ 120 gripper_calibrated "1 calibrated";
CM_ SG_ 121 gripper_position "0 fully open, 255 fully closed";
CM_ SG_ 121 gripper_current "measured current in mA";
CM_ SG_ 121 gripper_activated "1 activated";
CM_ SG_ 121 gripper_action_status "the action bit of the last Send_gripper_data_pack (1 after #Grippos); the driver never clears it, so it stays 1 after the move ends: the object detection tells when the move has ended";
CM_ SG_ 121 gripper_object_detection_raw "bit 5 is the low bit, bit 4 the high bit: 0 moving, 1 object detected while closing, 2 object detected while opening, 3 at the position; raw bit pair, see value labels (wire order differs from numeric status)";
CM_ SG_ 121 gripper_temperature_error "a copy of the thermistor temperature error";
CM_ SG_ 121 gripper_timeout_error "a copy of the CAN watchdog error (Send_Watchdog), not a move timeout";
CM_ SG_ 121 gripper_estop_error "the E-stop bit of Send_gripper_data_pack (or #Gripstop 1) was set";
CM_ SG_ 121 gripper_calibrated "1 calibrated";
CM_ SG_ 132 Position_setpoint "encoder ticks";
CM_ SG_ 132 Speed_feedforward "encoder ticks/s";
CM_ SG_ 132 Current_feedforward "mA";
CM_ SG_ 136 Position_setpoint "encoder ticks";
CM_ SG_ 136 Speed_setpoint "encoder ticks/s";
CM_ SG_ 136 Current_feedforward "mA";
CM_ SG_ 190 Speed "encoder ticks/s; the sign gives the direction";
CM_ SG_ 190 Trigger "0 = trigger when the pin is low, 1 = when it is high, 2 = on any edge";
CM_ SG_ 134 position "encoder ticks";
CM_ SG_ 134 speed "encoder ticks/s";
CM_ SG_ 134 current "Iq in mA";
CM_ SG_ 135 position "encoder ticks";
CM_ SG_ 135 speed "encoder ticks/s";
CM_ SG_ 135 current "Iq in mA";
CM_ SG_ 192 position "encoder ticks";
CM_ SG_ 192 HALL_trigger "1 while the driver waits for the trigger (with a level trigger, also again after the pin left the level), 0 while it holds";
CM_ SG_ 192 additional_pin2 "the raw level of the ADDITIONAL2 pin";
CM_ SG_ 192 hall_index "1 once the trigger has been seen (latched)";
CM_ SG_ 193 position "encoder ticks";
CM_ SG_ 193 HALL_trigger "1 while the driver waits for the trigger (with a level trigger, also again after the pin left the level), 0 while it holds";
CM_ SG_ 193 additional_pin2 "the raw level of the ADDITIONAL2 pin";
CM_ SG_ 193 hall_index "1 once the trigger has been seen (latched)";
CM_ SG_ 168 Speed_limit "encoder ticks/s";
CM_ SG_ 168 Current_limit "mA";
CM_ SG_ 172 Kt "Nm/A";
CM_ SG_ 196 Voltage_limit "mV; 0 = Vbus";
CM_ SG_ 174 temperature "\u00b0C";
CM_ SG_ 175 temperature "\u00b0C";
CM_ SG_ 176 voltage "mV";
CM_ SG_ 177 voltage "mV";
CM_ SG_ 178 HARDWARE_VERSION "PCB revision";
CM_ SG_ 178 BATCH_DATE "production batch";
CM_ SG_ 178 SOFTWARE_VERSION "firmware release, e.g. 108";
CM_ SG_ 178 SERIAL_NUMBER "serial number as held in RAM: 1 after a power-up";
CM_ SG_ 179 HARDWARE_VERSION "PCB revision";
CM_ SG_ 179 BATCH_DATE "production batch";
CM_ SG_ 179 SOFTWARE_VERSION "firmware release, e.g. 108";
CM_ SG_ 179 SERIAL_NUMBER "serial number as held in RAM: 1 after a power-up";
CM_ SG_ 180 error "any error is active";
CM_ SG_ 180 temperature_error "motor over the temperature limit";
CM_ SG_ 180 encoder_error "the encoder reports no magnet (too weak a field)";
CM_ SG_ 180 vbus_error "supply voltage outside the limits";
CM_ SG_ 180 driver_error "reserved; never set by this firmware (STEPFOC does not read a fault output of its driver stage)";
CM_ SG_ 180 velocity_error "speed above 30,000,000 ticks/s, a fixed threshold (not #Vlimit)";
CM_ SG_ 180 current_error "reserved; never set by this firmware";
CM_ SG_ 180 estop_error "Send_ESTOP was received";
CM_ SG_ 180 calibrated "the motor is calibrated";
CM_ SG_ 180 activated "the controller is activated";
CM_ SG_ 180 watchdog_error "the watchdog ran out";
CM_ SG_ 180 wrong_product "from firmware 109: this firmware is on the other product's board (the product lock) and drives nothing";
CM_ SG_ 181 error "any error is active";
CM_ SG_ 181 temperature_error "motor over the temperature limit";
CM_ SG_ 181 encoder_error "the encoder reports no magnet (too weak a field)";
CM_ SG_ 181 vbus_error "supply voltage outside the limits";
CM_ SG_ 181 driver_error "reserved; never set by this firmware (STEPFOC does not read a fault output of its driver stage)";
CM_ SG_ 181 velocity_error "speed above 30,000,000 ticks/s, a fixed threshold (not #Vlimit)";
CM_ SG_ 181 current_error "reserved; never set by this firmware";
CM_ SG_ 181 estop_error "Send_ESTOP was received";
CM_ SG_ 181 calibrated "the motor is calibrated";
CM_ SG_ 181 activated "the controller is activated";
CM_ SG_ 181 watchdog_error "the watchdog ran out";
CM_ SG_ 181 wrong_product "from firmware 109: this firmware is on the other product's board (the product lock) and drives nothing";
CM_ SG_ 182 current "mA";
CM_ SG_ 183 current "mA";
CM_ SG_ 184 position "encoder ticks";
CM_ SG_ 184 speed "encoder ticks/s";
CM_ SG_ 185 position "encoder ticks";
CM_ SG_ 185 speed "encoder ticks/s";
CM_ SG_ 194 Kt "Nm/A";
CM_ SG_ 195 Kt "Nm/A";
CM_ SG_ 206 product "1 STEPFOC, 2 Spectral Micro: the firmware that answers";
CM_ SG_ 206 tool_id "parameter 1: 0 none, 1 SSG-48, 11-33 MSG, 200-254 your own";
CM_ SG_ 206 firmware_version "the release, e.g. 109";
CM_ SG_ 206 hardware_version "PCB revision from the EEPROM";
CM_ SG_ 206 pole_pairs "the motor's pole pairs; 0 if outside 0-255";
CM_ SG_ 206 calibrated "1 calibrated, 0 not";
CM_ SG_ 206 gripper "the driver is set up as a gripper (#Gripper 1)";
CM_ SG_ 206 brake_on_idle "idle brakes (1) or coasts (0)";
CM_ SG_ 206 commutation_reversed "calibration found the coils wired the other way round";
CM_ SG_ 206 settings_block2 "the EEPROM has the bank settings block 2 lives in, so parameters 1-5 can be saved";
CM_ SG_ 206 wrong_product "this firmware is on the other product's board (the product lock) and drives nothing";
CM_ SG_ 206 sense_zero_measured "the current-sense zero was measured at start-up and is plausible";
CM_ SG_ 206 cogging_saved "the anti-cogging in use is the one saved in the EEPROM";
CM_ SG_ 206 switching_zero_in_use "the current-sense zero measured with the bridge switching is in use (parameter 46)";
CM_ SG_ 207 product "1 STEPFOC, 2 Spectral Micro: the firmware that answers";
CM_ SG_ 207 tool_id "parameter 1: 0 none, 1 SSG-48, 11-33 MSG, 200-254 your own";
CM_ SG_ 207 firmware_version "the release, e.g. 109";
CM_ SG_ 207 hardware_version "PCB revision from the EEPROM";
CM_ SG_ 207 pole_pairs "the motor's pole pairs; 0 if outside 0-255";
CM_ SG_ 207 calibrated "1 calibrated, 0 not";
CM_ SG_ 207 gripper "the driver is set up as a gripper (#Gripper 1)";
CM_ SG_ 207 brake_on_idle "idle brakes (1) or coasts (0)";
CM_ SG_ 207 commutation_reversed "calibration found the coils wired the other way round";
CM_ SG_ 207 settings_block2 "the EEPROM has the bank settings block 2 lives in, so parameters 1-5 can be saved";
CM_ SG_ 207 wrong_product "this firmware is on the other product's board (the product lock) and drives nothing";
CM_ SG_ 207 sense_zero_measured "the current-sense zero was measured at start-up and is plausible";
CM_ SG_ 207 cogging_saved "the anti-cogging in use is the one saved in the EEPROM";
CM_ SG_ 207 switching_zero_in_use "the current-sense zero measured with the bridge switching is in use (parameter 46)";
CM_ SG_ 208 temperature "\u00b0C (meaningful with the thermistor enabled)";
CM_ SG_ 208 voltage "supply voltage in mV";
CM_ SG_ 208 errors_1 "the error flags, as byte 0 of Send_Respond_State_of_Errors";
CM_ SG_ 208 errors_2 "calibrated, activated, watchdog, wrong product, as byte 1 of Send_Respond_State_of_Errors";
CM_ SG_ 208 current "Iq in mA";
CM_ SG_ 209 temperature "\u00b0C (meaningful with the thermistor enabled)";
CM_ SG_ 209 voltage "supply voltage in mV";
CM_ SG_ 209 errors_1 "the error flags, as byte 0 of Send_Respond_State_of_Errors";
CM_ SG_ 209 errors_2 "calibrated, activated, watchdog, wrong product, as byte 1 of Send_Respond_State_of_Errors";
CM_ SG_ 209 current "Iq in mA";
CM_ SG_ 150 ID "0 to 13; 14 and 15 are accepted but reserved by the bootloader";
CM_ SG_ 158 Time "ms; 0 = off";
CM_ SG_ 158 Action "0 legacy (brake or coast as idle does), 1 hold the position, 2 brake, 3 coast, 4 descend at the fallback current and speed; other values act as 0";
CM_ SG_ 188 Interval "ms; 0 = off";
CM_ SG_ 198 Mask "bit 0 = write the idle behaviour";
CM_ SG_ 198 Value "bit 0: 1 brake, 0 coast";
CM_ SG_ 200 Parameter "the parameter number, 1-87";
CM_ SG_ 200 Value "the new value, in the parameter's unit; for the gains, limits and Kt (8-16, 20) a float's bit pattern";
CM_ SG_ 202 Parameter "the parameter number";
CM_ SG_ 204 parameter "the parameter number";
CM_ SG_ 204 value "the value in force; a float's bits for 8-16 and 20";
CM_ SG_ 205 parameter "the parameter number";
CM_ SG_ 205 value "the value in force; a float's bits for 8-16 and 20";
CM_ SG_ 210 Kind "0 capture (up to 1024 samples: parameter 32 says how many), 1 histogram (256 bins), 2 anti-cogging harmonics (8 slots), 3 anti-cogging table (256 values), 4 encoder table (128 values)";
CM_ SG_ 210 First "the first index";
CM_ SG_ 210 Count "how many entries; 0 cancels a read-out";
CM_ SG_ 212 header "kind \u00d7 8192 + index";
CM_ SG_ 212 word_a "capture: channel A; histogram: the count (unsigned); harmonics: the harmonic number (0 = slot unused); tables: entry index";
CM_ SG_ 212 word_b "capture: channel B; histogram: the sum's upper 16 bits; harmonics: a, the cosine term in mA; tables: entry index + 1";
CM_ SG_ 212 word_c "capture: channel C; histogram: the sum's lower 16 bits; harmonics: b, the sine term in mA; tables: entry index + 2 (0 past the end)";
CM_ SG_ 213 header "kind \u00d7 8192 + index";
CM_ SG_ 213 word_a "capture: channel A; histogram: the count (unsigned); harmonics: the harmonic number (0 = slot unused); tables: entry index";
CM_ SG_ 213 word_b "capture: channel B; histogram: the sum's upper 16 bits; harmonics: a, the cosine term in mA; tables: entry index + 1";
CM_ SG_ 213 word_c "capture: channel C; histogram: the sum's lower 16 bits; harmonics: b, the sine term in mA; tables: entry index + 2 (0 past the end)";
CM_ SG_ 214 Header "kind \u00d7 8192 + index; kind 2 or 3";
CM_ SG_ 214 Word_A "kind 2: the harmonic (1-32, 0 = unused); kind 3: value at index";
CM_ SG_ 214 Word_B "kind 2: a in mA; kind 3: value at index + 1";
CM_ SG_ 214 Word_C "kind 2: b in mA; kind 3: value at index + 2";
CM_ SG_ 216 Operation "0 stop everything (tones, queue, samples); 1 a tone now; 2 add an event to the queue; 3 play the queue; 4 play the samples; 5 samples off, buffer cleared; 6 clear the queue (tones that sound keep sounding)";
CM_ SG_ 216 Channel "the tone channel, 0-3 (operations 1 and 2)";
CM_ SG_ 216 A "1, 2: the pitch in Hz (2: 0 silences the channel); 4: the sample rate in Hz, at most the loop rate";
CM_ SG_ 216 B "1, 2: the loudness in mA; 4: the voltage of a full-scale sample in mV";
CM_ SG_ 216 C "1: the duration in ms, 0 = until stopped; 2: the wait in ms before the next event, 0 = the next one starts with it";
CM_ SG_ 218 Sample_1 "the next sample";
CM_ SG_ 250 Position "0 fully open, 255 fully closed";
CM_ SG_ 250 Speed "0 slowest, 255 fastest";
CM_ SG_ 250 Current "current limit of the move in mA; from firmware 109 the move uses its magnitude, at most the driver's 2800 mA; see the gripper manual for the safe range";
CM_ SG_ 250 Activate "1 activate the gripper, 0 deactivate";
CM_ SG_ 250 Action "1 go to the position, 0 idle";
CM_ SG_ 250 E_stop "1 raises the gripper E-stop error, again on every control cycle until a frame with this bit 0 arrives; then Send_Clear_Error";
CM_ SG_ 250 Release_direction "read by the firmware but not used";
CM_ SG_ 248 gripper_position "0 fully open, 255 fully closed";
CM_ SG_ 248 gripper_current "measured current in mA";
CM_ SG_ 248 gripper_activated "1 activated";
CM_ SG_ 248 gripper_action_status "the action bit of the last Send_gripper_data_pack (1 after #Grippos); the driver never clears it, so it stays 1 after the move ends: the object detection tells when the move has ended";
CM_ SG_ 248 gripper_object_detection_raw "bit 5 is the low bit, bit 4 the high bit: 0 moving, 1 object detected while closing, 2 object detected while opening, 3 at the position; raw bit pair, see value labels (wire order differs from numeric status)";
CM_ SG_ 248 gripper_temperature_error "a copy of the thermistor temperature error";
CM_ SG_ 248 gripper_timeout_error "a copy of the CAN watchdog error (Send_Watchdog), not a move timeout";
CM_ SG_ 248 gripper_estop_error "the E-stop bit of Send_gripper_data_pack (or #Gripstop 1) was set";
CM_ SG_ 248 gripper_calibrated "1 calibrated";
CM_ SG_ 249 gripper_position "0 fully open, 255 fully closed";
CM_ SG_ 249 gripper_current "measured current in mA";
CM_ SG_ 249 gripper_activated "1 activated";
CM_ SG_ 249 gripper_action_status "the action bit of the last Send_gripper_data_pack (1 after #Grippos); the driver never clears it, so it stays 1 after the move ends: the object detection tells when the move has ended";
CM_ SG_ 249 gripper_object_detection_raw "bit 5 is the low bit, bit 4 the high bit: 0 moving, 1 object detected while closing, 2 object detected while opening, 3 at the position; raw bit pair, see value labels (wire order differs from numeric status)";
CM_ SG_ 249 gripper_temperature_error "a copy of the thermistor temperature error";
CM_ SG_ 249 gripper_timeout_error "a copy of the CAN watchdog error (Send_Watchdog), not a move timeout";
CM_ SG_ 249 gripper_estop_error "the E-stop bit of Send_gripper_data_pack (or #Gripstop 1) was set";
CM_ SG_ 249 gripper_calibrated "1 calibrated";
CM_ SG_ 260 Position_setpoint "encoder ticks";
CM_ SG_ 260 Speed_feedforward "encoder ticks/s";
CM_ SG_ 260 Current_feedforward "mA";
CM_ SG_ 264 Position_setpoint "encoder ticks";
CM_ SG_ 264 Speed_setpoint "encoder ticks/s";
CM_ SG_ 264 Current_feedforward "mA";
CM_ SG_ 318 Speed "encoder ticks/s; the sign gives the direction";
CM_ SG_ 318 Trigger "0 = trigger when the pin is low, 1 = when it is high, 2 = on any edge";
CM_ SG_ 262 position "encoder ticks";
CM_ SG_ 262 speed "encoder ticks/s";
CM_ SG_ 262 current "Iq in mA";
CM_ SG_ 263 position "encoder ticks";
CM_ SG_ 263 speed "encoder ticks/s";
CM_ SG_ 263 current "Iq in mA";
CM_ SG_ 320 position "encoder ticks";
CM_ SG_ 320 HALL_trigger "1 while the driver waits for the trigger (with a level trigger, also again after the pin left the level), 0 while it holds";
CM_ SG_ 320 additional_pin2 "the raw level of the ADDITIONAL2 pin";
CM_ SG_ 320 hall_index "1 once the trigger has been seen (latched)";
CM_ SG_ 321 position "encoder ticks";
CM_ SG_ 321 HALL_trigger "1 while the driver waits for the trigger (with a level trigger, also again after the pin left the level), 0 while it holds";
CM_ SG_ 321 additional_pin2 "the raw level of the ADDITIONAL2 pin";
CM_ SG_ 321 hall_index "1 once the trigger has been seen (latched)";
CM_ SG_ 296 Speed_limit "encoder ticks/s";
CM_ SG_ 296 Current_limit "mA";
CM_ SG_ 300 Kt "Nm/A";
CM_ SG_ 324 Voltage_limit "mV; 0 = Vbus";
CM_ SG_ 302 temperature "\u00b0C";
CM_ SG_ 303 temperature "\u00b0C";
CM_ SG_ 304 voltage "mV";
CM_ SG_ 305 voltage "mV";
CM_ SG_ 306 HARDWARE_VERSION "PCB revision";
CM_ SG_ 306 BATCH_DATE "production batch";
CM_ SG_ 306 SOFTWARE_VERSION "firmware release, e.g. 108";
CM_ SG_ 306 SERIAL_NUMBER "serial number as held in RAM: 1 after a power-up";
CM_ SG_ 307 HARDWARE_VERSION "PCB revision";
CM_ SG_ 307 BATCH_DATE "production batch";
CM_ SG_ 307 SOFTWARE_VERSION "firmware release, e.g. 108";
CM_ SG_ 307 SERIAL_NUMBER "serial number as held in RAM: 1 after a power-up";
CM_ SG_ 308 error "any error is active";
CM_ SG_ 308 temperature_error "motor over the temperature limit";
CM_ SG_ 308 encoder_error "the encoder reports no magnet (too weak a field)";
CM_ SG_ 308 vbus_error "supply voltage outside the limits";
CM_ SG_ 308 driver_error "reserved; never set by this firmware (STEPFOC does not read a fault output of its driver stage)";
CM_ SG_ 308 velocity_error "speed above 30,000,000 ticks/s, a fixed threshold (not #Vlimit)";
CM_ SG_ 308 current_error "reserved; never set by this firmware";
CM_ SG_ 308 estop_error "Send_ESTOP was received";
CM_ SG_ 308 calibrated "the motor is calibrated";
CM_ SG_ 308 activated "the controller is activated";
CM_ SG_ 308 watchdog_error "the watchdog ran out";
CM_ SG_ 308 wrong_product "from firmware 109: this firmware is on the other product's board (the product lock) and drives nothing";
CM_ SG_ 309 error "any error is active";
CM_ SG_ 309 temperature_error "motor over the temperature limit";
CM_ SG_ 309 encoder_error "the encoder reports no magnet (too weak a field)";
CM_ SG_ 309 vbus_error "supply voltage outside the limits";
CM_ SG_ 309 driver_error "reserved; never set by this firmware (STEPFOC does not read a fault output of its driver stage)";
CM_ SG_ 309 velocity_error "speed above 30,000,000 ticks/s, a fixed threshold (not #Vlimit)";
CM_ SG_ 309 current_error "reserved; never set by this firmware";
CM_ SG_ 309 estop_error "Send_ESTOP was received";
CM_ SG_ 309 calibrated "the motor is calibrated";
CM_ SG_ 309 activated "the controller is activated";
CM_ SG_ 309 watchdog_error "the watchdog ran out";
CM_ SG_ 309 wrong_product "from firmware 109: this firmware is on the other product's board (the product lock) and drives nothing";
CM_ SG_ 310 current "mA";
CM_ SG_ 311 current "mA";
CM_ SG_ 312 position "encoder ticks";
CM_ SG_ 312 speed "encoder ticks/s";
CM_ SG_ 313 position "encoder ticks";
CM_ SG_ 313 speed "encoder ticks/s";
CM_ SG_ 322 Kt "Nm/A";
CM_ SG_ 323 Kt "Nm/A";
CM_ SG_ 334 product "1 STEPFOC, 2 Spectral Micro: the firmware that answers";
CM_ SG_ 334 tool_id "parameter 1: 0 none, 1 SSG-48, 11-33 MSG, 200-254 your own";
CM_ SG_ 334 firmware_version "the release, e.g. 109";
CM_ SG_ 334 hardware_version "PCB revision from the EEPROM";
CM_ SG_ 334 pole_pairs "the motor's pole pairs; 0 if outside 0-255";
CM_ SG_ 334 calibrated "1 calibrated, 0 not";
CM_ SG_ 334 gripper "the driver is set up as a gripper (#Gripper 1)";
CM_ SG_ 334 brake_on_idle "idle brakes (1) or coasts (0)";
CM_ SG_ 334 commutation_reversed "calibration found the coils wired the other way round";
CM_ SG_ 334 settings_block2 "the EEPROM has the bank settings block 2 lives in, so parameters 1-5 can be saved";
CM_ SG_ 334 wrong_product "this firmware is on the other product's board (the product lock) and drives nothing";
CM_ SG_ 334 sense_zero_measured "the current-sense zero was measured at start-up and is plausible";
CM_ SG_ 334 cogging_saved "the anti-cogging in use is the one saved in the EEPROM";
CM_ SG_ 334 switching_zero_in_use "the current-sense zero measured with the bridge switching is in use (parameter 46)";
CM_ SG_ 335 product "1 STEPFOC, 2 Spectral Micro: the firmware that answers";
CM_ SG_ 335 tool_id "parameter 1: 0 none, 1 SSG-48, 11-33 MSG, 200-254 your own";
CM_ SG_ 335 firmware_version "the release, e.g. 109";
CM_ SG_ 335 hardware_version "PCB revision from the EEPROM";
CM_ SG_ 335 pole_pairs "the motor's pole pairs; 0 if outside 0-255";
CM_ SG_ 335 calibrated "1 calibrated, 0 not";
CM_ SG_ 335 gripper "the driver is set up as a gripper (#Gripper 1)";
CM_ SG_ 335 brake_on_idle "idle brakes (1) or coasts (0)";
CM_ SG_ 335 commutation_reversed "calibration found the coils wired the other way round";
CM_ SG_ 335 settings_block2 "the EEPROM has the bank settings block 2 lives in, so parameters 1-5 can be saved";
CM_ SG_ 335 wrong_product "this firmware is on the other product's board (the product lock) and drives nothing";
CM_ SG_ 335 sense_zero_measured "the current-sense zero was measured at start-up and is plausible";
CM_ SG_ 335 cogging_saved "the anti-cogging in use is the one saved in the EEPROM";
CM_ SG_ 335 switching_zero_in_use "the current-sense zero measured with the bridge switching is in use (parameter 46)";
CM_ SG_ 336 temperature "\u00b0C (meaningful with the thermistor enabled)";
CM_ SG_ 336 voltage "supply voltage in mV";
CM_ SG_ 336 errors_1 "the error flags, as byte 0 of Send_Respond_State_of_Errors";
CM_ SG_ 336 errors_2 "calibrated, activated, watchdog, wrong product, as byte 1 of Send_Respond_State_of_Errors";
CM_ SG_ 336 current "Iq in mA";
CM_ SG_ 337 temperature "\u00b0C (meaningful with the thermistor enabled)";
CM_ SG_ 337 voltage "supply voltage in mV";
CM_ SG_ 337 errors_1 "the error flags, as byte 0 of Send_Respond_State_of_Errors";
CM_ SG_ 337 errors_2 "calibrated, activated, watchdog, wrong product, as byte 1 of Send_Respond_State_of_Errors";
CM_ SG_ 337 current "Iq in mA";
CM_ SG_ 278 ID "0 to 13; 14 and 15 are accepted but reserved by the bootloader";
CM_ SG_ 286 Time "ms; 0 = off";
CM_ SG_ 286 Action "0 legacy (brake or coast as idle does), 1 hold the position, 2 brake, 3 coast, 4 descend at the fallback current and speed; other values act as 0";
CM_ SG_ 316 Interval "ms; 0 = off";
CM_ SG_ 326 Mask "bit 0 = write the idle behaviour";
CM_ SG_ 326 Value "bit 0: 1 brake, 0 coast";
CM_ SG_ 328 Parameter "the parameter number, 1-87";
CM_ SG_ 328 Value "the new value, in the parameter's unit; for the gains, limits and Kt (8-16, 20) a float's bit pattern";
CM_ SG_ 330 Parameter "the parameter number";
CM_ SG_ 332 parameter "the parameter number";
CM_ SG_ 332 value "the value in force; a float's bits for 8-16 and 20";
CM_ SG_ 333 parameter "the parameter number";
CM_ SG_ 333 value "the value in force; a float's bits for 8-16 and 20";
CM_ SG_ 338 Kind "0 capture (up to 1024 samples: parameter 32 says how many), 1 histogram (256 bins), 2 anti-cogging harmonics (8 slots), 3 anti-cogging table (256 values), 4 encoder table (128 values)";
CM_ SG_ 338 First "the first index";
CM_ SG_ 338 Count "how many entries; 0 cancels a read-out";
CM_ SG_ 340 header "kind \u00d7 8192 + index";
CM_ SG_ 340 word_a "capture: channel A; histogram: the count (unsigned); harmonics: the harmonic number (0 = slot unused); tables: entry index";
CM_ SG_ 340 word_b "capture: channel B; histogram: the sum's upper 16 bits; harmonics: a, the cosine term in mA; tables: entry index + 1";
CM_ SG_ 340 word_c "capture: channel C; histogram: the sum's lower 16 bits; harmonics: b, the sine term in mA; tables: entry index + 2 (0 past the end)";
CM_ SG_ 341 header "kind \u00d7 8192 + index";
CM_ SG_ 341 word_a "capture: channel A; histogram: the count (unsigned); harmonics: the harmonic number (0 = slot unused); tables: entry index";
CM_ SG_ 341 word_b "capture: channel B; histogram: the sum's upper 16 bits; harmonics: a, the cosine term in mA; tables: entry index + 1";
CM_ SG_ 341 word_c "capture: channel C; histogram: the sum's lower 16 bits; harmonics: b, the sine term in mA; tables: entry index + 2 (0 past the end)";
CM_ SG_ 342 Header "kind \u00d7 8192 + index; kind 2 or 3";
CM_ SG_ 342 Word_A "kind 2: the harmonic (1-32, 0 = unused); kind 3: value at index";
CM_ SG_ 342 Word_B "kind 2: a in mA; kind 3: value at index + 1";
CM_ SG_ 342 Word_C "kind 2: b in mA; kind 3: value at index + 2";
CM_ SG_ 344 Operation "0 stop everything (tones, queue, samples); 1 a tone now; 2 add an event to the queue; 3 play the queue; 4 play the samples; 5 samples off, buffer cleared; 6 clear the queue (tones that sound keep sounding)";
CM_ SG_ 344 Channel "the tone channel, 0-3 (operations 1 and 2)";
CM_ SG_ 344 A "1, 2: the pitch in Hz (2: 0 silences the channel); 4: the sample rate in Hz, at most the loop rate";
CM_ SG_ 344 B "1, 2: the loudness in mA; 4: the voltage of a full-scale sample in mV";
CM_ SG_ 344 C "1: the duration in ms, 0 = until stopped; 2: the wait in ms before the next event, 0 = the next one starts with it";
CM_ SG_ 346 Sample_1 "the next sample";
CM_ SG_ 378 Position "0 fully open, 255 fully closed";
CM_ SG_ 378 Speed "0 slowest, 255 fastest";
CM_ SG_ 378 Current "current limit of the move in mA; from firmware 109 the move uses its magnitude, at most the driver's 2800 mA; see the gripper manual for the safe range";
CM_ SG_ 378 Activate "1 activate the gripper, 0 deactivate";
CM_ SG_ 378 Action "1 go to the position, 0 idle";
CM_ SG_ 378 E_stop "1 raises the gripper E-stop error, again on every control cycle until a frame with this bit 0 arrives; then Send_Clear_Error";
CM_ SG_ 378 Release_direction "read by the firmware but not used";
CM_ SG_ 376 gripper_position "0 fully open, 255 fully closed";
CM_ SG_ 376 gripper_current "measured current in mA";
CM_ SG_ 376 gripper_activated "1 activated";
CM_ SG_ 376 gripper_action_status "the action bit of the last Send_gripper_data_pack (1 after #Grippos); the driver never clears it, so it stays 1 after the move ends: the object detection tells when the move has ended";
CM_ SG_ 376 gripper_object_detection_raw "bit 5 is the low bit, bit 4 the high bit: 0 moving, 1 object detected while closing, 2 object detected while opening, 3 at the position; raw bit pair, see value labels (wire order differs from numeric status)";
CM_ SG_ 376 gripper_temperature_error "a copy of the thermistor temperature error";
CM_ SG_ 376 gripper_timeout_error "a copy of the CAN watchdog error (Send_Watchdog), not a move timeout";
CM_ SG_ 376 gripper_estop_error "the E-stop bit of Send_gripper_data_pack (or #Gripstop 1) was set";
CM_ SG_ 376 gripper_calibrated "1 calibrated";
CM_ SG_ 377 gripper_position "0 fully open, 255 fully closed";
CM_ SG_ 377 gripper_current "measured current in mA";
CM_ SG_ 377 gripper_activated "1 activated";
CM_ SG_ 377 gripper_action_status "the action bit of the last Send_gripper_data_pack (1 after #Grippos); the driver never clears it, so it stays 1 after the move ends: the object detection tells when the move has ended";
CM_ SG_ 377 gripper_object_detection_raw "bit 5 is the low bit, bit 4 the high bit: 0 moving, 1 object detected while closing, 2 object detected while opening, 3 at the position; raw bit pair, see value labels (wire order differs from numeric status)";
CM_ SG_ 377 gripper_temperature_error "a copy of the thermistor temperature error";
CM_ SG_ 377 gripper_timeout_error "a copy of the CAN watchdog error (Send_Watchdog), not a move timeout";
CM_ SG_ 377 gripper_estop_error "the E-stop bit of Send_gripper_data_pack (or #Gripstop 1) was set";
CM_ SG_ 377 gripper_calibrated "1 calibrated";
CM_ SG_ 388 Position_setpoint "encoder ticks";
CM_ SG_ 388 Speed_feedforward "encoder ticks/s";
CM_ SG_ 388 Current_feedforward "mA";
CM_ SG_ 392 Position_setpoint "encoder ticks";
CM_ SG_ 392 Speed_setpoint "encoder ticks/s";
CM_ SG_ 392 Current_feedforward "mA";
CM_ SG_ 446 Speed "encoder ticks/s; the sign gives the direction";
CM_ SG_ 446 Trigger "0 = trigger when the pin is low, 1 = when it is high, 2 = on any edge";
CM_ SG_ 390 position "encoder ticks";
CM_ SG_ 390 speed "encoder ticks/s";
CM_ SG_ 390 current "Iq in mA";
CM_ SG_ 391 position "encoder ticks";
CM_ SG_ 391 speed "encoder ticks/s";
CM_ SG_ 391 current "Iq in mA";
CM_ SG_ 448 position "encoder ticks";
CM_ SG_ 448 HALL_trigger "1 while the driver waits for the trigger (with a level trigger, also again after the pin left the level), 0 while it holds";
CM_ SG_ 448 additional_pin2 "the raw level of the ADDITIONAL2 pin";
CM_ SG_ 448 hall_index "1 once the trigger has been seen (latched)";
CM_ SG_ 449 position "encoder ticks";
CM_ SG_ 449 HALL_trigger "1 while the driver waits for the trigger (with a level trigger, also again after the pin left the level), 0 while it holds";
CM_ SG_ 449 additional_pin2 "the raw level of the ADDITIONAL2 pin";
CM_ SG_ 449 hall_index "1 once the trigger has been seen (latched)";
CM_ SG_ 424 Speed_limit "encoder ticks/s";
CM_ SG_ 424 Current_limit "mA";
CM_ SG_ 428 Kt "Nm/A";
CM_ SG_ 452 Voltage_limit "mV; 0 = Vbus";
CM_ SG_ 430 temperature "\u00b0C";
CM_ SG_ 431 temperature "\u00b0C";
CM_ SG_ 432 voltage "mV";
CM_ SG_ 433 voltage "mV";
CM_ SG_ 434 HARDWARE_VERSION "PCB revision";
CM_ SG_ 434 BATCH_DATE "production batch";
CM_ SG_ 434 SOFTWARE_VERSION "firmware release, e.g. 108";
CM_ SG_ 434 SERIAL_NUMBER "serial number as held in RAM: 1 after a power-up";
CM_ SG_ 435 HARDWARE_VERSION "PCB revision";
CM_ SG_ 435 BATCH_DATE "production batch";
CM_ SG_ 435 SOFTWARE_VERSION "firmware release, e.g. 108";
CM_ SG_ 435 SERIAL_NUMBER "serial number as held in RAM: 1 after a power-up";
CM_ SG_ 436 error "any error is active";
CM_ SG_ 436 temperature_error "motor over the temperature limit";
CM_ SG_ 436 encoder_error "the encoder reports no magnet (too weak a field)";
CM_ SG_ 436 vbus_error "supply voltage outside the limits";
CM_ SG_ 436 driver_error "reserved; never set by this firmware (STEPFOC does not read a fault output of its driver stage)";
CM_ SG_ 436 velocity_error "speed above 30,000,000 ticks/s, a fixed threshold (not #Vlimit)";
CM_ SG_ 436 current_error "reserved; never set by this firmware";
CM_ SG_ 436 estop_error "Send_ESTOP was received";
CM_ SG_ 436 calibrated "the motor is calibrated";
CM_ SG_ 436 activated "the controller is activated";
CM_ SG_ 436 watchdog_error "the watchdog ran out";
CM_ SG_ 436 wrong_product "from firmware 109: this firmware is on the other product's board (the product lock) and drives nothing";
CM_ SG_ 437 error "any error is active";
CM_ SG_ 437 temperature_error "motor over the temperature limit";
CM_ SG_ 437 encoder_error "the encoder reports no magnet (too weak a field)";
CM_ SG_ 437 vbus_error "supply voltage outside the limits";
CM_ SG_ 437 driver_error "reserved; never set by this firmware (STEPFOC does not read a fault output of its driver stage)";
CM_ SG_ 437 velocity_error "speed above 30,000,000 ticks/s, a fixed threshold (not #Vlimit)";
CM_ SG_ 437 current_error "reserved; never set by this firmware";
CM_ SG_ 437 estop_error "Send_ESTOP was received";
CM_ SG_ 437 calibrated "the motor is calibrated";
CM_ SG_ 437 activated "the controller is activated";
CM_ SG_ 437 watchdog_error "the watchdog ran out";
CM_ SG_ 437 wrong_product "from firmware 109: this firmware is on the other product's board (the product lock) and drives nothing";
CM_ SG_ 438 current "mA";
CM_ SG_ 439 current "mA";
CM_ SG_ 440 position "encoder ticks";
CM_ SG_ 440 speed "encoder ticks/s";
CM_ SG_ 441 position "encoder ticks";
CM_ SG_ 441 speed "encoder ticks/s";
CM_ SG_ 450 Kt "Nm/A";
CM_ SG_ 451 Kt "Nm/A";
CM_ SG_ 462 product "1 STEPFOC, 2 Spectral Micro: the firmware that answers";
CM_ SG_ 462 tool_id "parameter 1: 0 none, 1 SSG-48, 11-33 MSG, 200-254 your own";
CM_ SG_ 462 firmware_version "the release, e.g. 109";
CM_ SG_ 462 hardware_version "PCB revision from the EEPROM";
CM_ SG_ 462 pole_pairs "the motor's pole pairs; 0 if outside 0-255";
CM_ SG_ 462 calibrated "1 calibrated, 0 not";
CM_ SG_ 462 gripper "the driver is set up as a gripper (#Gripper 1)";
CM_ SG_ 462 brake_on_idle "idle brakes (1) or coasts (0)";
CM_ SG_ 462 commutation_reversed "calibration found the coils wired the other way round";
CM_ SG_ 462 settings_block2 "the EEPROM has the bank settings block 2 lives in, so parameters 1-5 can be saved";
CM_ SG_ 462 wrong_product "this firmware is on the other product's board (the product lock) and drives nothing";
CM_ SG_ 462 sense_zero_measured "the current-sense zero was measured at start-up and is plausible";
CM_ SG_ 462 cogging_saved "the anti-cogging in use is the one saved in the EEPROM";
CM_ SG_ 462 switching_zero_in_use "the current-sense zero measured with the bridge switching is in use (parameter 46)";
CM_ SG_ 463 product "1 STEPFOC, 2 Spectral Micro: the firmware that answers";
CM_ SG_ 463 tool_id "parameter 1: 0 none, 1 SSG-48, 11-33 MSG, 200-254 your own";
CM_ SG_ 463 firmware_version "the release, e.g. 109";
CM_ SG_ 463 hardware_version "PCB revision from the EEPROM";
CM_ SG_ 463 pole_pairs "the motor's pole pairs; 0 if outside 0-255";
CM_ SG_ 463 calibrated "1 calibrated, 0 not";
CM_ SG_ 463 gripper "the driver is set up as a gripper (#Gripper 1)";
CM_ SG_ 463 brake_on_idle "idle brakes (1) or coasts (0)";
CM_ SG_ 463 commutation_reversed "calibration found the coils wired the other way round";
CM_ SG_ 463 settings_block2 "the EEPROM has the bank settings block 2 lives in, so parameters 1-5 can be saved";
CM_ SG_ 463 wrong_product "this firmware is on the other product's board (the product lock) and drives nothing";
CM_ SG_ 463 sense_zero_measured "the current-sense zero was measured at start-up and is plausible";
CM_ SG_ 463 cogging_saved "the anti-cogging in use is the one saved in the EEPROM";
CM_ SG_ 463 switching_zero_in_use "the current-sense zero measured with the bridge switching is in use (parameter 46)";
CM_ SG_ 464 temperature "\u00b0C (meaningful with the thermistor enabled)";
CM_ SG_ 464 voltage "supply voltage in mV";
CM_ SG_ 464 errors_1 "the error flags, as byte 0 of Send_Respond_State_of_Errors";
CM_ SG_ 464 errors_2 "calibrated, activated, watchdog, wrong product, as byte 1 of Send_Respond_State_of_Errors";
CM_ SG_ 464 current "Iq in mA";
CM_ SG_ 465 temperature "\u00b0C (meaningful with the thermistor enabled)";
CM_ SG_ 465 voltage "supply voltage in mV";
CM_ SG_ 465 errors_1 "the error flags, as byte 0 of Send_Respond_State_of_Errors";
CM_ SG_ 465 errors_2 "calibrated, activated, watchdog, wrong product, as byte 1 of Send_Respond_State_of_Errors";
CM_ SG_ 465 current "Iq in mA";
CM_ SG_ 406 ID "0 to 13; 14 and 15 are accepted but reserved by the bootloader";
CM_ SG_ 414 Time "ms; 0 = off";
CM_ SG_ 414 Action "0 legacy (brake or coast as idle does), 1 hold the position, 2 brake, 3 coast, 4 descend at the fallback current and speed; other values act as 0";
CM_ SG_ 444 Interval "ms; 0 = off";
CM_ SG_ 454 Mask "bit 0 = write the idle behaviour";
CM_ SG_ 454 Value "bit 0: 1 brake, 0 coast";
CM_ SG_ 456 Parameter "the parameter number, 1-87";
CM_ SG_ 456 Value "the new value, in the parameter's unit; for the gains, limits and Kt (8-16, 20) a float's bit pattern";
CM_ SG_ 458 Parameter "the parameter number";
CM_ SG_ 460 parameter "the parameter number";
CM_ SG_ 460 value "the value in force; a float's bits for 8-16 and 20";
CM_ SG_ 461 parameter "the parameter number";
CM_ SG_ 461 value "the value in force; a float's bits for 8-16 and 20";
CM_ SG_ 466 Kind "0 capture (up to 1024 samples: parameter 32 says how many), 1 histogram (256 bins), 2 anti-cogging harmonics (8 slots), 3 anti-cogging table (256 values), 4 encoder table (128 values)";
CM_ SG_ 466 First "the first index";
CM_ SG_ 466 Count "how many entries; 0 cancels a read-out";
CM_ SG_ 468 header "kind \u00d7 8192 + index";
CM_ SG_ 468 word_a "capture: channel A; histogram: the count (unsigned); harmonics: the harmonic number (0 = slot unused); tables: entry index";
CM_ SG_ 468 word_b "capture: channel B; histogram: the sum's upper 16 bits; harmonics: a, the cosine term in mA; tables: entry index + 1";
CM_ SG_ 468 word_c "capture: channel C; histogram: the sum's lower 16 bits; harmonics: b, the sine term in mA; tables: entry index + 2 (0 past the end)";
CM_ SG_ 469 header "kind \u00d7 8192 + index";
CM_ SG_ 469 word_a "capture: channel A; histogram: the count (unsigned); harmonics: the harmonic number (0 = slot unused); tables: entry index";
CM_ SG_ 469 word_b "capture: channel B; histogram: the sum's upper 16 bits; harmonics: a, the cosine term in mA; tables: entry index + 1";
CM_ SG_ 469 word_c "capture: channel C; histogram: the sum's lower 16 bits; harmonics: b, the sine term in mA; tables: entry index + 2 (0 past the end)";
CM_ SG_ 470 Header "kind \u00d7 8192 + index; kind 2 or 3";
CM_ SG_ 470 Word_A "kind 2: the harmonic (1-32, 0 = unused); kind 3: value at index";
CM_ SG_ 470 Word_B "kind 2: a in mA; kind 3: value at index + 1";
CM_ SG_ 470 Word_C "kind 2: b in mA; kind 3: value at index + 2";
CM_ SG_ 472 Operation "0 stop everything (tones, queue, samples); 1 a tone now; 2 add an event to the queue; 3 play the queue; 4 play the samples; 5 samples off, buffer cleared; 6 clear the queue (tones that sound keep sounding)";
CM_ SG_ 472 Channel "the tone channel, 0-3 (operations 1 and 2)";
CM_ SG_ 472 A "1, 2: the pitch in Hz (2: 0 silences the channel); 4: the sample rate in Hz, at most the loop rate";
CM_ SG_ 472 B "1, 2: the loudness in mA; 4: the voltage of a full-scale sample in mV";
CM_ SG_ 472 C "1: the duration in ms, 0 = until stopped; 2: the wait in ms before the next event, 0 = the next one starts with it";
CM_ SG_ 474 Sample_1 "the next sample";
CM_ SG_ 506 Position "0 fully open, 255 fully closed";
CM_ SG_ 506 Speed "0 slowest, 255 fastest";
CM_ SG_ 506 Current "current limit of the move in mA; from firmware 109 the move uses its magnitude, at most the driver's 2800 mA; see the gripper manual for the safe range";
CM_ SG_ 506 Activate "1 activate the gripper, 0 deactivate";
CM_ SG_ 506 Action "1 go to the position, 0 idle";
CM_ SG_ 506 E_stop "1 raises the gripper E-stop error, again on every control cycle until a frame with this bit 0 arrives; then Send_Clear_Error";
CM_ SG_ 506 Release_direction "read by the firmware but not used";
CM_ SG_ 504 gripper_position "0 fully open, 255 fully closed";
CM_ SG_ 504 gripper_current "measured current in mA";
CM_ SG_ 504 gripper_activated "1 activated";
CM_ SG_ 504 gripper_action_status "the action bit of the last Send_gripper_data_pack (1 after #Grippos); the driver never clears it, so it stays 1 after the move ends: the object detection tells when the move has ended";
CM_ SG_ 504 gripper_object_detection_raw "bit 5 is the low bit, bit 4 the high bit: 0 moving, 1 object detected while closing, 2 object detected while opening, 3 at the position; raw bit pair, see value labels (wire order differs from numeric status)";
CM_ SG_ 504 gripper_temperature_error "a copy of the thermistor temperature error";
CM_ SG_ 504 gripper_timeout_error "a copy of the CAN watchdog error (Send_Watchdog), not a move timeout";
CM_ SG_ 504 gripper_estop_error "the E-stop bit of Send_gripper_data_pack (or #Gripstop 1) was set";
CM_ SG_ 504 gripper_calibrated "1 calibrated";
CM_ SG_ 505 gripper_position "0 fully open, 255 fully closed";
CM_ SG_ 505 gripper_current "measured current in mA";
CM_ SG_ 505 gripper_activated "1 activated";
CM_ SG_ 505 gripper_action_status "the action bit of the last Send_gripper_data_pack (1 after #Grippos); the driver never clears it, so it stays 1 after the move ends: the object detection tells when the move has ended";
CM_ SG_ 505 gripper_object_detection_raw "bit 5 is the low bit, bit 4 the high bit: 0 moving, 1 object detected while closing, 2 object detected while opening, 3 at the position; raw bit pair, see value labels (wire order differs from numeric status)";
CM_ SG_ 505 gripper_temperature_error "a copy of the thermistor temperature error";
CM_ SG_ 505 gripper_timeout_error "a copy of the CAN watchdog error (Send_Watchdog), not a move timeout";
CM_ SG_ 505 gripper_estop_error "the E-stop bit of Send_gripper_data_pack (or #Gripstop 1) was set";
CM_ SG_ 505 gripper_calibrated "1 calibrated";
CM_ SG_ 516 Position_setpoint "encoder ticks";
CM_ SG_ 516 Speed_feedforward "encoder ticks/s";
CM_ SG_ 516 Current_feedforward "mA";
CM_ SG_ 520 Position_setpoint "encoder ticks";
CM_ SG_ 520 Speed_setpoint "encoder ticks/s";
CM_ SG_ 520 Current_feedforward "mA";
CM_ SG_ 574 Speed "encoder ticks/s; the sign gives the direction";
CM_ SG_ 574 Trigger "0 = trigger when the pin is low, 1 = when it is high, 2 = on any edge";
CM_ SG_ 518 position "encoder ticks";
CM_ SG_ 518 speed "encoder ticks/s";
CM_ SG_ 518 current "Iq in mA";
CM_ SG_ 519 position "encoder ticks";
CM_ SG_ 519 speed "encoder ticks/s";
CM_ SG_ 519 current "Iq in mA";
CM_ SG_ 576 position "encoder ticks";
CM_ SG_ 576 HALL_trigger "1 while the driver waits for the trigger (with a level trigger, also again after the pin left the level), 0 while it holds";
CM_ SG_ 576 additional_pin2 "the raw level of the ADDITIONAL2 pin";
CM_ SG_ 576 hall_index "1 once the trigger has been seen (latched)";
CM_ SG_ 577 position "encoder ticks";
CM_ SG_ 577 HALL_trigger "1 while the driver waits for the trigger (with a level trigger, also again after the pin left the level), 0 while it holds";
CM_ SG_ 577 additional_pin2 "the raw level of the ADDITIONAL2 pin";
CM_ SG_ 577 hall_index "1 once the trigger has been seen (latched)";
CM_ SG_ 552 Speed_limit "encoder ticks/s";
CM_ SG_ 552 Current_limit "mA";
CM_ SG_ 556 Kt "Nm/A";
CM_ SG_ 580 Voltage_limit "mV; 0 = Vbus";
CM_ SG_ 558 temperature "\u00b0C";
CM_ SG_ 559 temperature "\u00b0C";
CM_ SG_ 560 voltage "mV";
CM_ SG_ 561 voltage "mV";
CM_ SG_ 562 HARDWARE_VERSION "PCB revision";
CM_ SG_ 562 BATCH_DATE "production batch";
CM_ SG_ 562 SOFTWARE_VERSION "firmware release, e.g. 108";
CM_ SG_ 562 SERIAL_NUMBER "serial number as held in RAM: 1 after a power-up";
CM_ SG_ 563 HARDWARE_VERSION "PCB revision";
CM_ SG_ 563 BATCH_DATE "production batch";
CM_ SG_ 563 SOFTWARE_VERSION "firmware release, e.g. 108";
CM_ SG_ 563 SERIAL_NUMBER "serial number as held in RAM: 1 after a power-up";
CM_ SG_ 564 error "any error is active";
CM_ SG_ 564 temperature_error "motor over the temperature limit";
CM_ SG_ 564 encoder_error "the encoder reports no magnet (too weak a field)";
CM_ SG_ 564 vbus_error "supply voltage outside the limits";
CM_ SG_ 564 driver_error "reserved; never set by this firmware (STEPFOC does not read a fault output of its driver stage)";
CM_ SG_ 564 velocity_error "speed above 30,000,000 ticks/s, a fixed threshold (not #Vlimit)";
CM_ SG_ 564 current_error "reserved; never set by this firmware";
CM_ SG_ 564 estop_error "Send_ESTOP was received";
CM_ SG_ 564 calibrated "the motor is calibrated";
CM_ SG_ 564 activated "the controller is activated";
CM_ SG_ 564 watchdog_error "the watchdog ran out";
CM_ SG_ 564 wrong_product "from firmware 109: this firmware is on the other product's board (the product lock) and drives nothing";
CM_ SG_ 565 error "any error is active";
CM_ SG_ 565 temperature_error "motor over the temperature limit";
CM_ SG_ 565 encoder_error "the encoder reports no magnet (too weak a field)";
CM_ SG_ 565 vbus_error "supply voltage outside the limits";
CM_ SG_ 565 driver_error "reserved; never set by this firmware (STEPFOC does not read a fault output of its driver stage)";
CM_ SG_ 565 velocity_error "speed above 30,000,000 ticks/s, a fixed threshold (not #Vlimit)";
CM_ SG_ 565 current_error "reserved; never set by this firmware";
CM_ SG_ 565 estop_error "Send_ESTOP was received";
CM_ SG_ 565 calibrated "the motor is calibrated";
CM_ SG_ 565 activated "the controller is activated";
CM_ SG_ 565 watchdog_error "the watchdog ran out";
CM_ SG_ 565 wrong_product "from firmware 109: this firmware is on the other product's board (the product lock) and drives nothing";
CM_ SG_ 566 current "mA";
CM_ SG_ 567 current "mA";
CM_ SG_ 568 position "encoder ticks";
CM_ SG_ 568 speed "encoder ticks/s";
CM_ SG_ 569 position "encoder ticks";
CM_ SG_ 569 speed "encoder ticks/s";
CM_ SG_ 578 Kt "Nm/A";
CM_ SG_ 579 Kt "Nm/A";
CM_ SG_ 590 product "1 STEPFOC, 2 Spectral Micro: the firmware that answers";
CM_ SG_ 590 tool_id "parameter 1: 0 none, 1 SSG-48, 11-33 MSG, 200-254 your own";
CM_ SG_ 590 firmware_version "the release, e.g. 109";
CM_ SG_ 590 hardware_version "PCB revision from the EEPROM";
CM_ SG_ 590 pole_pairs "the motor's pole pairs; 0 if outside 0-255";
CM_ SG_ 590 calibrated "1 calibrated, 0 not";
CM_ SG_ 590 gripper "the driver is set up as a gripper (#Gripper 1)";
CM_ SG_ 590 brake_on_idle "idle brakes (1) or coasts (0)";
CM_ SG_ 590 commutation_reversed "calibration found the coils wired the other way round";
CM_ SG_ 590 settings_block2 "the EEPROM has the bank settings block 2 lives in, so parameters 1-5 can be saved";
CM_ SG_ 590 wrong_product "this firmware is on the other product's board (the product lock) and drives nothing";
CM_ SG_ 590 sense_zero_measured "the current-sense zero was measured at start-up and is plausible";
CM_ SG_ 590 cogging_saved "the anti-cogging in use is the one saved in the EEPROM";
CM_ SG_ 590 switching_zero_in_use "the current-sense zero measured with the bridge switching is in use (parameter 46)";
CM_ SG_ 591 product "1 STEPFOC, 2 Spectral Micro: the firmware that answers";
CM_ SG_ 591 tool_id "parameter 1: 0 none, 1 SSG-48, 11-33 MSG, 200-254 your own";
CM_ SG_ 591 firmware_version "the release, e.g. 109";
CM_ SG_ 591 hardware_version "PCB revision from the EEPROM";
CM_ SG_ 591 pole_pairs "the motor's pole pairs; 0 if outside 0-255";
CM_ SG_ 591 calibrated "1 calibrated, 0 not";
CM_ SG_ 591 gripper "the driver is set up as a gripper (#Gripper 1)";
CM_ SG_ 591 brake_on_idle "idle brakes (1) or coasts (0)";
CM_ SG_ 591 commutation_reversed "calibration found the coils wired the other way round";
CM_ SG_ 591 settings_block2 "the EEPROM has the bank settings block 2 lives in, so parameters 1-5 can be saved";
CM_ SG_ 591 wrong_product "this firmware is on the other product's board (the product lock) and drives nothing";
CM_ SG_ 591 sense_zero_measured "the current-sense zero was measured at start-up and is plausible";
CM_ SG_ 591 cogging_saved "the anti-cogging in use is the one saved in the EEPROM";
CM_ SG_ 591 switching_zero_in_use "the current-sense zero measured with the bridge switching is in use (parameter 46)";
CM_ SG_ 592 temperature "\u00b0C (meaningful with the thermistor enabled)";
CM_ SG_ 592 voltage "supply voltage in mV";
CM_ SG_ 592 errors_1 "the error flags, as byte 0 of Send_Respond_State_of_Errors";
CM_ SG_ 592 errors_2 "calibrated, activated, watchdog, wrong product, as byte 1 of Send_Respond_State_of_Errors";
CM_ SG_ 592 current "Iq in mA";
CM_ SG_ 593 temperature "\u00b0C (meaningful with the thermistor enabled)";
CM_ SG_ 593 voltage "supply voltage in mV";
CM_ SG_ 593 errors_1 "the error flags, as byte 0 of Send_Respond_State_of_Errors";
CM_ SG_ 593 errors_2 "calibrated, activated, watchdog, wrong product, as byte 1 of Send_Respond_State_of_Errors";
CM_ SG_ 593 current "Iq in mA";
CM_ SG_ 534 ID "0 to 13; 14 and 15 are accepted but reserved by the bootloader";
CM_ SG_ 542 Time "ms; 0 = off";
CM_ SG_ 542 Action "0 legacy (brake or coast as idle does), 1 hold the position, 2 brake, 3 coast, 4 descend at the fallback current and speed; other values act as 0";
CM_ SG_ 572 Interval "ms; 0 = off";
CM_ SG_ 582 Mask "bit 0 = write the idle behaviour";
CM_ SG_ 582 Value "bit 0: 1 brake, 0 coast";
CM_ SG_ 584 Parameter "the parameter number, 1-87";
CM_ SG_ 584 Value "the new value, in the parameter's unit; for the gains, limits and Kt (8-16, 20) a float's bit pattern";
CM_ SG_ 586 Parameter "the parameter number";
CM_ SG_ 588 parameter "the parameter number";
CM_ SG_ 588 value "the value in force; a float's bits for 8-16 and 20";
CM_ SG_ 589 parameter "the parameter number";
CM_ SG_ 589 value "the value in force; a float's bits for 8-16 and 20";
CM_ SG_ 594 Kind "0 capture (up to 1024 samples: parameter 32 says how many), 1 histogram (256 bins), 2 anti-cogging harmonics (8 slots), 3 anti-cogging table (256 values), 4 encoder table (128 values)";
CM_ SG_ 594 First "the first index";
CM_ SG_ 594 Count "how many entries; 0 cancels a read-out";
CM_ SG_ 596 header "kind \u00d7 8192 + index";
CM_ SG_ 596 word_a "capture: channel A; histogram: the count (unsigned); harmonics: the harmonic number (0 = slot unused); tables: entry index";
CM_ SG_ 596 word_b "capture: channel B; histogram: the sum's upper 16 bits; harmonics: a, the cosine term in mA; tables: entry index + 1";
CM_ SG_ 596 word_c "capture: channel C; histogram: the sum's lower 16 bits; harmonics: b, the sine term in mA; tables: entry index + 2 (0 past the end)";
CM_ SG_ 597 header "kind \u00d7 8192 + index";
CM_ SG_ 597 word_a "capture: channel A; histogram: the count (unsigned); harmonics: the harmonic number (0 = slot unused); tables: entry index";
CM_ SG_ 597 word_b "capture: channel B; histogram: the sum's upper 16 bits; harmonics: a, the cosine term in mA; tables: entry index + 1";
CM_ SG_ 597 word_c "capture: channel C; histogram: the sum's lower 16 bits; harmonics: b, the sine term in mA; tables: entry index + 2 (0 past the end)";
CM_ SG_ 598 Header "kind \u00d7 8192 + index; kind 2 or 3";
CM_ SG_ 598 Word_A "kind 2: the harmonic (1-32, 0 = unused); kind 3: value at index";
CM_ SG_ 598 Word_B "kind 2: a in mA; kind 3: value at index + 1";
CM_ SG_ 598 Word_C "kind 2: b in mA; kind 3: value at index + 2";
CM_ SG_ 600 Operation "0 stop everything (tones, queue, samples); 1 a tone now; 2 add an event to the queue; 3 play the queue; 4 play the samples; 5 samples off, buffer cleared; 6 clear the queue (tones that sound keep sounding)";
CM_ SG_ 600 Channel "the tone channel, 0-3 (operations 1 and 2)";
CM_ SG_ 600 A "1, 2: the pitch in Hz (2: 0 silences the channel); 4: the sample rate in Hz, at most the loop rate";
CM_ SG_ 600 B "1, 2: the loudness in mA; 4: the voltage of a full-scale sample in mV";
CM_ SG_ 600 C "1: the duration in ms, 0 = until stopped; 2: the wait in ms before the next event, 0 = the next one starts with it";
CM_ SG_ 602 Sample_1 "the next sample";
CM_ SG_ 634 Position "0 fully open, 255 fully closed";
CM_ SG_ 634 Speed "0 slowest, 255 fastest";
CM_ SG_ 634 Current "current limit of the move in mA; from firmware 109 the move uses its magnitude, at most the driver's 2800 mA; see the gripper manual for the safe range";
CM_ SG_ 634 Activate "1 activate the gripper, 0 deactivate";
CM_ SG_ 634 Action "1 go to the position, 0 idle";
CM_ SG_ 634 E_stop "1 raises the gripper E-stop error, again on every control cycle until a frame with this bit 0 arrives; then Send_Clear_Error";
CM_ SG_ 634 Release_direction "read by the firmware but not used";
CM_ SG_ 632 gripper_position "0 fully open, 255 fully closed";
CM_ SG_ 632 gripper_current "measured current in mA";
CM_ SG_ 632 gripper_activated "1 activated";
CM_ SG_ 632 gripper_action_status "the action bit of the last Send_gripper_data_pack (1 after #Grippos); the driver never clears it, so it stays 1 after the move ends: the object detection tells when the move has ended";
CM_ SG_ 632 gripper_object_detection_raw "bit 5 is the low bit, bit 4 the high bit: 0 moving, 1 object detected while closing, 2 object detected while opening, 3 at the position; raw bit pair, see value labels (wire order differs from numeric status)";
CM_ SG_ 632 gripper_temperature_error "a copy of the thermistor temperature error";
CM_ SG_ 632 gripper_timeout_error "a copy of the CAN watchdog error (Send_Watchdog), not a move timeout";
CM_ SG_ 632 gripper_estop_error "the E-stop bit of Send_gripper_data_pack (or #Gripstop 1) was set";
CM_ SG_ 632 gripper_calibrated "1 calibrated";
CM_ SG_ 633 gripper_position "0 fully open, 255 fully closed";
CM_ SG_ 633 gripper_current "measured current in mA";
CM_ SG_ 633 gripper_activated "1 activated";
CM_ SG_ 633 gripper_action_status "the action bit of the last Send_gripper_data_pack (1 after #Grippos); the driver never clears it, so it stays 1 after the move ends: the object detection tells when the move has ended";
CM_ SG_ 633 gripper_object_detection_raw "bit 5 is the low bit, bit 4 the high bit: 0 moving, 1 object detected while closing, 2 object detected while opening, 3 at the position; raw bit pair, see value labels (wire order differs from numeric status)";
CM_ SG_ 633 gripper_temperature_error "a copy of the thermistor temperature error";
CM_ SG_ 633 gripper_timeout_error "a copy of the CAN watchdog error (Send_Watchdog), not a move timeout";
CM_ SG_ 633 gripper_estop_error "the E-stop bit of Send_gripper_data_pack (or #Gripstop 1) was set";
CM_ SG_ 633 gripper_calibrated "1 calibrated";
CM_ SG_ 644 Position_setpoint "encoder ticks";
CM_ SG_ 644 Speed_feedforward "encoder ticks/s";
CM_ SG_ 644 Current_feedforward "mA";
CM_ SG_ 648 Position_setpoint "encoder ticks";
CM_ SG_ 648 Speed_setpoint "encoder ticks/s";
CM_ SG_ 648 Current_feedforward "mA";
CM_ SG_ 702 Speed "encoder ticks/s; the sign gives the direction";
CM_ SG_ 702 Trigger "0 = trigger when the pin is low, 1 = when it is high, 2 = on any edge";
CM_ SG_ 646 position "encoder ticks";
CM_ SG_ 646 speed "encoder ticks/s";
CM_ SG_ 646 current "Iq in mA";
CM_ SG_ 647 position "encoder ticks";
CM_ SG_ 647 speed "encoder ticks/s";
CM_ SG_ 647 current "Iq in mA";
CM_ SG_ 704 position "encoder ticks";
CM_ SG_ 704 HALL_trigger "1 while the driver waits for the trigger (with a level trigger, also again after the pin left the level), 0 while it holds";
CM_ SG_ 704 additional_pin2 "the raw level of the ADDITIONAL2 pin";
CM_ SG_ 704 hall_index "1 once the trigger has been seen (latched)";
CM_ SG_ 705 position "encoder ticks";
CM_ SG_ 705 HALL_trigger "1 while the driver waits for the trigger (with a level trigger, also again after the pin left the level), 0 while it holds";
CM_ SG_ 705 additional_pin2 "the raw level of the ADDITIONAL2 pin";
CM_ SG_ 705 hall_index "1 once the trigger has been seen (latched)";
CM_ SG_ 680 Speed_limit "encoder ticks/s";
CM_ SG_ 680 Current_limit "mA";
CM_ SG_ 684 Kt "Nm/A";
CM_ SG_ 708 Voltage_limit "mV; 0 = Vbus";
CM_ SG_ 686 temperature "\u00b0C";
CM_ SG_ 687 temperature "\u00b0C";
CM_ SG_ 688 voltage "mV";
CM_ SG_ 689 voltage "mV";
CM_ SG_ 690 HARDWARE_VERSION "PCB revision";
CM_ SG_ 690 BATCH_DATE "production batch";
CM_ SG_ 690 SOFTWARE_VERSION "firmware release, e.g. 108";
CM_ SG_ 690 SERIAL_NUMBER "serial number as held in RAM: 1 after a power-up";
CM_ SG_ 691 HARDWARE_VERSION "PCB revision";
CM_ SG_ 691 BATCH_DATE "production batch";
CM_ SG_ 691 SOFTWARE_VERSION "firmware release, e.g. 108";
CM_ SG_ 691 SERIAL_NUMBER "serial number as held in RAM: 1 after a power-up";
CM_ SG_ 692 error "any error is active";
CM_ SG_ 692 temperature_error "motor over the temperature limit";
CM_ SG_ 692 encoder_error "the encoder reports no magnet (too weak a field)";
CM_ SG_ 692 vbus_error "supply voltage outside the limits";
CM_ SG_ 692 driver_error "reserved; never set by this firmware (STEPFOC does not read a fault output of its driver stage)";
CM_ SG_ 692 velocity_error "speed above 30,000,000 ticks/s, a fixed threshold (not #Vlimit)";
CM_ SG_ 692 current_error "reserved; never set by this firmware";
CM_ SG_ 692 estop_error "Send_ESTOP was received";
CM_ SG_ 692 calibrated "the motor is calibrated";
CM_ SG_ 692 activated "the controller is activated";
CM_ SG_ 692 watchdog_error "the watchdog ran out";
CM_ SG_ 692 wrong_product "from firmware 109: this firmware is on the other product's board (the product lock) and drives nothing";
CM_ SG_ 693 error "any error is active";
CM_ SG_ 693 temperature_error "motor over the temperature limit";
CM_ SG_ 693 encoder_error "the encoder reports no magnet (too weak a field)";
CM_ SG_ 693 vbus_error "supply voltage outside the limits";
CM_ SG_ 693 driver_error "reserved; never set by this firmware (STEPFOC does not read a fault output of its driver stage)";
CM_ SG_ 693 velocity_error "speed above 30,000,000 ticks/s, a fixed threshold (not #Vlimit)";
CM_ SG_ 693 current_error "reserved; never set by this firmware";
CM_ SG_ 693 estop_error "Send_ESTOP was received";
CM_ SG_ 693 calibrated "the motor is calibrated";
CM_ SG_ 693 activated "the controller is activated";
CM_ SG_ 693 watchdog_error "the watchdog ran out";
CM_ SG_ 693 wrong_product "from firmware 109: this firmware is on the other product's board (the product lock) and drives nothing";
CM_ SG_ 694 current "mA";
CM_ SG_ 695 current "mA";
CM_ SG_ 696 position "encoder ticks";
CM_ SG_ 696 speed "encoder ticks/s";
CM_ SG_ 697 position "encoder ticks";
CM_ SG_ 697 speed "encoder ticks/s";
CM_ SG_ 706 Kt "Nm/A";
CM_ SG_ 707 Kt "Nm/A";
CM_ SG_ 718 product "1 STEPFOC, 2 Spectral Micro: the firmware that answers";
CM_ SG_ 718 tool_id "parameter 1: 0 none, 1 SSG-48, 11-33 MSG, 200-254 your own";
CM_ SG_ 718 firmware_version "the release, e.g. 109";
CM_ SG_ 718 hardware_version "PCB revision from the EEPROM";
CM_ SG_ 718 pole_pairs "the motor's pole pairs; 0 if outside 0-255";
CM_ SG_ 718 calibrated "1 calibrated, 0 not";
CM_ SG_ 718 gripper "the driver is set up as a gripper (#Gripper 1)";
CM_ SG_ 718 brake_on_idle "idle brakes (1) or coasts (0)";
CM_ SG_ 718 commutation_reversed "calibration found the coils wired the other way round";
CM_ SG_ 718 settings_block2 "the EEPROM has the bank settings block 2 lives in, so parameters 1-5 can be saved";
CM_ SG_ 718 wrong_product "this firmware is on the other product's board (the product lock) and drives nothing";
CM_ SG_ 718 sense_zero_measured "the current-sense zero was measured at start-up and is plausible";
CM_ SG_ 718 cogging_saved "the anti-cogging in use is the one saved in the EEPROM";
CM_ SG_ 718 switching_zero_in_use "the current-sense zero measured with the bridge switching is in use (parameter 46)";
CM_ SG_ 719 product "1 STEPFOC, 2 Spectral Micro: the firmware that answers";
CM_ SG_ 719 tool_id "parameter 1: 0 none, 1 SSG-48, 11-33 MSG, 200-254 your own";
CM_ SG_ 719 firmware_version "the release, e.g. 109";
CM_ SG_ 719 hardware_version "PCB revision from the EEPROM";
CM_ SG_ 719 pole_pairs "the motor's pole pairs; 0 if outside 0-255";
CM_ SG_ 719 calibrated "1 calibrated, 0 not";
CM_ SG_ 719 gripper "the driver is set up as a gripper (#Gripper 1)";
CM_ SG_ 719 brake_on_idle "idle brakes (1) or coasts (0)";
CM_ SG_ 719 commutation_reversed "calibration found the coils wired the other way round";
CM_ SG_ 719 settings_block2 "the EEPROM has the bank settings block 2 lives in, so parameters 1-5 can be saved";
CM_ SG_ 719 wrong_product "this firmware is on the other product's board (the product lock) and drives nothing";
CM_ SG_ 719 sense_zero_measured "the current-sense zero was measured at start-up and is plausible";
CM_ SG_ 719 cogging_saved "the anti-cogging in use is the one saved in the EEPROM";
CM_ SG_ 719 switching_zero_in_use "the current-sense zero measured with the bridge switching is in use (parameter 46)";
CM_ SG_ 720 temperature "\u00b0C (meaningful with the thermistor enabled)";
CM_ SG_ 720 voltage "supply voltage in mV";
CM_ SG_ 720 errors_1 "the error flags, as byte 0 of Send_Respond_State_of_Errors";
CM_ SG_ 720 errors_2 "calibrated, activated, watchdog, wrong product, as byte 1 of Send_Respond_State_of_Errors";
CM_ SG_ 720 current "Iq in mA";
CM_ SG_ 721 temperature "\u00b0C (meaningful with the thermistor enabled)";
CM_ SG_ 721 voltage "supply voltage in mV";
CM_ SG_ 721 errors_1 "the error flags, as byte 0 of Send_Respond_State_of_Errors";
CM_ SG_ 721 errors_2 "calibrated, activated, watchdog, wrong product, as byte 1 of Send_Respond_State_of_Errors";
CM_ SG_ 721 current "Iq in mA";
CM_ SG_ 662 ID "0 to 13; 14 and 15 are accepted but reserved by the bootloader";
CM_ SG_ 670 Time "ms; 0 = off";
CM_ SG_ 670 Action "0 legacy (brake or coast as idle does), 1 hold the position, 2 brake, 3 coast, 4 descend at the fallback current and speed; other values act as 0";
CM_ SG_ 700 Interval "ms; 0 = off";
CM_ SG_ 710 Mask "bit 0 = write the idle behaviour";
CM_ SG_ 710 Value "bit 0: 1 brake, 0 coast";
CM_ SG_ 712 Parameter "the parameter number, 1-87";
CM_ SG_ 712 Value "the new value, in the parameter's unit; for the gains, limits and Kt (8-16, 20) a float's bit pattern";
CM_ SG_ 714 Parameter "the parameter number";
CM_ SG_ 716 parameter "the parameter number";
CM_ SG_ 716 value "the value in force; a float's bits for 8-16 and 20";
CM_ SG_ 717 parameter "the parameter number";
CM_ SG_ 717 value "the value in force; a float's bits for 8-16 and 20";
CM_ SG_ 722 Kind "0 capture (up to 1024 samples: parameter 32 says how many), 1 histogram (256 bins), 2 anti-cogging harmonics (8 slots), 3 anti-cogging table (256 values), 4 encoder table (128 values)";
CM_ SG_ 722 First "the first index";
CM_ SG_ 722 Count "how many entries; 0 cancels a read-out";
CM_ SG_ 724 header "kind \u00d7 8192 + index";
CM_ SG_ 724 word_a "capture: channel A; histogram: the count (unsigned); harmonics: the harmonic number (0 = slot unused); tables: entry index";
CM_ SG_ 724 word_b "capture: channel B; histogram: the sum's upper 16 bits; harmonics: a, the cosine term in mA; tables: entry index + 1";
CM_ SG_ 724 word_c "capture: channel C; histogram: the sum's lower 16 bits; harmonics: b, the sine term in mA; tables: entry index + 2 (0 past the end)";
CM_ SG_ 725 header "kind \u00d7 8192 + index";
CM_ SG_ 725 word_a "capture: channel A; histogram: the count (unsigned); harmonics: the harmonic number (0 = slot unused); tables: entry index";
CM_ SG_ 725 word_b "capture: channel B; histogram: the sum's upper 16 bits; harmonics: a, the cosine term in mA; tables: entry index + 1";
CM_ SG_ 725 word_c "capture: channel C; histogram: the sum's lower 16 bits; harmonics: b, the sine term in mA; tables: entry index + 2 (0 past the end)";
CM_ SG_ 726 Header "kind \u00d7 8192 + index; kind 2 or 3";
CM_ SG_ 726 Word_A "kind 2: the harmonic (1-32, 0 = unused); kind 3: value at index";
CM_ SG_ 726 Word_B "kind 2: a in mA; kind 3: value at index + 1";
CM_ SG_ 726 Word_C "kind 2: b in mA; kind 3: value at index + 2";
CM_ SG_ 728 Operation "0 stop everything (tones, queue, samples); 1 a tone now; 2 add an event to the queue; 3 play the queue; 4 play the samples; 5 samples off, buffer cleared; 6 clear the queue (tones that sound keep sounding)";
CM_ SG_ 728 Channel "the tone channel, 0-3 (operations 1 and 2)";
CM_ SG_ 728 A "1, 2: the pitch in Hz (2: 0 silences the channel); 4: the sample rate in Hz, at most the loop rate";
CM_ SG_ 728 B "1, 2: the loudness in mA; 4: the voltage of a full-scale sample in mV";
CM_ SG_ 728 C "1: the duration in ms, 0 = until stopped; 2: the wait in ms before the next event, 0 = the next one starts with it";
CM_ SG_ 730 Sample_1 "the next sample";
CM_ SG_ 762 Position "0 fully open, 255 fully closed";
CM_ SG_ 762 Speed "0 slowest, 255 fastest";
CM_ SG_ 762 Current "current limit of the move in mA; from firmware 109 the move uses its magnitude, at most the driver's 2800 mA; see the gripper manual for the safe range";
CM_ SG_ 762 Activate "1 activate the gripper, 0 deactivate";
CM_ SG_ 762 Action "1 go to the position, 0 idle";
CM_ SG_ 762 E_stop "1 raises the gripper E-stop error, again on every control cycle until a frame with this bit 0 arrives; then Send_Clear_Error";
CM_ SG_ 762 Release_direction "read by the firmware but not used";
CM_ SG_ 760 gripper_position "0 fully open, 255 fully closed";
CM_ SG_ 760 gripper_current "measured current in mA";
CM_ SG_ 760 gripper_activated "1 activated";
CM_ SG_ 760 gripper_action_status "the action bit of the last Send_gripper_data_pack (1 after #Grippos); the driver never clears it, so it stays 1 after the move ends: the object detection tells when the move has ended";
CM_ SG_ 760 gripper_object_detection_raw "bit 5 is the low bit, bit 4 the high bit: 0 moving, 1 object detected while closing, 2 object detected while opening, 3 at the position; raw bit pair, see value labels (wire order differs from numeric status)";
CM_ SG_ 760 gripper_temperature_error "a copy of the thermistor temperature error";
CM_ SG_ 760 gripper_timeout_error "a copy of the CAN watchdog error (Send_Watchdog), not a move timeout";
CM_ SG_ 760 gripper_estop_error "the E-stop bit of Send_gripper_data_pack (or #Gripstop 1) was set";
CM_ SG_ 760 gripper_calibrated "1 calibrated";
CM_ SG_ 761 gripper_position "0 fully open, 255 fully closed";
CM_ SG_ 761 gripper_current "measured current in mA";
CM_ SG_ 761 gripper_activated "1 activated";
CM_ SG_ 761 gripper_action_status "the action bit of the last Send_gripper_data_pack (1 after #Grippos); the driver never clears it, so it stays 1 after the move ends: the object detection tells when the move has ended";
CM_ SG_ 761 gripper_object_detection_raw "bit 5 is the low bit, bit 4 the high bit: 0 moving, 1 object detected while closing, 2 object detected while opening, 3 at the position; raw bit pair, see value labels (wire order differs from numeric status)";
CM_ SG_ 761 gripper_temperature_error "a copy of the thermistor temperature error";
CM_ SG_ 761 gripper_timeout_error "a copy of the CAN watchdog error (Send_Watchdog), not a move timeout";
CM_ SG_ 761 gripper_estop_error "the E-stop bit of Send_gripper_data_pack (or #Gripstop 1) was set";
CM_ SG_ 761 gripper_calibrated "1 calibrated";
CM_ SG_ 772 Position_setpoint "encoder ticks";
CM_ SG_ 772 Speed_feedforward "encoder ticks/s";
CM_ SG_ 772 Current_feedforward "mA";
CM_ SG_ 776 Position_setpoint "encoder ticks";
CM_ SG_ 776 Speed_setpoint "encoder ticks/s";
CM_ SG_ 776 Current_feedforward "mA";
CM_ SG_ 830 Speed "encoder ticks/s; the sign gives the direction";
CM_ SG_ 830 Trigger "0 = trigger when the pin is low, 1 = when it is high, 2 = on any edge";
CM_ SG_ 774 position "encoder ticks";
CM_ SG_ 774 speed "encoder ticks/s";
CM_ SG_ 774 current "Iq in mA";
CM_ SG_ 775 position "encoder ticks";
CM_ SG_ 775 speed "encoder ticks/s";
CM_ SG_ 775 current "Iq in mA";
CM_ SG_ 832 position "encoder ticks";
CM_ SG_ 832 HALL_trigger "1 while the driver waits for the trigger (with a level trigger, also again after the pin left the level), 0 while it holds";
CM_ SG_ 832 additional_pin2 "the raw level of the ADDITIONAL2 pin";
CM_ SG_ 832 hall_index "1 once the trigger has been seen (latched)";
CM_ SG_ 833 position "encoder ticks";
CM_ SG_ 833 HALL_trigger "1 while the driver waits for the trigger (with a level trigger, also again after the pin left the level), 0 while it holds";
CM_ SG_ 833 additional_pin2 "the raw level of the ADDITIONAL2 pin";
CM_ SG_ 833 hall_index "1 once the trigger has been seen (latched)";
CM_ SG_ 808 Speed_limit "encoder ticks/s";
CM_ SG_ 808 Current_limit "mA";
CM_ SG_ 812 Kt "Nm/A";
CM_ SG_ 836 Voltage_limit "mV; 0 = Vbus";
CM_ SG_ 814 temperature "\u00b0C";
CM_ SG_ 815 temperature "\u00b0C";
CM_ SG_ 816 voltage "mV";
CM_ SG_ 817 voltage "mV";
CM_ SG_ 818 HARDWARE_VERSION "PCB revision";
CM_ SG_ 818 BATCH_DATE "production batch";
CM_ SG_ 818 SOFTWARE_VERSION "firmware release, e.g. 108";
CM_ SG_ 818 SERIAL_NUMBER "serial number as held in RAM: 1 after a power-up";
CM_ SG_ 819 HARDWARE_VERSION "PCB revision";
CM_ SG_ 819 BATCH_DATE "production batch";
CM_ SG_ 819 SOFTWARE_VERSION "firmware release, e.g. 108";
CM_ SG_ 819 SERIAL_NUMBER "serial number as held in RAM: 1 after a power-up";
CM_ SG_ 820 error "any error is active";
CM_ SG_ 820 temperature_error "motor over the temperature limit";
CM_ SG_ 820 encoder_error "the encoder reports no magnet (too weak a field)";
CM_ SG_ 820 vbus_error "supply voltage outside the limits";
CM_ SG_ 820 driver_error "reserved; never set by this firmware (STEPFOC does not read a fault output of its driver stage)";
CM_ SG_ 820 velocity_error "speed above 30,000,000 ticks/s, a fixed threshold (not #Vlimit)";
CM_ SG_ 820 current_error "reserved; never set by this firmware";
CM_ SG_ 820 estop_error "Send_ESTOP was received";
CM_ SG_ 820 calibrated "the motor is calibrated";
CM_ SG_ 820 activated "the controller is activated";
CM_ SG_ 820 watchdog_error "the watchdog ran out";
CM_ SG_ 820 wrong_product "from firmware 109: this firmware is on the other product's board (the product lock) and drives nothing";
CM_ SG_ 821 error "any error is active";
CM_ SG_ 821 temperature_error "motor over the temperature limit";
CM_ SG_ 821 encoder_error "the encoder reports no magnet (too weak a field)";
CM_ SG_ 821 vbus_error "supply voltage outside the limits";
CM_ SG_ 821 driver_error "reserved; never set by this firmware (STEPFOC does not read a fault output of its driver stage)";
CM_ SG_ 821 velocity_error "speed above 30,000,000 ticks/s, a fixed threshold (not #Vlimit)";
CM_ SG_ 821 current_error "reserved; never set by this firmware";
CM_ SG_ 821 estop_error "Send_ESTOP was received";
CM_ SG_ 821 calibrated "the motor is calibrated";
CM_ SG_ 821 activated "the controller is activated";
CM_ SG_ 821 watchdog_error "the watchdog ran out";
CM_ SG_ 821 wrong_product "from firmware 109: this firmware is on the other product's board (the product lock) and drives nothing";
CM_ SG_ 822 current "mA";
CM_ SG_ 823 current "mA";
CM_ SG_ 824 position "encoder ticks";
CM_ SG_ 824 speed "encoder ticks/s";
CM_ SG_ 825 position "encoder ticks";
CM_ SG_ 825 speed "encoder ticks/s";
CM_ SG_ 834 Kt "Nm/A";
CM_ SG_ 835 Kt "Nm/A";
CM_ SG_ 846 product "1 STEPFOC, 2 Spectral Micro: the firmware that answers";
CM_ SG_ 846 tool_id "parameter 1: 0 none, 1 SSG-48, 11-33 MSG, 200-254 your own";
CM_ SG_ 846 firmware_version "the release, e.g. 109";
CM_ SG_ 846 hardware_version "PCB revision from the EEPROM";
CM_ SG_ 846 pole_pairs "the motor's pole pairs; 0 if outside 0-255";
CM_ SG_ 846 calibrated "1 calibrated, 0 not";
CM_ SG_ 846 gripper "the driver is set up as a gripper (#Gripper 1)";
CM_ SG_ 846 brake_on_idle "idle brakes (1) or coasts (0)";
CM_ SG_ 846 commutation_reversed "calibration found the coils wired the other way round";
CM_ SG_ 846 settings_block2 "the EEPROM has the bank settings block 2 lives in, so parameters 1-5 can be saved";
CM_ SG_ 846 wrong_product "this firmware is on the other product's board (the product lock) and drives nothing";
CM_ SG_ 846 sense_zero_measured "the current-sense zero was measured at start-up and is plausible";
CM_ SG_ 846 cogging_saved "the anti-cogging in use is the one saved in the EEPROM";
CM_ SG_ 846 switching_zero_in_use "the current-sense zero measured with the bridge switching is in use (parameter 46)";
CM_ SG_ 847 product "1 STEPFOC, 2 Spectral Micro: the firmware that answers";
CM_ SG_ 847 tool_id "parameter 1: 0 none, 1 SSG-48, 11-33 MSG, 200-254 your own";
CM_ SG_ 847 firmware_version "the release, e.g. 109";
CM_ SG_ 847 hardware_version "PCB revision from the EEPROM";
CM_ SG_ 847 pole_pairs "the motor's pole pairs; 0 if outside 0-255";
CM_ SG_ 847 calibrated "1 calibrated, 0 not";
CM_ SG_ 847 gripper "the driver is set up as a gripper (#Gripper 1)";
CM_ SG_ 847 brake_on_idle "idle brakes (1) or coasts (0)";
CM_ SG_ 847 commutation_reversed "calibration found the coils wired the other way round";
CM_ SG_ 847 settings_block2 "the EEPROM has the bank settings block 2 lives in, so parameters 1-5 can be saved";
CM_ SG_ 847 wrong_product "this firmware is on the other product's board (the product lock) and drives nothing";
CM_ SG_ 847 sense_zero_measured "the current-sense zero was measured at start-up and is plausible";
CM_ SG_ 847 cogging_saved "the anti-cogging in use is the one saved in the EEPROM";
CM_ SG_ 847 switching_zero_in_use "the current-sense zero measured with the bridge switching is in use (parameter 46)";
CM_ SG_ 848 temperature "\u00b0C (meaningful with the thermistor enabled)";
CM_ SG_ 848 voltage "supply voltage in mV";
CM_ SG_ 848 errors_1 "the error flags, as byte 0 of Send_Respond_State_of_Errors";
CM_ SG_ 848 errors_2 "calibrated, activated, watchdog, wrong product, as byte 1 of Send_Respond_State_of_Errors";
CM_ SG_ 848 current "Iq in mA";
CM_ SG_ 849 temperature "\u00b0C (meaningful with the thermistor enabled)";
CM_ SG_ 849 voltage "supply voltage in mV";
CM_ SG_ 849 errors_1 "the error flags, as byte 0 of Send_Respond_State_of_Errors";
CM_ SG_ 849 errors_2 "calibrated, activated, watchdog, wrong product, as byte 1 of Send_Respond_State_of_Errors";
CM_ SG_ 849 current "Iq in mA";
CM_ SG_ 790 ID "0 to 13; 14 and 15 are accepted but reserved by the bootloader";
CM_ SG_ 798 Time "ms; 0 = off";
CM_ SG_ 798 Action "0 legacy (brake or coast as idle does), 1 hold the position, 2 brake, 3 coast, 4 descend at the fallback current and speed; other values act as 0";
CM_ SG_ 828 Interval "ms; 0 = off";
CM_ SG_ 838 Mask "bit 0 = write the idle behaviour";
CM_ SG_ 838 Value "bit 0: 1 brake, 0 coast";
CM_ SG_ 840 Parameter "the parameter number, 1-87";
CM_ SG_ 840 Value "the new value, in the parameter's unit; for the gains, limits and Kt (8-16, 20) a float's bit pattern";
CM_ SG_ 842 Parameter "the parameter number";
CM_ SG_ 844 parameter "the parameter number";
CM_ SG_ 844 value "the value in force; a float's bits for 8-16 and 20";
CM_ SG_ 845 parameter "the parameter number";
CM_ SG_ 845 value "the value in force; a float's bits for 8-16 and 20";
CM_ SG_ 850 Kind "0 capture (up to 1024 samples: parameter 32 says how many), 1 histogram (256 bins), 2 anti-cogging harmonics (8 slots), 3 anti-cogging table (256 values), 4 encoder table (128 values)";
CM_ SG_ 850 First "the first index";
CM_ SG_ 850 Count "how many entries; 0 cancels a read-out";
CM_ SG_ 852 header "kind \u00d7 8192 + index";
CM_ SG_ 852 word_a "capture: channel A; histogram: the count (unsigned); harmonics: the harmonic number (0 = slot unused); tables: entry index";
CM_ SG_ 852 word_b "capture: channel B; histogram: the sum's upper 16 bits; harmonics: a, the cosine term in mA; tables: entry index + 1";
CM_ SG_ 852 word_c "capture: channel C; histogram: the sum's lower 16 bits; harmonics: b, the sine term in mA; tables: entry index + 2 (0 past the end)";
CM_ SG_ 853 header "kind \u00d7 8192 + index";
CM_ SG_ 853 word_a "capture: channel A; histogram: the count (unsigned); harmonics: the harmonic number (0 = slot unused); tables: entry index";
CM_ SG_ 853 word_b "capture: channel B; histogram: the sum's upper 16 bits; harmonics: a, the cosine term in mA; tables: entry index + 1";
CM_ SG_ 853 word_c "capture: channel C; histogram: the sum's lower 16 bits; harmonics: b, the sine term in mA; tables: entry index + 2 (0 past the end)";
CM_ SG_ 854 Header "kind \u00d7 8192 + index; kind 2 or 3";
CM_ SG_ 854 Word_A "kind 2: the harmonic (1-32, 0 = unused); kind 3: value at index";
CM_ SG_ 854 Word_B "kind 2: a in mA; kind 3: value at index + 1";
CM_ SG_ 854 Word_C "kind 2: b in mA; kind 3: value at index + 2";
CM_ SG_ 856 Operation "0 stop everything (tones, queue, samples); 1 a tone now; 2 add an event to the queue; 3 play the queue; 4 play the samples; 5 samples off, buffer cleared; 6 clear the queue (tones that sound keep sounding)";
CM_ SG_ 856 Channel "the tone channel, 0-3 (operations 1 and 2)";
CM_ SG_ 856 A "1, 2: the pitch in Hz (2: 0 silences the channel); 4: the sample rate in Hz, at most the loop rate";
CM_ SG_ 856 B "1, 2: the loudness in mA; 4: the voltage of a full-scale sample in mV";
CM_ SG_ 856 C "1: the duration in ms, 0 = until stopped; 2: the wait in ms before the next event, 0 = the next one starts with it";
CM_ SG_ 858 Sample_1 "the next sample";
CM_ SG_ 890 Position "0 fully open, 255 fully closed";
CM_ SG_ 890 Speed "0 slowest, 255 fastest";
CM_ SG_ 890 Current "current limit of the move in mA; from firmware 109 the move uses its magnitude, at most the driver's 2800 mA; see the gripper manual for the safe range";
CM_ SG_ 890 Activate "1 activate the gripper, 0 deactivate";
CM_ SG_ 890 Action "1 go to the position, 0 idle";
CM_ SG_ 890 E_stop "1 raises the gripper E-stop error, again on every control cycle until a frame with this bit 0 arrives; then Send_Clear_Error";
CM_ SG_ 890 Release_direction "read by the firmware but not used";
CM_ SG_ 888 gripper_position "0 fully open, 255 fully closed";
CM_ SG_ 888 gripper_current "measured current in mA";
CM_ SG_ 888 gripper_activated "1 activated";
CM_ SG_ 888 gripper_action_status "the action bit of the last Send_gripper_data_pack (1 after #Grippos); the driver never clears it, so it stays 1 after the move ends: the object detection tells when the move has ended";
CM_ SG_ 888 gripper_object_detection_raw "bit 5 is the low bit, bit 4 the high bit: 0 moving, 1 object detected while closing, 2 object detected while opening, 3 at the position; raw bit pair, see value labels (wire order differs from numeric status)";
CM_ SG_ 888 gripper_temperature_error "a copy of the thermistor temperature error";
CM_ SG_ 888 gripper_timeout_error "a copy of the CAN watchdog error (Send_Watchdog), not a move timeout";
CM_ SG_ 888 gripper_estop_error "the E-stop bit of Send_gripper_data_pack (or #Gripstop 1) was set";
CM_ SG_ 888 gripper_calibrated "1 calibrated";
CM_ SG_ 889 gripper_position "0 fully open, 255 fully closed";
CM_ SG_ 889 gripper_current "measured current in mA";
CM_ SG_ 889 gripper_activated "1 activated";
CM_ SG_ 889 gripper_action_status "the action bit of the last Send_gripper_data_pack (1 after #Grippos); the driver never clears it, so it stays 1 after the move ends: the object detection tells when the move has ended";
CM_ SG_ 889 gripper_object_detection_raw "bit 5 is the low bit, bit 4 the high bit: 0 moving, 1 object detected while closing, 2 object detected while opening, 3 at the position; raw bit pair, see value labels (wire order differs from numeric status)";
CM_ SG_ 889 gripper_temperature_error "a copy of the thermistor temperature error";
CM_ SG_ 889 gripper_timeout_error "a copy of the CAN watchdog error (Send_Watchdog), not a move timeout";
CM_ SG_ 889 gripper_estop_error "the E-stop bit of Send_gripper_data_pack (or #Gripstop 1) was set";
CM_ SG_ 889 gripper_calibrated "1 calibrated";
CM_ SG_ 900 Position_setpoint "encoder ticks";
CM_ SG_ 900 Speed_feedforward "encoder ticks/s";
CM_ SG_ 900 Current_feedforward "mA";
CM_ SG_ 904 Position_setpoint "encoder ticks";
CM_ SG_ 904 Speed_setpoint "encoder ticks/s";
CM_ SG_ 904 Current_feedforward "mA";
CM_ SG_ 958 Speed "encoder ticks/s; the sign gives the direction";
CM_ SG_ 958 Trigger "0 = trigger when the pin is low, 1 = when it is high, 2 = on any edge";
CM_ SG_ 902 position "encoder ticks";
CM_ SG_ 902 speed "encoder ticks/s";
CM_ SG_ 902 current "Iq in mA";
CM_ SG_ 903 position "encoder ticks";
CM_ SG_ 903 speed "encoder ticks/s";
CM_ SG_ 903 current "Iq in mA";
CM_ SG_ 960 position "encoder ticks";
CM_ SG_ 960 HALL_trigger "1 while the driver waits for the trigger (with a level trigger, also again after the pin left the level), 0 while it holds";
CM_ SG_ 960 additional_pin2 "the raw level of the ADDITIONAL2 pin";
CM_ SG_ 960 hall_index "1 once the trigger has been seen (latched)";
CM_ SG_ 961 position "encoder ticks";
CM_ SG_ 961 HALL_trigger "1 while the driver waits for the trigger (with a level trigger, also again after the pin left the level), 0 while it holds";
CM_ SG_ 961 additional_pin2 "the raw level of the ADDITIONAL2 pin";
CM_ SG_ 961 hall_index "1 once the trigger has been seen (latched)";
SIG_VALTYPE_ 32 KP : 1;
SIG_VALTYPE_ 32 KD : 1;
SIG_VALTYPE_ 34 Kp_iq : 1;
SIG_VALTYPE_ 34 Ki_iq : 1;
SIG_VALTYPE_ 36 Kpv : 1;
SIG_VALTYPE_ 36 Kiv : 1;
SIG_VALTYPE_ 38 Kpp : 1;
SIG_VALTYPE_ 40 Speed_limit : 1;
SIG_VALTYPE_ 40 Current_limit : 1;
SIG_VALTYPE_ 44 Kt : 1;
SIG_VALTYPE_ 66 Kt : 1;
SIG_VALTYPE_ 67 Kt : 1;
SIG_VALTYPE_ 160 KP : 1;
SIG_VALTYPE_ 160 KD : 1;
SIG_VALTYPE_ 162 Kp_iq : 1;
SIG_VALTYPE_ 162 Ki_iq : 1;
SIG_VALTYPE_ 164 Kpv : 1;
SIG_VALTYPE_ 164 Kiv : 1;
SIG_VALTYPE_ 166 Kpp : 1;
SIG_VALTYPE_ 168 Speed_limit : 1;
SIG_VALTYPE_ 168 Current_limit : 1;
SIG_VALTYPE_ 172 Kt : 1;
SIG_VALTYPE_ 194 Kt : 1;
SIG_VALTYPE_ 195 Kt : 1;
SIG_VALTYPE_ 288 KP : 1;
SIG_VALTYPE_ 288 KD : 1;
SIG_VALTYPE_ 290 Kp_iq : 1;
SIG_VALTYPE_ 290 Ki_iq : 1;
SIG_VALTYPE_ 292 Kpv : 1;
SIG_VALTYPE_ 292 Kiv : 1;
SIG_VALTYPE_ 294 Kpp : 1;
SIG_VALTYPE_ 296 Speed_limit : 1;
SIG_VALTYPE_ 296 Current_limit : 1;
SIG_VALTYPE_ 300 Kt : 1;
SIG_VALTYPE_ 322 Kt : 1;
SIG_VALTYPE_ 323 Kt : 1;
SIG_VALTYPE_ 416 KP : 1;
SIG_VALTYPE_ 416 KD : 1;
SIG_VALTYPE_ 418 Kp_iq : 1;
SIG_VALTYPE_ 418 Ki_iq : 1;
SIG_VALTYPE_ 420 Kpv : 1;
SIG_VALTYPE_ 420 Kiv : 1;
SIG_VALTYPE_ 422 Kpp : 1;
SIG_VALTYPE_ 424 Speed_limit : 1;
SIG_VALTYPE_ 424 Current_limit : 1;
SIG_VALTYPE_ 428 Kt : 1;
SIG_VALTYPE_ 450 Kt : 1;
SIG_VALTYPE_ 451 Kt : 1;
SIG_VALTYPE_ 544 KP : 1;
SIG_VALTYPE_ 544 KD : 1;
SIG_VALTYPE_ 546 Kp_iq : 1;
SIG_VALTYPE_ 546 Ki_iq : 1;
SIG_VALTYPE_ 548 Kpv : 1;
SIG_VALTYPE_ 548 Kiv : 1;
SIG_VALTYPE_ 550 Kpp : 1;
SIG_VALTYPE_ 552 Speed_limit : 1;
SIG_VALTYPE_ 552 Current_limit : 1;
SIG_VALTYPE_ 556 Kt : 1;
SIG_VALTYPE_ 578 Kt : 1;
SIG_VALTYPE_ 579 Kt : 1;
SIG_VALTYPE_ 672 KP : 1;
SIG_VALTYPE_ 672 KD : 1;
SIG_VALTYPE_ 674 Kp_iq : 1;
SIG_VALTYPE_ 674 Ki_iq : 1;
SIG_VALTYPE_ 676 Kpv : 1;
SIG_VALTYPE_ 676 Kiv : 1;
SIG_VALTYPE_ 678 Kpp : 1;
SIG_VALTYPE_ 680 Speed_limit : 1;
SIG_VALTYPE_ 680 Current_limit : 1;
SIG_VALTYPE_ 684 Kt : 1;
SIG_VALTYPE_ 706 Kt : 1;
SIG_VALTYPE_ 707 Kt : 1;
SIG_VALTYPE_ 800 KP : 1;
SIG_VALTYPE_ 800 KD : 1;
SIG_VALTYPE_ 802 Kp_iq : 1;
SIG_VALTYPE_ 802 Ki_iq : 1;
SIG_VALTYPE_ 804 Kpv : 1;
SIG_VALTYPE_ 804 Kiv : 1;
SIG_VALTYPE_ 806 Kpp : 1;
SIG_VALTYPE_ 808 Speed_limit : 1;
SIG_VALTYPE_ 808 Current_limit : 1;
SIG_VALTYPE_ 812 Kt : 1;
SIG_VALTYPE_ 834 Kt : 1;
SIG_VALTYPE_ 835 Kt : 1;
VAL_ 120 gripper_object_detection_raw 0 "moving" 1 "object while opening" 2 "object while closing" 3 "at position";
VAL_ 121 gripper_object_detection_raw 0 "moving" 1 "object while opening" 2 "object while closing" 3 "at position";
VAL_ 248 gripper_object_detection_raw 0 "moving" 1 "object while opening" 2 "object while closing" 3 "at position";
VAL_ 249 gripper_object_detection_raw 0 "moving" 1 "object while opening" 2 "object while closing" 3 "at position";
VAL_ 376 gripper_object_detection_raw 0 "moving" 1 "object while opening" 2 "object while closing" 3 "at position";
VAL_ 377 gripper_object_detection_raw 0 "moving" 1 "object while opening" 2 "object while closing" 3 "at position";
VAL_ 504 gripper_object_detection_raw 0 "moving" 1 "object while opening" 2 "object while closing" 3 "at position";
VAL_ 505 gripper_object_detection_raw 0 "moving" 1 "object while opening" 2 "object while closing" 3 "at position";
VAL_ 632 gripper_object_detection_raw 0 "moving" 1 "object while opening" 2 "object while closing" 3 "at position";
VAL_ 633 gripper_object_detection_raw 0 "moving" 1 "object while opening" 2 "object while closing" 3 "at position";
VAL_ 760 gripper_object_detection_raw 0 "moving" 1 "object while opening" 2 "object while closing" 3 "at position";
VAL_ 761 gripper_object_detection_raw 0 "moving" 1 "object while opening" 2 "object while closing" 3 "at position";
VAL_ 888 gripper_object_detection_raw 0 "moving" 1 "object while opening" 2 "object while closing" 3 "at position";
VAL_ 889 gripper_object_detection_raw 0 "moving" 1 "object while opening" 2 "object while closing" 3 "at position";
